VERSION ""

NS_ :

BS_:

BU_:

BO_ 58 SrlDat36_Prtctd_PDU: 20 Vector__XXX
 SG_ SD36P_MAC : 7|32@0+ (1,0) [0|4.29497e+009] "" ACP2_MCU,EOCM,EOCM_HC_Superset,FCM,E44
 SG_ SD36P_FCnt : 39|5@0+ (1,0) [0|31] "" ACP2_MCU,EOCM,EOCM_HC_Superset,FCM,E44
 SG_ DASTP_StrTrqAuth : 47|11@0- (0.01,0) [-10.24|10.23] "Nm" ACP2_MCU,EOCM,EOCM_HC_Superset,FCM,E44,ECP_E
 SG_ EPSOP_EPSOvrlyTrqDlvdAuth : 49|11@0- (0.01,0) [-10.24|10.23] "" ACP2_MCU,EOCM,EOCM_HC_Superset,FCM,E44
 SG_ DSIDP_DrvrStrgIntfrDtdAuth_Inv : 50|1@0+ (1,0) [0|1] "" ACP2_MCU,EOCM,EOCM_HC_Superset,FCM,E44
 SG_ DSIDP_DrvrStrgIntfrDtdAuth : 51|1@0+ (1,0) [0|1] "" ACP2_MCU,EOCM,EOCM_HC_Superset,FCM,E44
 SG_ DASTP_StrTrqAuth_Inv : 52|1@0+ (1,0) [0|1] "" ACP2_MCU,EOCM,EOCM_HC_Superset,FCM,E44,ECP_E
 SG_ EPSTTDP_TotTorqDlvdAuth : 66|11@0- (0.25,0) [-256|255.75] "" ACP2_MCU,EOCM,EOCM_HC_Superset,FCM,E44,ECP_E
 SG_ EPSOP_ElecPwStrgTqOvlyStsAuth : 69|3@0+ (1,0) [0|5] "" ACP2_MCU,EOCM,EOCM_HC_Superset,FCM,E44
 SG_ EPSOP_EPSOvrlyTrqDlvdAuth_Inv : 70|1@0+ (1,0) [0|1] "" ACP2_MCU,EOCM,EOCM_HC_Superset,FCM,E44
 SG_ SSASI2P_LKAStrgRqCommStsAuth : 81|2@0+ (1,0) [0|3] "" ACP2_MCU,EOCM,EOCM_HC_Superset,FCM,E44
 SG_ SSASI2P_ArbdASStrgRqCommStsAuth : 84|3@0+ (1,0) [0|5] "" ACP2_MCU,EOCM,EOCM_HC_Superset,FCM,E44
 SG_ SSASI2P_AE44StrgRqCommStsAuth : 86|2@0+ (1,0) [0|3] "" ACP2_MCU,EOCM,EOCM_HC_Superset,FCM,E44
 SG_ EPSTTDP_TotTorqDlvdAuth_Inv : 87|1@0+ (1,0) [0|1] "" ACP2_MCU,EOCM,EOCM_HC_Superset,FCM,E44,ECP_E
 SG_ SSASIP_StrgTrqReqOvlyAvalLtAuth : 89|10@0+ (0.01,0) [0|10.23] "Nm" ACP2_MCU,EOCM,EOCM_HC_Superset,FCM,E44
 SG_ SSASIP_StrgPerfActlModeAuth : 92|3@0+ (1,0) [0|7] "" ACP2_MCU,EOCM,EOCM_HC_Superset,FCM,E44
 SG_ SSASIP_StrgAsstThrmlInhbdAuth : 93|1@0+ (1,0) [0|1] "" ACP2_MCU,EOCM,EOCM_HC_Superset,FCM,E44
 SG_ SSASIP_StrgAsstStsAuth : 95|2@0+ (1,0) [0|2] "" ACP2_MCU,EOCM,EOCM_HC_Superset,FCM,E44
 SG_ SSASIP_StrgTrqReqOvlyAvalRtAuth : 111|10@0+ (0.01,-10.23) [-10.23|0] "Nm" ACP2_MCU,EOCM,EOCM_HC_Superset,FCM,E44
 SG_ SWHOP_ArbdStrgFtrReqActvAuth : 113|4@0+ (1,0) [0|10] "" ACP2_MCU,EOCM,EOCM_HC_Superset,FCM,E44
 SG_ SSASIP_StrgWhlTrqIntegStsAuth : 115|2@0+ (1,0) [0|3] "" ACP2_MCU,EOCM,EOCM_HC_Superset,FCM,E44
 SG_ SSASIP_StrgWhlAngIntegStsAuth : 117|2@0+ (1,0) [0|3] "" ACP2_MCU,EOCM,EOCM_HC_Superset,FCM,E44
 SG_ SWHOP_StrgWhlHndsOffDtnStatAuth : 121|2@0+ (1,0) [0|2] "" ACP2_MCU,EOCM,EOCM_HC_Superset,FCM,E44
 SG_ SWHOP_StrgWhlHndsOffDtnModeAuth : 123|2@0+ (1,0) [0|3] "" ACP2_MCU,EOCM,EOCM_HC_Superset,FCM,E44
 SG_ SWHOP_StrgWhlHndsOffDtnCnfdLvlAu : 125|2@0+ (1,0) [0|2] "" ACP2_MCU,EOCM,EOCM_HC_Superset,FCM,E44
 SG_ SD36P_Filler : 133|30@0+ (1,0) [0|1.07374e+009] "" ACP2_MCU,EOCM,EOCM_HC_Superset,FCM,E44
 SG_ SD36P_ARC : 135|2@0+ (1,0) [0|3] "" ACP2_MCU,EOCM,EOCM_HC_Superset,FCM,E44

BO_ 900 Message1126_PDU: 8 Vector__XXX
 SG_ Sig6868 : 7|64@0+ (1,0) [0|1.84467e+019] "" ADIMa,ADIMb,FOPM

BO_ 90 Message1127_PDU: 20 Vector__XXX
 SG_ Sig5735 : 7|32@0+ (1,0) [0|4.29497e+009] "" ADIMa,ADIMb,FOPM
 SG_ Sig5733 : 39|5@0+ (1,0) [0|31] "" ADIMa,ADIMb,FOPM
 SG_ Sig0315 : 47|13@0- (0.0625,0) [-256|255.938] "Amp" ADIMa,ADIMb,FOPM
 SG_ Sig0320 : 50|13@0+ (0.1,0) [0|819.1] "Deg" ADIMa,ADIMb,FOPM
 SG_ Sig0327 : 69|12@0+ (10,0) [0|40950] "N" ADIMa,ADIMb,FOPM
 SG_ Sig0323 : 73|11@0+ (2,0) [0|4094] "deg/s" ADIMa,ADIMb,FOPM
 SG_ Sig2544 : 94|11@0- (0.25,0) [-256|255.75] "" ADIMa,ADIMb,FOPM
 SG_ Sig0317 : 99|8@0+ (0.1,0) [0|25.5] "volts" ADIMa,ADIMb,FOPM
 SG_ Sig0319 : 104|3@0+ (1,0) [0|7] "" ADIMa,ADIMb,FOPM
 SG_ Sig0313 : 107|3@0+ (1,0) [0|5] "" ADIMa,ADIMb,FOPM
 SG_ Sig0325 : 112|2@0+ (1,0) [0|3] "" ADIMa,ADIMb,FOPM
 SG_ Sig0322 : 114|2@0+ (1,0) [0|3] "" ADIMa,ADIMb,FOPM
 SG_ Sig6953 : 117|3@0+ (1,0) [0|5] "" ADIMa,ADIMb,FOPM
 SG_ Sig0318 : 120|1@0+ (1,0) [0|1] "" ADIMa,ADIMb,FOPM
 SG_ Sig0316 : 121|1@0+ (1,0) [0|1] "" ADIMa,ADIMb,FOPM
 SG_ Sig0314 : 122|1@0+ (1,0) [0|1] "" ADIMa,ADIMb,FOPM
 SG_ Sig6956 : 124|2@0+ (1,0) [0|2] "" ADIMa,ADIMb,FOPM
 SG_ Sig0328 : 126|2@0+ (1,0) [0|3] "" ADIMa,ADIMb,FOPM
 SG_ Sig5734 : 131|26@0+ (1,0) [0|6.71089e+007] "" ADIMa,ADIMb,FOPM
 SG_ Sig2545 : 132|1@0+ (1,0) [0|1] "" ADIMa,ADIMb,FOPM
 SG_ Sig0326 : 133|1@0+ (1,0) [0|1] "" ADIMa,ADIMb,FOPM
 SG_ Sig0324 : 134|1@0+ (1,0) [0|1] "" ADIMa,ADIMb,FOPM
 SG_ Sig0321 : 135|1@0+ (1,0) [0|1] "" ADIMa,ADIMb,FOPM
 SG_ Sig5732 : 153|2@0+ (1,0) [0|3] "" ADIMa,ADIMb,FOPM

BO_ 1373 SrlDat3_PCSM_PDU: 8 Vector__XXX
 SG_ SrlDat3_PCSM : 7|64@0+ (1,0) [0|1.84467e+019] "" ACP2_MCU,ECM,EOCM,EOCM_HC_Superset,FCM,PCM,TCCM

BO_ 876 SrlDat3_Prtctd_PDU: 16 Vector__XXX
 SG_ SD3_MAC : 7|32@0+ (1,0) [0|4.29497e+009] "" ACP2_MCU,ECM,EOCM,EOCM_HC_Superset,FCM,PCM,TCCM
 SG_ SD3_FCnt : 39|5@0+ (1,0) [0|31] "" ACP2_MCU,ECM,EOCM,EOCM_HC_Superset,FCM,PCM,TCCM
 SG_ BVSCP_BdyCtlTopSpdLimReqTypAuth : 42|3@0+ (1,0) [0|6] "" ACP2_MCU,ECM,EOCM,EOCM_HC_Superset,FCM,PCM,TCCM
 SG_ BGI4P_AutoShtdnRstAuth : 43|1@0+ (1,0) [0|1] "" ACP2_MCU,ECM,EOCM,EOCM_HC_Superset,FCM,PCM,TCCM
 SG_ BGI4P_AutoShtdnAllwdAuth : 44|1@0+ (1,0) [0|1] "" ACP2_MCU,ECM,EOCM,EOCM_HC_Superset,FCM,PCM,TCCM
 SG_ BGI4P_AirDflctOffCycCrTkStAuth : 46|2@0+ (1,0) [0|3] "" ACP2_MCU,ECM,EOCM,EOCM_HC_Superset,FCM,PCM,TCCM
 SG_ BASHPLP_BrkSnsrHmPstnLrndAuth : 47|1@0+ (1,0) [0|1] "" ACP2_MCU,ECM,EOCM,EOCM_HC_Superset,FCM,PCM,TCCM
 SG_ BVSCP_BdyCtlTopSpdLimReqValAuth : 55|8@0+ (1,0) [0|255] "kph" ACP2_MCU,ECM,EOCM,EOCM_HC_Superset,FCM,PCM,TCCM
 SG_ DSIP_E44MSw3StkAuth : 56|1@0+ (1,0) [0|1] "" ACP2_MCU,ECM,EOCM,EOCM_HC_Superset,FCM,PCM,TCCM
 SG_ DSIP_E44MSw2StkAuth : 57|1@0+ (1,0) [0|1] "" ACP2_MCU,ECM,EOCM,EOCM_HC_Superset,FCM,PCM,TCCM
 SG_ DSIP_E44MSw1StkAuth : 58|1@0+ (1,0) [0|1] "" ACP2_MCU,ECM,EOCM,EOCM_HC_Superset,FCM,PCM,TCCM
 SG_ BdyCtlTopSpdLimSrcAuth : 61|3@0+ (1,0) [0|7] "" ACP2_MCU,ECM,EOCM,EOCM_HC_Superset,FCM,PCM,TCCM
 SG_ BdyCtlTopSpdLimIndOnAuth : 62|1@0+ (1,0) [0|1] "" ACP2_MCU,ECM,EOCM,EOCM_HC_Superset,FCM,PCM,TCCM
 SG_ BdyCtlAccelLimIndOnAuth : 63|1@0+ (1,0) [0|1] "" ACP2_MCU,ECM,EOCM,EOCM_HC_Superset,FCM,PCM,TCCM
 SG_ VCKIP_InfltblRstrntKeyIdfrAuth : 64|16@0+ (1,0) [0|65535] "Hex" ACP2_MCU,ECM,EOCM,EOCM_HC_Superset,FCM,PCM,TCCM
 SG_ RIP_FrtCmptRelEnblReqAuth : 66|2@0+ (1,0) [0|3] "" ACP2_MCU,ECM,EOCM,EOCM_HC_Superset,FCM,PCM,TCCM
 SG_ DSIP_E44MSwStsAuth : 69|3@0+ (1,0) [0|7] "" ACP2_MCU,ECM,EOCM,EOCM_HC_Superset,FCM,PCM,TCCM
 SG_ DSIP_E44MSwDrvrModeSwStkAuth : 70|1@0+ (1,0) [0|1] "" ACP2_MCU,ECM,EOCM,EOCM_HC_Superset,FCM,PCM,TCCM
 SG_ DSIP_E44MSw4StkAuth : 71|1@0+ (1,0) [0|1] "" ACP2_MCU,ECM,EOCM,EOCM_HC_Superset,FCM,PCM,TCCM
 SG_ SD3_ARC : 80|2@0+ (1,0) [0|3] "" ACP2_MCU,ECM,EOCM,EOCM_HC_Superset,FCM,PCM,TCCM
 SG_ SD3P_Filler : 93|31@0+ (1,0) [0|2.14748e+009] "" ACP2_MCU,ECM,EOCM,EOCM_HC_Superset,FCM,PCM,TCCM
 SG_ LoVltg12VBatMntModeReqd : 94|1@0+ (1,0) [0|1] "" ACP2_MCU,ECM,EOCM,EOCM_HC_Superset,FCM,PCM,TCCM
 SG_ SD3P_FillerExtnd : 126|7@0+ (1,0) [0|127] "" ACP2_MCU,ECM,EOCM,EOCM_HC_Superset,FCM,PCM,TCCM

BO_ 899 SrlDat40_PCSM_PDU: 8 Vector__XXX
 SG_ SrlDat40_PCSM : 7|64@0+ (1,0) [0|1.84467e+019] "" EBCM,EPS,EPSb

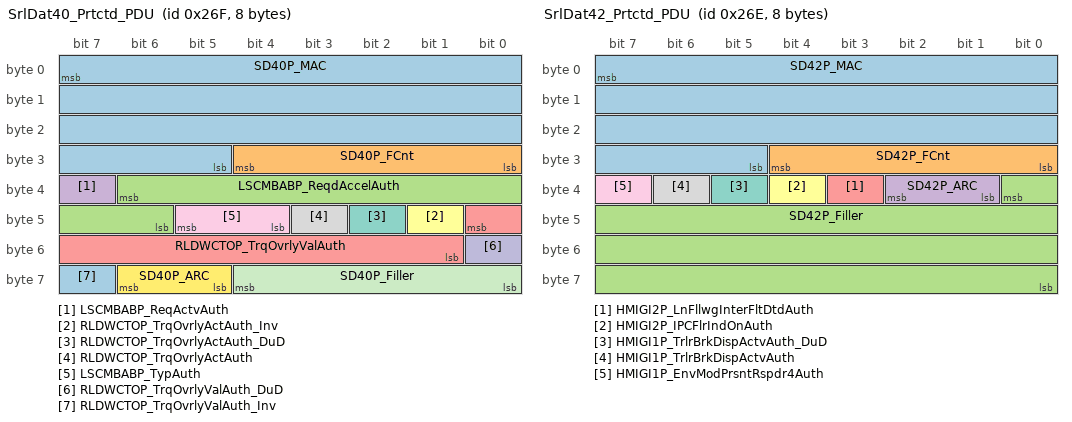
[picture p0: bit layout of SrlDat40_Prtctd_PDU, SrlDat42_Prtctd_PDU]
BO_ 623 SrlDat40_Prtctd_PDU: 8 Vector__XXX
 SG_ SD40P_MAC : 7|27@0+ (1,0) [0|1.34218e+008] "" CGM,EBCM,EPS,EPSb
 SG_ SD40P_FCnt : 28|5@0+ (1,0) [0|31] "" CGM,EBCM,EPS,EPSb
 SG_ LSCMBABP_ReqdAccelAuth : 38|9@0- (0.1,0) [-25.6|25.5] "" CGM,EBCM,EPS,EPSb
 SG_ LSCMBABP_ReqActvAuth : 39|1@0+ (1,0) [0|1] "" CGM,EBCM,EPS,EPSb
 SG_ RLDWCTOP_TrqOvrlyValAuth : 40|8@0- (0.1,0) [-12.8|12.7] "" CGM,EBCM,EPS,EPSb
 SG_ RLDWCTOP_TrqOvrlyActAuth_Inv : 41|1@0+ (1,0) [0|1] "" CGM,EBCM,EPS,EPSb
 SG_ RLDWCTOP_TrqOvrlyActAuth_DuD : 42|1@0+ (1,0) [0|1] "" CGM,EBCM,EPS,EPSb
 SG_ RLDWCTOP_TrqOvrlyActAuth : 43|1@0+ (1,0) [0|1] "" CGM,EBCM,EPS,EPSb
 SG_ LSCMBABP_TypAuth : 45|2@0+ (1,0) [0|2] "" CGM,EBCM,EPS,EPSb
 SG_ RLDWCTOP_TrqOvrlyValAuth_DuD : 48|1@0+ (1,0) [0|1] "" CGM,EBCM,EPS,EPSb
 SG_ SD40P_Filler : 60|5@0+ (1,0) [0|31] "" CGM,EBCM,EPS,EPSb
 SG_ SD40P_ARC : 62|2@0+ (1,0) [0|3] "" CGM,EBCM,EPS,EPSb
 SG_ RLDWCTOP_TrqOvrlyValAuth_Inv : 63|1@0+ (1,0) [0|1] "" CGM,EBCM,EPS,EPSb

BO_ 898 SrlDat42_PCSM_PDU: 8 Vector__XXX
 SG_ SrlDat42_PCSM : 7|64@0+ (1,0) [0|1.84467e+019] "" ACP2_MCU,EBCM,EOCM,EOCM_HC_Superset

BO_ 622 SrlDat42_Prtctd_PDU: 8 Vector__XXX
 SG_ SD42P_MAC : 7|27@0+ (1,0) [0|1.34218e+008] "" ACP2_MCU,EBCM,EOCM,EOCM_HC_Superset
 SG_ SD42P_FCnt : 28|5@0+ (1,0) [0|31] "" ACP2_MCU,EBCM,EOCM,EOCM_HC_Superset
 SG_ SD42P_Filler : 32|25@0+ (1,0) [0|3.35544e+007] "" ACP2_MCU,EBCM,EOCM,EOCM_HC_Superset
 SG_ SD42P_ARC : 34|2@0+ (1,0) [0|3] "" ACP2_MCU,EBCM,EOCM,EOCM_HC_Superset
 SG_ HMIGI2P_LnFllwgInterFltDtdAuth : 35|1@0+ (1,0) [0|1] "" ACP2_MCU,EBCM,EOCM,EOCM_HC_Superset
 SG_ HMIGI2P_IPCFlrIndOnAuth : 36|1@0+ (1,0) [0|1] "" ACP2_MCU,EBCM,EOCM,EOCM_HC_Superset
 SG_ HMIGI1P_TrlrBrkDispActvAuth_DuD : 37|1@0+ (1,0) [0|1] "" ACP2_MCU,EBCM,EOCM,EOCM_HC_Superset
 SG_ HMIGI1P_TrlrBrkDispActvAuth : 38|1@0+ (1,0) [0|1] "" ACP2_MCU,EBCM,EOCM,EOCM_HC_Superset
 SG_ HMIGI1P_EnvModPrsntRspdr4Auth : 39|1@0+ (1,0) [0|1] "" ACP2_MCU,EBCM,EOCM,EOCM_HC_Superset

BO_ 1372 SrlDat43_PCSM_PDU: 8 Vector__XXX
 SG_ SrlDat43_PCSM : 7|64@0+ (1,0) [0|1.84467e+019] "" ECM,PCM,ECP_E

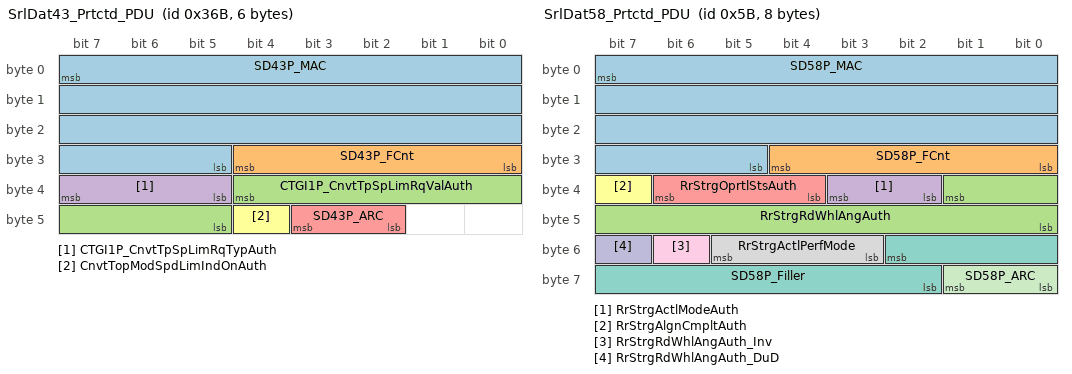
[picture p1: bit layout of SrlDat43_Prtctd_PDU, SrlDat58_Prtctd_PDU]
BO_ 875 SrlDat43_Prtctd_PDU: 6 Vector__XXX
 SG_ SD43P_MAC : 7|27@0+ (1,0) [0|1.34218e+008] "" ECM,PCM,ECP_E
 SG_ SD43P_FCnt : 28|5@0+ (1,0) [0|31] "" ECM,PCM,ECP_E
 SG_ CTGI1P_CnvtTpSpLimRqValAuth : 36|8@0+ (2,0) [0|510] "kph" ECM,PCM,ECP_E
 SG_ CTGI1P_CnvtTpSpLimRqTypAuth : 39|3@0+ (1,0) [0|6] "" ECM,PCM,ECP_E
 SG_ SD43P_ARC : 43|2@0+ (1,0) [0|3] "" ECM,PCM,ECP_E
 SG_ CnvtTopModSpdLimIndOnAuth : 44|1@0+ (1,0) [0|1] "" ECM,PCM,ECP_E

BO_ 664 SrlDat44_PCSM_PDU: 8 Vector__XXX
 SG_ SrlDat44_PCSM : 7|64@0+ (1,0) [0|1.84467e+019] "" ECP_E

BO_ 53 SrlDat44_Prtctd_PDU: 24 Vector__XXX
 SG_ SD44P_MAC : 7|32@0+ (1,0) [0|4.29497e+009] "" ECP_E
 SG_ SD44P_FCnt : 39|5@0+ (1,0) [0|31] "" ECP_E
 SG_ SSID1P_LatAccelAuth : 47|10@0- (0.0625,0) [-32|31.9375] "m/s2" ECP_E
 SG_ SSID1P_LngAccelAuth : 52|10@0- (0.0625,0) [-32|31.9375] "m/s2" ECP_E
 SG_ SSID1P_LatAccelAuth_Inv : 53|1@0+ (1,0) [0|1] "" ECP_E
 SG_ SSID2P_PtchRateAuth : 57|12@0- (0.061,0) [-124.928|124.867] "deg/sec" ECP_E
 SG_ SSID1P_LngAccelAuth_Inv : 58|1@0+ (1,0) [0|1] "" ECP_E
 SG_ SSID2P_VertAccelAuth : 76|11@0+ (0.0527,-59) [-59|48.8769] "m/s2" ECP_E
 SG_ SSID2P_PtchRateAuth_Inv : 77|1@0+ (1,0) [0|1] "" ECP_E
 SG_ SSID3P_RollRateAuth : 80|12@0- (0.061,0) [-124.928|124.867] "deg/sec" ECP_E
 SG_ SSID2P_VertAccelAuth_Inv : 81|1@0+ (1,0) [0|1] "" ECP_E
 SG_ SSID3P_YawRateAuth : 99|12@0- (0.061,0) [-124.928|124.867] "deg/sec" ECP_E
 SG_ SSID3P_RollRateAuth_Inv : 100|1@0+ (1,0) [0|1] "" ECP_E
 SG_ SSID4P_LFAuth : 118|11@0+ (0.144,-157) [-157|137.768] "m/s2" ECP_E
 SG_ SSID3P_YawRateAuth_Inv : 119|1@0+ (1,0) [0|1] "" ECP_E
 SG_ SSID4P_RFAuth : 122|11@0+ (0.144,-157) [-157|137.768] "m/s2" ECP_E
 SG_ SSID4P_LFAuth_Inv : 123|1@0+ (1,0) [0|1] "" ECP_E
 SG_ SSID5P_LRAuth : 142|11@0+ (0.144,-157) [-157|137.768] "m/s2" ECP_E
 SG_ SSID4P_RFAuth_Inv : 143|1@0+ (1,0) [0|1] "" ECP_E
 SG_ SSID5P_RRAuth : 146|11@0+ (0.144,-157) [-157|137.768] "m/s2" ECP_E
 SG_ SSID5P_LRAuth_Inv : 147|1@0+ (1,0) [0|1] "" ECP_E
 SG_ SD44P_Filler : 164|29@0+ (1,0) [0|5.36871e+008] "" ECP_E
 SG_ SD44P_ARC : 166|2@0+ (1,0) [0|3] "" ECP_E
 SG_ SSID5P_RRAuth_Inv : 167|1@0+ (1,0) [0|1] "" ECP_E

BO_ 897 SrlDat46_PCSM_PDU: 8 Vector__XXX
 SG_ SrlDat46_PCSM : 7|64@0+ (1,0) [0|1.84467e+019] "" ADIMa,ADIMb,AHL_AFL,AHS,ARS,EPSRAa,EPS,EPSb,FCM,RDCM,TCCM,ECP_E,ECP_S

BO_ 57 SrlDat46_Prtctd_PDU: 20 Vector__XXX
 SG_ SD46P_MAC : 7|32@0+ (1,0) [0|4.29497e+009] "" ADIMa,ADIMb,AHL_AFL,AHS,ARS,EPSRAa,EPS,EPSb,FCM,RDCM,TCCM,ECP_E,ECP_S
 SG_ SD46P_FCnt : 39|5@0+ (1,0) [0|31] "" ADIMa,ADIMb,AHL_AFL,AHS,ARS,EPSRAa,EPS,EPSb,FCM,RDCM,TCCM,ECP_E,ECP_S
 SG_ LatAccelAuth : 47|10@0- (0.0625,0) [-32|31.9375] "m/s^2" ADIMa,ADIMb,AHL_AFL,AHS,ARS,DCM,ECM,EPSRAa,EPS,EPSb,FCM,NVM,PCM,RDCM,TCCM,TCM,ECP_E,ECP_S
 SG_ LongAccelAuth : 50|10@0- (0.0625,0) [-32|31.9375] "m/s^2" ADIMa,ADIMb,AHL_AFL,AHS,ARS,DCM,ECM,EPSRAa,EPS,EPSb,FCM,NVM,PCM,RDCM,TCCM,TCM,ECP_E,ECP_S
 SG_ LatAccelSnsrCorrStsAuth : 52|2@0+ (1,0) [0|3] "" ADIMa,ADIMb,AHL_AFL,AHS,ARS,ECM,EPSRAa,EPS,EPSb,FCM,PCM,RDCM,TCCM,TCM,ECP_E,ECP_S
 SG_ LatAccelAuth_Inv : 53|1@0+ (1,0) [0|1] "" ADIMa,ADIMb,AHL_AFL,AHS,ARS,DCM,ECM,EPSRAa,EPS,EPSb,FCM,NVM,PCM,RDCM,TCCM,TCM,ECP_E,ECP_S
 SG_ LongAccelAuth_Inv : 56|1@0+ (1,0) [0|1] "" ADIMa,ADIMb,AHL_AFL,AHS,ARS,DCM,ECM,EPSRAa,EPS,EPSb,FCM,NVM,PCM,RDCM,TCCM,TCM,ECP_E,ECP_S
 SG_ YRP_RollRateAuth : 68|13@0- (0.024,0) [-98.304|98.28] "Deg/Sec" ADIMa,ADIMb,AHL_AFL,AHS,ARS,EPSRAa,EPS,EPSb,FCM,RDCM,TCCM,ECP_E,ECP_S
 SG_ VehAccelCalAuth : 69|1@0+ (1,0) [0|1] "" ADIMa,ADIMb,AHL_AFL,AHS,ARS,ECM,EPSRAa,EPS,EPSb,FCM,PCM,RDCM,TCCM,TCM,ECP_E,ECP_S
 SG_ LongAccelSnsrCorrStsAuth : 71|2@0+ (1,0) [0|3] "" ADIMa,ADIMb,AHL_AFL,AHS,ARS,ECM,EPSRAa,EPS,EPSb,FCM,PCM,RDCM,TCCM,TCM,ECP_E,ECP_S
 SG_ YawRateAuth : 85|13@0- (0.024,0) [-98.304|98.28] "Deg/Sec" ADIMa,ADIMb,AHL_AFL,AHS,ARS,DCM,EPSRAa,EPS,EPSb,FCM,PCM,RDCM,TCCM,TCM,ECP_E,ECP_S
 SG_ YRP_RollRateAuth_Inv : 86|1@0+ (1,0) [0|1] "" ADIMa,ADIMb,AHL_AFL,AHS,ARS,EPSRAa,EPS,EPSb,FCM,RDCM,TCCM,ECP_E,ECP_S
 SG_ YRP_RollRateAuth_DuD : 87|1@0+ (1,0) [0|1] "" ADIMa,ADIMb,AHL_AFL,AHS,ARS,EPSRAa,EPS,EPSb,FCM,RDCM,TCCM,ECP_E,ECP_S
 SG_ YawRateAuth_DuD : 88|1@0+ (1,0) [0|1] "" ADIMa,ADIMb,AHL_AFL,AHS,ARS,EPSRAa,EPS,EPSb,FCM,PCM,RDCM,TCCM,TCM,ECP_E,ECP_S
 SG_ SD46P_Filler : 98|32@0+ (1,0) [0|4.29497e+009] "" ADIMa,ADIMb,AHL_AFL,AHS,ARS,EPSRAa,EPS,EPSb,FCM,RDCM,TCCM,ECP_E,ECP_S
 SG_ SD46P_ARC : 100|2@0+ (1,0) [0|3] "" ADIMa,ADIMb,AHL_AFL,AHS,ARS,EPSRAa,EPS,EPSb,FCM,RDCM,TCCM,ECP_E,ECP_S
 SG_ YawRateCorrAuth : 102|2@0+ (1,0) [0|3] "" ADIMa,ADIMb,AHL_AFL,AHS,ARS,EPSRAa,EPS,EPSb,FCM,PCM,RDCM,TCCM,TCM,ECP_E,ECP_S
 SG_ YawRateAuth_Inv : 103|1@0+ (1,0) [0|1] "" ADIMa,ADIMb,AHL_AFL,AHS,ARS,DCM,EPSRAa,EPS,EPSb,FCM,PCM,RDCM,TCCM,TCM,ECP_E,ECP_S
 SG_ SD46P_FillerExtnd : 130|26@0+ (1,0) [0|6.71089e+007] "" ADIMa,ADIMb,AHL_AFL,AHS,ARS,EPSRAa,EPS,EPSb,FCM,RDCM,TCCM,ECP_E,ECP_S
 SG_ VehAccelAuth_DuD : 152|1@0+ (1,0) [0|1] "" ADIMa,ADIMb,AHL_AFL,AHS,ARS,ECM,EPSRAa,EPS,EPSb,FCM,PCM,RDCM,TCCM,TCM,ECP_E,ECP_S

BO_ 896 SrlDat47_PCSM_PDU: 8 Vector__XXX
 SG_ SrlDat47_PCSM : 7|64@0+ (1,0) [0|1.84467e+019] "" ECM,PCM,TCM,ECP_X1

BO_ 185 SrlDat47_Prtctd_PDU: 12 Vector__XXX
 SG_ SD47P_MAC : 7|32@0+ (1,0) [0|4.29497e+009] "" ECM,PCM,TCM,ECP_X1
 SG_ SD47P_FCnt : 39|5@0+ (1,0) [0|31] "" ECM,PCM,TCM,ECP_X1
 SG_ LatAccelRwAuth : 47|16@0- (0.000122,0) [-3.9977|3.99757] "g" ECM,PCM,TCM,ECP_X1
 SG_ LngAccelRwAuth : 63|16@0- (0.000122,0) [-3.9977|3.99757] "g" ECM,PCM,TCM,ECP_X1
 SG_ SD47P_Filler : 77|22@0+ (1,0) [0|4.1943e+006] "" ECM,PCM,TCM,ECP_X1
 SG_ SD47P_ARC : 79|2@0+ (1,0) [0|3] "" ECM,PCM,TCM,ECP_X1

BO_ 895 Message1130_PDU: 8 Vector__XXX
 SG_ Sig6870 : 7|64@0+ (1,0) [0|1.84467e+019] "" ECM,TCCM

BO_ 46 SrlDat48_Prtctd_PDU: 32 Vector__XXX
 SG_ Sig5744 : 7|32@0+ (1,0) [0|4.29497e+009] "" ECM,TCCM
 SG_ Sig5741 : 39|5@0+ (1,0) [0|31] "" ECM,TCCM
 SG_ Sig0608 : 47|11@0+ (0.00390625,0) [0|7.99609] "" ECM,TCCM
 SG_ Sig0611 : 52|11@0+ (0.00390625,0) [0|7.99609] "" ECM,TCCM
 SG_ Sig7523 : 57|2@0+ (1,0) [0|2] "" ECM,TCCM
 SG_ Sig7524 : 71|12@0+ (0.5,-848) [-848|1199.5] "Nm" ECM,TCCM
 SG_ Sig7526 : 73|2@0+ (1,0) [0|2] "" ECM,TCCM
 SG_ Sig7525 : 75|2@0+ (1,0) [0|3] "" ECM,TCCM
 SG_ Sig7527 : 87|12@0+ (0.5,-848) [-848|1199.5] "Nm" ECM,TCCM
 SG_ Sig7531 : 89|2@0+ (1,0) [0|3] "" ECM,TCCM
 SG_ Sig7530 : 91|2@0+ (1,0) [0|3] "" ECM,TCCM
 SG_ Sig7532 : 103|10@0+ (8,0) [0|8184] "rpm" ECM,TCCM
 SG_ TGIP_TransGrRatAuth : 109|11@0+ (0.00390625,0) [0|7.99609] "0" VICM,ECM,RDCM,TCCM,ECP_X1
 SG_ TGIP_TransGrRatStatAuth : 113|3@0+ (1,0) [0|5] "" VICM,ECM,RDCM,TCCM,ECP_X1
 SG_ TGIP_TransGrRatAuth_Inv : 114|1@0+ (1,0) [0|1] "" VICM,ECM,RDCM,TCCM,ECP_X1
 SG_ Sig7549 : 124|10@0+ (1,0) [0|1023] "counts" ECM,TCCM
 SG_ Sig7548 : 126|2@0+ (1,0) [0|3] "" ECM,TCCM
 SG_ Sig7552 : 128|16@0+ (1,0) [0|65535] "counts" ECM,TCCM
 SG_ Sig7551 : 129|1@0+ (1,0) [0|1] "" ECM,TCCM
 SG_ Sig7550 : 130|1@0+ (1,0) [0|1] "" ECM,TCCM
 SG_ TORSP_TransOutRotnDirAuth : 144|2@0+ (1,0) [0|3] "" EBCM,ECM,TCCM
 SG_ Sig7575 : 154|16@0+ (0.25,0) [0|16383.8] "rpm" ECM,TCCM
 SG_ Sig7574 : 155|1@0+ (1,0) [0|1] "" ECM,TCCM
 SG_ Sig7573 : 156|1@0+ (1,0) [0|1] "" ECM,TCCM
 SG_ Sig7572 : 157|1@0+ (1,0) [0|1] "" ECM,TCCM
 SG_ Sig7571 : 158|1@0+ (1,0) [0|1] "" ECM,TCCM
 SG_ Sig7632 : 169|12@0+ (0.25,0) [0|1023.75] "Nm" ECM,TCCM
 SG_ Sig7576 : 170|1@0+ (1,0) [0|1] "" ECM,TCCM
 SG_ Sig0638 : 185|11@0+ (0.00390625,0) [0|7.99609] "" ECM,TCCM
 SG_ Sig5740 : 187|2@0+ (1,0) [0|3] "" ECM,TCCM
 SG_ Sig7634 : 188|1@0+ (1,0) [0|1] "" ECM,TCCM
 SG_ Sig7633 : 189|1@0+ (1,0) [0|1] "" ECM,TCCM
 SG_ Sig7582 : 202|17@0+ (0.125,0) [0|16383.9] "" ECM,TCCM
 SG_ Sig7581 : 204|2@0+ (1,0) [0|3] "" ECM,TCCM
 SG_ Sig7580 : 206|2@0+ (1,0) [0|3] "" ECM,TCCM
 SG_ Sig7625 : 217|12@0+ (1,-848) [-848|3247] "Nm" ECM,TCCM
 SG_ Sig7627 : 237|12@0+ (1,-848) [-848|3247] "Nm" ECM,TCCM
 SG_ Sig7623 : 241|2@0+ (1,0) [0|2] "" ECM,TCCM
 SG_ Sig5742 : 249|2@0+ (1,0) [0|3] "" ECM,TCCM
 SG_ Sig5743 : 251|2@0+ (1,0) [0|3] "" ECM,TCCM
 SG_ Sig7626 : 253|2@0+ (1,0) [0|2] "" ECM,TCCM
 SG_ Sig7624 : 255|2@0+ (1,0) [0|3] "" ECM,TCCM

BO_ 894 SrlDat50_PCSM_PDU: 8 Vector__XXX
 SG_ SrlDat50_PCSM : 7|64@0+ (1,0) [0|1.84467e+019] "" ECP_E,ECP_S,ECP_S2

BO_ 102 SrlDat50_Prtctd_PDU: 16 Vector__XXX
 SG_ SD50P_MAC : 7|32@0+ (1,0) [0|4.29497e+009] "" ECP_E,ECP_S,ECP_S2
 SG_ SD50P_FCnt : 39|5@0+ (1,0) [0|31] "" ECP_E,ECP_S,ECP_S2
 SG_ VICMI3P_AccPPS1OORFltAuth : 40|1@0+ (1,0) [0|1] "" ECP_E,ECP_S,ECP_S2
 SG_ VICMI3P_AccPPS1OORErrCmpstAuth : 41|1@0+ (1,0) [0|1] "" ECP_E,ECP_S,ECP_S2
 SG_ EDActr4DischrgCmdAuth : 44|3@0+ (1,0) [0|3] "" ECP_E,ECP_S,ECP_S2
 SG_ EDActr3DischrgCmdAuth : 47|3@0+ (1,0) [0|3] "" ECP_E,ECP_S,ECP_S2
 SG_ VICMI3P_ArbdAccPPPriAuth : 50|10@0+ (0.0976563,0) [0|99.9023] "%" CGM,ECP_E,ECP_S,ECP_S2
 SG_ VICMI3P_AccPPS2OORFltCmpstAuth : 51|1@0+ (1,0) [0|1] "" ECP_E,ECP_S,ECP_S2
 SG_ VICMI3P_AccPPS2OORErrCmpstAuth : 52|1@0+ (1,0) [0|1] "" ECP_E,ECP_S,ECP_S2
 SG_ VICMI3P_AccPPS1n2DsgrFltAuth : 53|1@0+ (1,0) [0|1] "" ECP_E,ECP_S,ECP_S2
 SG_ VICMI3P_AccPPS1n2DsgrErrAuth : 54|1@0+ (1,0) [0|1] "" ECP_E,ECP_S,ECP_S2
 SG_ VICMI3P_AccPPS1OORFltCmpstAuth : 55|1@0+ (1,0) [0|1] "" ECP_E,ECP_S,ECP_S2
 SG_ VICMI3P_ArbdAccPPRedntFltAuth : 56|1@0+ (1,0) [0|1] "" ECP_E,ECP_S,ECP_S2
 SG_ PrplSysInvrtACoolTempAuth : 68|9@0+ (0.5,-40) [-40|215.5] "Deg C" ECP_E,ECP_S,ECP_S2
 SG_ ElecTransRngHVBkupSplyFltPrAuth : 69|1@0+ (1,0) [0|1] "" ECP_E,ECP_S,ECP_S2
 SG_ SD50P_ARC : 71|2@0+ (1,0) [0|3] "" ECP_E,ECP_S,ECP_S2
 SG_ PrplSysInvrtBCoolTempAuth : 74|9@0+ (0.5,-40) [-40|215.5] "Deg C" ECP_E,ECP_S,ECP_S2
 SG_ PrplSysInvrtACoolTempAuth_Inv : 75|1@0+ (1,0) [0|1] "" ECP_E,ECP_S,ECP_S2
 SG_ PrplSysInvrtCCoolTempAuth : 80|9@0+ (0.5,-40) [-40|215.5] "Deg C" ECP_E,ECP_S,ECP_S2
 SG_ PrplSysInvrtBCoolTempAuth_Inv : 81|1@0+ (1,0) [0|1] "" ECP_E,ECP_S,ECP_S2
 SG_ SD50P_Filler : 102|31@0+ (1,0) [0|2.14748e+009] "" ECP_E,ECP_S,ECP_S2
 SG_ PrplSysInvrtCCoolTempAuth_Inv : 103|1@0+ (1,0) [0|1] "" ECP_E,ECP_S,ECP_S2

BO_ 96 SrlDat57_Prtctd_PDU: 8 Vector__XXX
 SG_ PrplSysMtrASpdAuth : 39|16@0- (1,0) [-32768|32767] "RPM" BSM,CGM
 SG_ PrplSysMtrASpdAuth_Inv : 55|1@0+ (1,0) [0|1] "" BSM,CGM

BO_ 893 SrlDat58_PCSM_PDU: 8 Vector__XXX
 SG_ SrlDat58_PCSM : 7|64@0+ (1,0) [0|1.84467e+019] "" ACP2_MCU,EBCM,EOCM,EOCM_HC_Superset,FCM,E44,ECP_E

BO_ 91 SrlDat58_Prtctd_PDU: 8 Vector__XXX
 SG_ SD58P_MAC : 7|27@0+ (1,0) [0|1.34218e+008] "" ACP2_MCU,CGM,EBCM,EOCM,EOCM_HC_Superset,FCM,E44,ECP_E
 SG_ SD58P_FCnt : 28|5@0+ (1,0) [0|31] "" ACP2_MCU,CGM,EBCM,EOCM,EOCM_HC_Superset,FCM,E44,ECP_E
 SG_ RrStrgRdWhlAngAuth : 33|10@0- (0.0625,0) [-32|31.9375] "deg" ACP2_MCU,CGM,EBCM,EOCM,EOCM_HC_Superset,FCM,E44,ECP_E
 SG_ RrStrgActlModeAuth : 35|2@0+ (1,0) [0|3] "" ACP2_MCU,CGM,EBCM,EOCM,EOCM_HC_Superset,FCM,E44,ECP_E
 SG_ RrStrgOprtlStsAuth : 38|3@0+ (1,0) [0|6] "" ACP2_MCU,CGM,EBCM,EOCM,EOCM_HC_Superset,FCM,E44,ECP_E
 SG_ RrStrgAlgnCmpltAuth : 39|1@0+ (1,0) [0|1] "" ACP2_MCU,CGM,EBCM,EOCM,EOCM_HC_Superset,FCM,E44,ECP_E
 SG_ SD58P_Filler : 50|9@0+ (1,0) [0|511] "" ACP2_MCU,CGM,EBCM,EOCM,EOCM_HC_Superset,FCM,E44,ECP_E
 SG_ RrStrgActlPerfMode : 53|3@0+ (1,0) [0|7] "" ACP2_MCU,CGM,EBCM,EOCM,EOCM_HC_Superset,FCM,E44,ECP_E
 SG_ RrStrgRdWhlAngAuth_Inv : 54|1@0+ (1,0) [0|1] "" ACP2_MCU,CGM,EBCM,EOCM,EOCM_HC_Superset,FCM,E44,ECP_E
 SG_ RrStrgRdWhlAngAuth_DuD : 55|1@0+ (1,0) [0|1] "" ACP2_MCU,CGM,EBCM,EOCM,EOCM_HC_Superset,FCM,E44,ECP_E
 SG_ SD58P_ARC : 57|2@0+ (1,0) [0|3] "" ACP2_MCU,CGM,EBCM,EOCM,EOCM_HC_Superset,FCM,E44,ECP_E

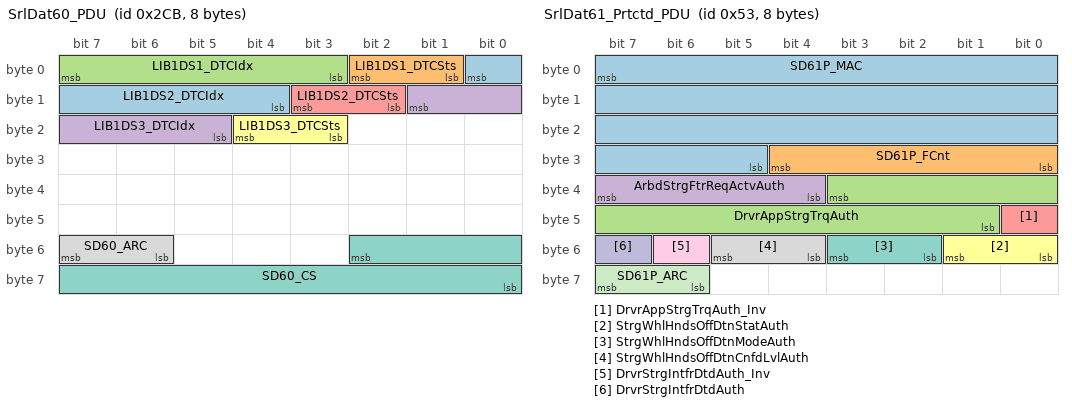
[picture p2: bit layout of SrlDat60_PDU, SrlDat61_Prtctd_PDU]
BO_ 715 SrlDat60_PDU: 8 Vector__XXX
 SG_ LIB1DS2_DTCIdx : 0|5@0+ (1,0) [0|31] "Count" FOPM
 SG_ LIB1DS1_DTCSts : 2|2@0+ (1,0) [0|3] "" FOPM
 SG_ LIB1DS1_DTCIdx : 7|5@0+ (1,0) [0|31] "Count" FOPM
 SG_ LIB1DS3_DTCIdx : 9|5@0+ (1,0) [0|31] "Count" FOPM
 SG_ LIB1DS2_DTCSts : 11|2@0+ (1,0) [0|3] "" FOPM
 SG_ LIB1DS3_DTCSts : 20|2@0+ (1,0) [0|3] "" FOPM
 SG_ SD60_CS : 50|11@0+ (1,0) [0|2047] "" FOPM
 SG_ SD60_ARC : 55|2@0+ (1,0) [0|3] "" FOPM

BO_ 680 SrlDat61_PCSM_PDU: 8 Vector__XXX
 SG_ SrlDat61_PCSM : 7|64@0+ (1,0) [0|1.84467e+019] "" ACP2_MCU,EOCM,EOCM_HC_Superset,FCM

BO_ 83 SrlDat61_Prtctd_PDU: 8 Vector__XXX
 SG_ SD61P_MAC : 7|27@0+ (1,0) [0|1.34218e+008] "" ACP2_MCU,EOCM,EOCM_HC_Superset,FCM
 SG_ SD61P_FCnt : 28|5@0+ (1,0) [0|31] "" ACP2_MCU,EOCM,EOCM_HC_Superset,FCM
 SG_ DrvrAppStrgTrqAuth : 35|11@0- (0.01,0) [-10.24|10.23] "Nm" ACP2_MCU,ADIMa,ADIMb,EOCM,EOCM_HC_Superset,FCM,ECP_E
 SG_ ArbdStrgFtrReqActvAuth : 39|4@0+ (1,0) [0|10] "" ACP2_MCU,EOCM,EOCM_HC_Superset,FCM
 SG_ DrvrAppStrgTrqAuth_Inv : 40|1@0+ (1,0) [0|1] "" ACP2_MCU,ADIMa,ADIMb,EOCM,EOCM_HC_Superset,FCM,ECP_E
 SG_ StrgWhlHndsOffDtnStatAuth : 49|2@0+ (1,0) [0|2] "" ACP2_MCU,EOCM,EOCM_HC_Superset,FCM
 SG_ StrgWhlHndsOffDtnModeAuth : 51|2@0+ (1,0) [0|3] "" ACP2_MCU,EOCM,EOCM_HC_Superset,FCM
 SG_ StrgWhlHndsOffDtnCnfdLvlAuth : 53|2@0+ (1,0) [0|2] "" ACP2_MCU,EOCM,EOCM_HC_Superset,FCM
 SG_ DrvrStrgIntfrDtdAuth_Inv : 54|1@0+ (1,0) [0|1] "" ACP2_MCU,EOCM,EOCM_HC_Superset,FCM
 SG_ DrvrStrgIntfrDtdAuth : 55|1@0+ (1,0) [0|1] "" ACP2_MCU,EOCM,EOCM_HC_Superset,FCM
 SG_ SD61P_ARC : 63|2@0+ (1,0) [0|3] "" ACP2_MCU,EOCM,EOCM_HC_Superset,FCM

BO_ 679 SrlDat62_PCSM_PDU: 8 Vector__XXX
 SG_ SrlDat62_PCSM : 7|64@0+ (1,0) [0|1.84467e+019] "" ACP2_MCU,EOCM,EOCM_HC_Superset,FCM

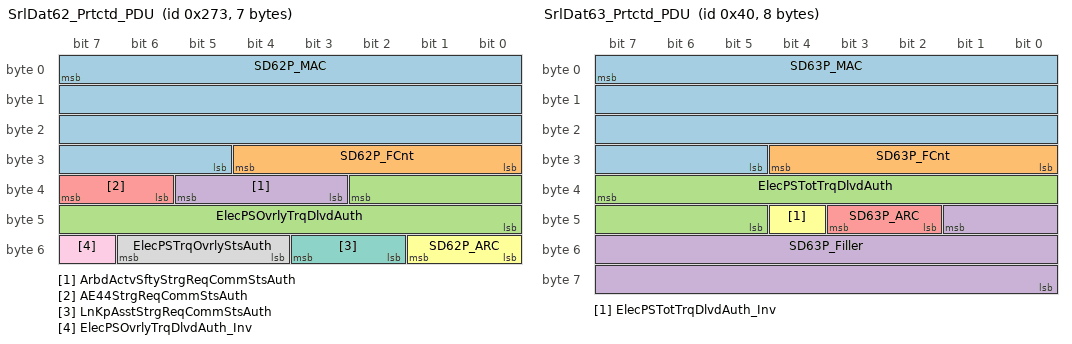
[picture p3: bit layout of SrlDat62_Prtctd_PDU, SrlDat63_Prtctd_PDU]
BO_ 627 SrlDat62_Prtctd_PDU: 7 Vector__XXX
 SG_ SD62P_MAC : 7|27@0+ (1,0) [0|1.34218e+008] "" ACP2_MCU,EOCM,EOCM_HC_Superset,FCM
 SG_ SD62P_FCnt : 28|5@0+ (1,0) [0|31] "" ACP2_MCU,EOCM,EOCM_HC_Superset,FCM
 SG_ ElecPSOvrlyTrqDlvdAuth : 34|11@0- (0.01,0) [-10.24|10.23] "" ACP2_MCU,EOCM,EOCM_HC_Superset,FCM
 SG_ ArbdActvSftyStrgReqCommStsAuth : 37|3@0+ (1,0) [0|5] "" ACP2_MCU,EOCM,EOCM_HC_Superset,FCM
 SG_ AE44StrgReqCommStsAuth : 39|2@0+ (1,0) [0|3] "" ACP2_MCU,EOCM,EOCM_HC_Superset,FCM
 SG_ SD62P_ARC : 49|2@0+ (1,0) [0|3] "" ACP2_MCU,EOCM,EOCM_HC_Superset,FCM
 SG_ LnKpAsstStrgReqCommStsAuth : 51|2@0+ (1,0) [0|3] "" ACP2_MCU,EOCM,EOCM_HC_Superset,FCM
 SG_ ElecPSTrqOvrlyStsAuth : 54|3@0+ (1,0) [0|5] "" ACP2_MCU,EOCM,EOCM_HC_Superset,FCM
 SG_ ElecPSOvrlyTrqDlvdAuth_Inv : 55|1@0+ (1,0) [0|1] "" ACP2_MCU,EOCM,EOCM_HC_Superset,FCM

BO_ 678 SrlDat63_PCSM_PDU: 8 Vector__XXX
 SG_ SrlDat63_PCSM : 7|64@0+ (1,0) [0|1.84467e+019] "" ACP2_MCU,EOCM,EOCM_HC_Superset,FCM

BO_ 64 SrlDat63_Prtctd_PDU: 8 Vector__XXX
 SG_ SD63P_MAC : 7|27@0+ (1,0) [0|1.34218e+008] "" ACP2_MCU,EOCM,EOCM_HC_Superset,FCM
 SG_ SD63P_FCnt : 28|5@0+ (1,0) [0|31] "" ACP2_MCU,EOCM,EOCM_HC_Superset,FCM
 SG_ ElecPSTotTrqDlvdAuth : 39|11@0- (0.25,0) [-256|255.75] "" ACP2_MCU,ADIMa,ADIMb,EOCM,EOCM_HC_Superset,FCM,ECP_E
 SG_ SD63P_Filler : 41|18@0+ (1,0) [0|262143] "" ACP2_MCU,EOCM,EOCM_HC_Superset,FCM
 SG_ SD63P_ARC : 43|2@0+ (1,0) [0|3] "" ACP2_MCU,EOCM,EOCM_HC_Superset,FCM
 SG_ ElecPSTotTrqDlvdAuth_Inv : 44|1@0+ (1,0) [0|1] "" ACP2_MCU,ADIMa,ADIMb,EOCM,EOCM_HC_Superset,FCM,ECP_E

BO_ 677 SrlDat64_PCSM_PDU: 8 Vector__XXX
 SG_ SrlDat64_PCSM : 7|64@0+ (1,0) [0|1.84467e+019] "" ACP2_MCU,EOCM,EOCM_HC_Superset,FCM

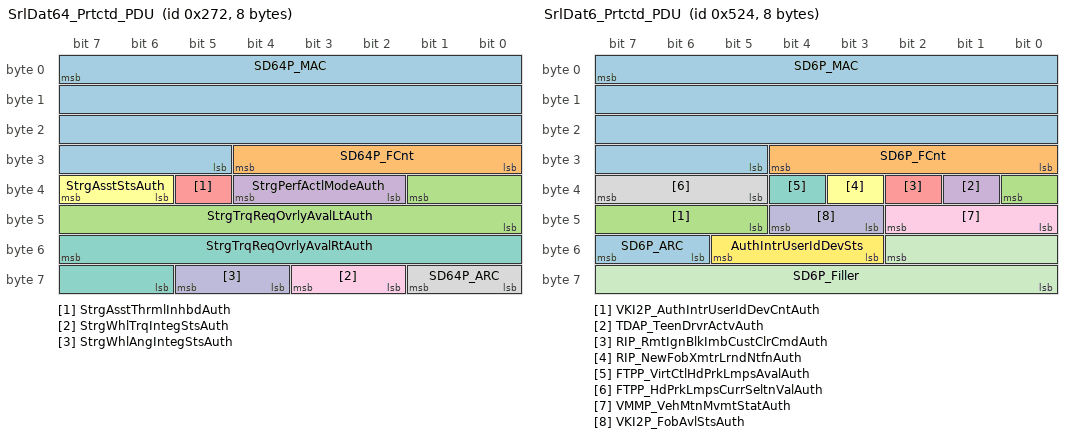
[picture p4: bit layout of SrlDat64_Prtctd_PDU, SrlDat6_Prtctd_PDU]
BO_ 626 SrlDat64_Prtctd_PDU: 8 Vector__XXX
 SG_ SD64P_MAC : 7|27@0+ (1,0) [0|1.34218e+008] "" ACP2_MCU,EOCM,EOCM_HC_Superset,FCM
 SG_ SD64P_FCnt : 28|5@0+ (1,0) [0|31] "" ACP2_MCU,EOCM,EOCM_HC_Superset,FCM
 SG_ StrgTrqReqOvrlyAvalLtAuth : 33|10@0+ (0.01,0) [0|10.23] "Nm" ACP2_MCU,EOCM,EOCM_HC_Superset,FCM
 SG_ StrgPerfActlModeAuth : 36|3@0+ (1,0) [0|7] "" ACP2_MCU,EOCM,EOCM_HC_Superset,FCM
 SG_ StrgAsstThrmlInhbdAuth : 37|1@0+ (1,0) [0|1] "" ACP2_MCU,EOCM,EOCM_HC_Superset,FCM
 SG_ StrgAsstStsAuth : 39|2@0+ (1,0) [0|2] "" ACP2_MCU,EOCM,EOCM_HC_Superset,FCM
 SG_ StrgTrqReqOvrlyAvalRtAuth : 55|10@0+ (0.01,-10.23) [-10.23|0] "Nm" ACP2_MCU,EOCM,EOCM_HC_Superset,FCM
 SG_ SD64P_ARC : 57|2@0+ (1,0) [0|3] "" ACP2_MCU,EOCM,EOCM_HC_Superset,FCM
 SG_ StrgWhlTrqIntegStsAuth : 59|2@0+ (1,0) [0|3] "" ACP2_MCU,EOCM,EOCM_HC_Superset,FCM
 SG_ StrgWhlAngIntegStsAuth : 61|2@0+ (1,0) [0|3] "" ACP2_MCU,EOCM,EOCM_HC_Superset,FCM

BO_ 1396 SrlDat6_PCSM_PDU: 8 Vector__XXX
 SG_ SrlDat6_PCSM : 7|64@0+ (1,0) [0|1.84467e+019] "" ACP2_MCU,EOCM,EOCM_HC_Superset,FCM

BO_ 1316 SrlDat6_Prtctd_PDU: 8 Vector__XXX
 SG_ SD6P_MAC : 7|27@0+ (1,0) [0|1.34218e+008] "" ACP2_MCU,EOCM,EOCM_HC_Superset,FCM
 SG_ SD6P_FCnt : 28|5@0+ (1,0) [0|31] "" ACP2_MCU,EOCM,EOCM_HC_Superset,FCM
 SG_ VKI2P_AuthIntrUserIdDevCntAuth : 32|4@0+ (1,0) [0|15] "Count" ACP2_MCU,EOCM,EOCM_HC_Superset,FCM
 SG_ TDAP_TeenDrvrActvAuth : 33|1@0+ (1,0) [0|1] "" ACP2_MCU,AHL_AFL,EBCM,ECM,EOCM,EOCM_HC_Superset,FCM,PCM
 SG_ RIP_RmtIgnBlkImbCustClrCmdAuth : 34|1@0+ (1,0) [0|1] "" ACP2_MCU,EOCM,EOCM_HC_Superset,FCM
 SG_ RIP_NewFobXmtrLrndNtfnAuth : 35|1@0+ (1,0) [0|1] "" ACP2_MCU,EOCM,EOCM_HC_Superset,FCM
 SG_ FTPP_VirtCtlHdPrkLmpsAvalAuth : 36|1@0+ (1,0) [0|1] "" ACP2_MCU,EOCM,EOCM_HC_Superset,FCM
 SG_ FTPP_HdPrkLmpsCurrSeltnValAuth : 39|3@0+ (1,0) [0|4] "" ACP2_MCU,EOCM,EOCM_HC_Superset,FCM
 SG_ VMMP_VehMtnMvmtStatAuth : 42|3@0+ (1,0) [0|4] "" ACP2_MCU,AHL_AFL,EOCM,EOCM_HC_Superset,FCM,FOPM,NVM
 SG_ VKI2P_FobAvlStsAuth : 44|2@0+ (1,0) [0|3] "" ACP2_MCU,EOCM,EOCM_HC_Superset,FCM
 SG_ SD6P_Filler : 50|11@0+ (1,0) [0|2047] "" ACP2_MCU,EOCM,EOCM_HC_Superset,FCM
 SG_ AuthIntrUserIdDevSts : 53|3@0+ (1,0) [0|5] "" ACP2_MCU,EOCM,EOCM_HC_Superset,FCM
 SG_ SD6P_ARC : 55|2@0+ (1,0) [0|3] "" ACP2_MCU,EOCM,EOCM_HC_Superset,FCM

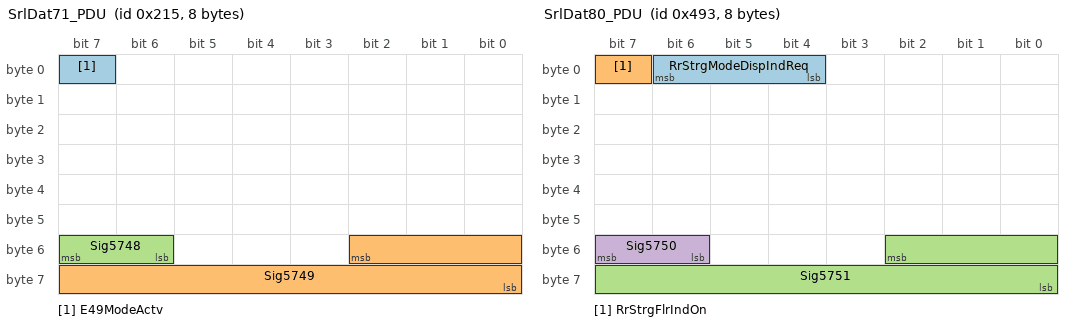
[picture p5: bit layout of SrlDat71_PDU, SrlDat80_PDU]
BO_ 533 SrlDat71_PDU: 8 Vector__XXX
 SG_ E49ModeActv : 7|1@0+ (1,0) [0|1] "" ACP2_MCU,EBCM,EOCM,EOCM_HC_Superset,FCM,TCM
 SG_ Sig5749 : 50|11@0+ (1,0) [0|2047] "" TCM
 SG_ Sig5748 : 55|2@0+ (1,0) [0|3] "" TCM

BO_ 1171 SrlDat80_PDU: 8 Vector__XXX
 SG_ RrStrgModeDispIndReq : 6|3@0+ (1,0) [0|5] "" ACP2_MCU,EOCM,EOCM_HC_Superset,FCM
 SG_ RrStrgFlrIndOn : 7|1@0+ (1,0) [0|1] "" ACP2_MCU,EOCM,EOCM_HC_Superset,FCM
 SG_ Sig5751 : 50|11@0+ (1,0) [0|2047] "" Vector__XXX
 SG_ Sig5750 : 55|2@0+ (1,0) [0|3] "" Vector__XXX

BO_ 1335 SrlDat87_PCSM_PDU: 8 Vector__XXX
 SG_ SrlDat87_PCSM : 7|64@0+ (1,0) [0|1.84467e+019] "" VICM

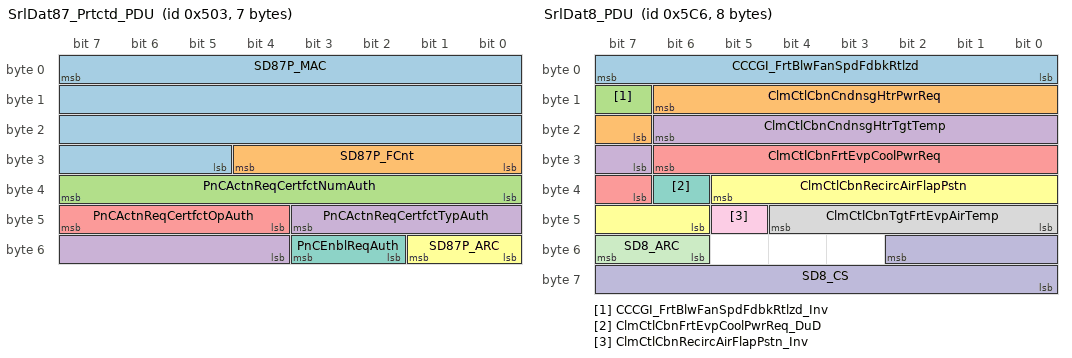
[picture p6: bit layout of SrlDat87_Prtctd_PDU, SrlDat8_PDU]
BO_ 1283 SrlDat87_Prtctd_PDU: 7 Vector__XXX
 SG_ SD87P_MAC : 7|27@0+ (1,0) [0|1.34218e+008] "" VICM
 SG_ SD87P_FCnt : 28|5@0+ (1,0) [0|31] "" VICM
 SG_ PnCActnReqCertfctNumAuth : 39|8@0+ (1,0) [0|255] "" VICM
 SG_ PnCActnReqCertfctTypAuth : 43|8@0+ (1,0) [0|14] "" VICM
 SG_ PnCActnReqCertfctOpAuth : 47|4@0+ (1,0) [0|4] "" VICM
 SG_ SD87P_ARC : 49|2@0+ (1,0) [0|3] "" VICM
 SG_ PnCEnblReqAuth : 51|2@0+ (1,0) [0|3] "" VICM

BO_ 1478 SrlDat8_PDU: 8 Vector__XXX
 SG_ CCCGI_FrtBlwFanSpdFdbkRtlzd : 7|8@0+ (0.392157,0) [0|100] "%" BSM,ECM,PCM
 SG_ ClmCtlCbnCndnsgHtrPwrReq : 14|8@0+ (0.1,-6) [-6|19.5] "kw" BSM,ECM,PCM
 SG_ CCCGI_FrtBlwFanSpdFdbkRtlzd_Inv : 15|1@0+ (1,0) [0|1] "" BSM,ECM,PCM
 SG_ ClmCtlCbnCndnsgHtrTgtTemp : 22|8@0+ (0.5,0) [0|127.5] "deg C" BSM,ECM,PCM
 SG_ ClmCtlCbnFrtEvpCoolPwrReq : 30|8@0+ (0.1,-6) [-6|19.5] "kw" BSM,ECM,PCM
 SG_ ClmCtlCbnRecircAirFlapPstn : 37|8@0+ (0.392157,0) [0|100] "%" BSM,ECM,PCM
 SG_ ClmCtlCbnFrtEvpCoolPwrReq_DuD : 38|1@0+ (1,0) [0|1] "" BSM,ECM,PCM
 SG_ ClmCtlCbnTgtFrtEvpAirTemp : 44|5@0+ (0.5,0) [0|15.5] "deg C" BSM,ECM,PCM
 SG_ ClmCtlCbnRecircAirFlapPstn_Inv : 45|1@0+ (1,0) [0|1] "" BSM,ECM,PCM
 SG_ SD8_CS : 50|11@0+ (1,0) [0|2047] "" BSM,ECM,PCM
 SG_ SD8_ARC : 55|2@0+ (1,0) [0|3] "" BSM,ECM,PCM

BO_ 1340 SrlDat90_PCSM_PDU: 8 Vector__XXX
 SG_ SrlDat90_PCSM : 7|64@0+ (1,0) [0|1.84467e+019] "" VICM,ECM,PCM,ECP_E,ECP_S,ECP_S2,ECP_X1

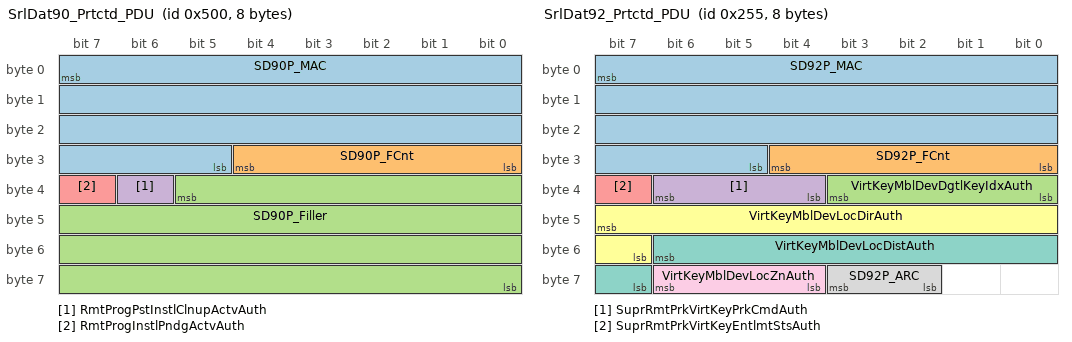
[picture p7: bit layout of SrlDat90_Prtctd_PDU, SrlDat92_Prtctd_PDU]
BO_ 1280 SrlDat90_Prtctd_PDU: 8 Vector__XXX
 SG_ SD90P_MAC : 7|27@0+ (1,0) [0|1.34218e+008] "" VICM,ECM,PCM,ECP_E,ECP_S,ECP_S2,ECP_X1
 SG_ SD90P_FCnt : 28|5@0+ (1,0) [0|31] "" VICM,ECM,PCM,ECP_E,ECP_S,ECP_S2,ECP_X1
 SG_ SD90P_Filler : 37|30@0+ (1,0) [0|1.07374e+009] "" VICM,ECM,PCM,ECP_E,ECP_S,ECP_S2,ECP_X1
 SG_ RmtProgPstInstlClnupActvAuth : 38|1@0+ (1,0) [0|1] "" VICM,ECM,PCM,ECP_E,ECP_S,ECP_S2,ECP_X1
 SG_ RmtProgInstlPndgActvAuth : 39|1@0+ (1,0) [0|1] "" VICM,ECM,PCM,ECP_E,ECP_S,ECP_S2,ECP_X1

BO_ 640 SrlDat92_PCSM_PDU: 8 Vector__XXX
 SG_ SrlDat92_PCSM : 7|64@0+ (1,0) [0|1.84467e+019] "" ACP2_MCU,EOCM,EOCM_HC_Superset

BO_ 597 SrlDat92_Prtctd_PDU: 8 Vector__XXX
 SG_ SD92P_MAC : 7|27@0+ (1,0) [0|1.34218e+008] "" ACP2_MCU,EOCM,EOCM_HC_Superset
 SG_ SD92P_FCnt : 28|5@0+ (1,0) [0|31] "" ACP2_MCU,EOCM,EOCM_HC_Superset
 SG_ VirtKeyMblDevDgtlKeyIdxAuth : 35|4@0+ (1,0) [0|15] "" ACP2_MCU,EOCM,EOCM_HC_Superset
 SG_ SuprRmtPrkVirtKeyPrkCmdAuth : 38|3@0+ (1,0) [0|5] "" ACP2_MCU,EOCM,EOCM_HC_Superset
 SG_ SuprRmtPrkVirtKeyEntlmtStsAuth : 39|1@0+ (1,0) [0|1] "" ACP2_MCU,EOCM,EOCM_HC_Superset
 SG_ VirtKeyMblDevLocDirAuth : 47|9@0+ (1,0) [0|511] "Deg" ACP2_MCU,EOCM,EOCM_HC_Superset
 SG_ VirtKeyMblDevLocDistAuth : 54|8@0+ (0.2,0) [0|51] "m" ACP2_MCU,EOCM,EOCM_HC_Superset
 SG_ SD92P_ARC : 59|2@0+ (1,0) [0|3] "" ACP2_MCU,EOCM,EOCM_HC_Superset
 SG_ VirtKeyMblDevLocZnAuth : 62|3@0+ (1,0) [0|4] "" ACP2_MCU,EOCM,EOCM_HC_Superset

BO_ 1331 Message1135_PDU: 8 Vector__XXX
 SG_ Sig6873 : 7|64@0+ (1,0) [0|1.84467e+019] "" ECP_S2

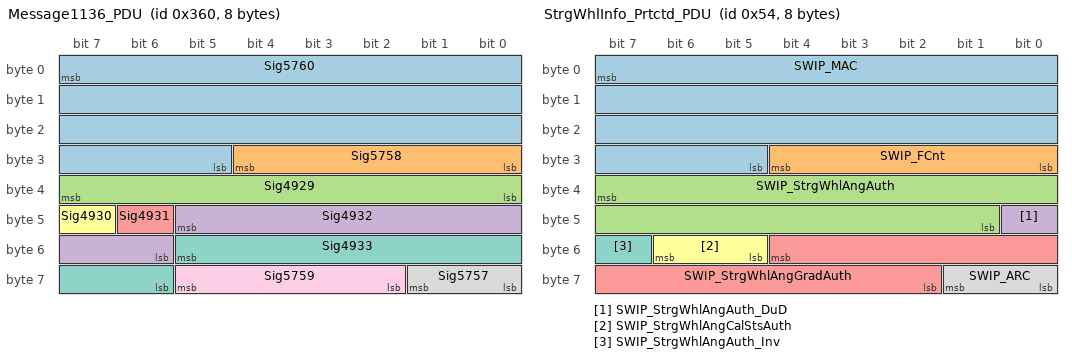
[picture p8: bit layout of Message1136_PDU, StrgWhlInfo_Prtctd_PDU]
BO_ 864 Message1136_PDU: 8 Vector__XXX
 SG_ Sig5760 : 7|27@0+ (1,0) [0|1.34218e+008] "" ECP_S2
 SG_ Sig5758 : 28|5@0+ (1,0) [0|31] "" ECP_S2
 SG_ Sig4929 : 39|8@0+ (1,-40) [-40|215] "Deg C" ECP_S2
 SG_ Sig4932 : 45|8@0+ (0.05,0) [0|12.75] "L/min" ECP_S2
 SG_ Sig4931 : 46|1@0+ (1,0) [0|1] "" ECP_S2
 SG_ Sig4930 : 47|1@0+ (1,0) [0|1] "" ECP_S2
 SG_ Sig4933 : 53|8@0+ (0.05,0) [0|12.75] "L/min" ECP_S2
 SG_ Sig5757 : 57|2@0+ (1,0) [0|3] "" ECP_S2
 SG_ Sig5759 : 61|4@0+ (1,0) [0|15] "" ECP_S2

BO_ 675 StrgWhlInfo_PCSM_PDU: 8 Vector__XXX
 SG_ StrgWhlInfo_PCSM : 7|64@0+ (1,0) [0|1.84467e+019] "" ACP2_MCU,ADIMa,ADIMb,AHL_AFL,AHS,ARS,EBCM,ECM,EOCM,EOCM_HC_Superset,FCM,E44,PCM,RDCM,TCCM,TCM,ECP_E

BO_ 84 StrgWhlInfo_Prtctd_PDU: 8 Vector__XXX
 SG_ SWIP_MAC : 7|27@0+ (1,0) [0|1.34218e+008] "" ACP2_MCU,ADIMa,ADIMb,AHL_AFL,AHS,ARS,CGM,EBCM,ECM,EOCM,EOCM_HC_Superset,FCM,E44,PCM,RDCM,TCCM,TCM,ECP_E
 SG_ SWIP_FCnt : 28|5@0+ (1,0) [0|31] "" ACP2_MCU,ADIMa,ADIMb,AHL_AFL,AHS,ARS,CGM,EBCM,ECM,EOCM,EOCM_HC_Superset,FCM,E44,PCM,RDCM,TCCM,TCM,ECP_E
 SG_ SWIP_StrgWhlAngAuth : 39|15@0- (0.0625,0) [-1024|1023.94] "deg" ACP2_MCU,ADIMa,ADIMb,AHL_AFL,AHS,ARS,CGM,DCM,DMS,EBCM,ECM,EOCM,EOCM_HC_Superset,FCM,E44,PCM,RDCM,TCCM,TCM,VDM,ECP_E
 SG_ SWIP_StrgWhlAngAuth_DuD : 40|1@0+ (1,0) [0|1] "" ACP2_MCU,ADIMa,ADIMb,AHL_AFL,AHS,ARS,CGM,DMS,EBCM,ECM,EOCM,EOCM_HC_Superset,FCM,E44,PCM,RDCM,TCCM,TCM,ECP_E
 SG_ SWIP_StrgWhlAngGradAuth : 52|11@0- (2,0) [-2048|2046] "deg/s" ACP2_MCU,ADIMa,ADIMb,AHL_AFL,AHS,ARS,CGM,DMS,EBCM,ECM,EOCM,EOCM_HC_Superset,FCM,E44,PCM,RDCM,TCCM,TCM,VDM,ECP_E
 SG_ SWIP_StrgWhlAngCalStsAuth : 54|2@0+ (1,0) [0|2] "" ACP2_MCU,ADIMa,ADIMb,AHL_AFL,AHS,ARS,CGM,DMS,EBCM,ECM,EOCM,EOCM_HC_Superset,FCM,E44,PCM,RDCM,TCCM,TCM,ECP_E
 SG_ SWIP_StrgWhlAngAuth_Inv : 55|1@0+ (1,0) [0|1] "" ACP2_MCU,ADIMa,ADIMb,AHL_AFL,AHS,ARS,CGM,DCM,DMS,EBCM,ECM,EOCM,EOCM_HC_Superset,FCM,E44,PCM,RDCM,TCCM,TCM,VDM,ECP_E
 SG_ SWIP_ARC : 57|2@0+ (1,0) [0|3] "" ACP2_MCU,ADIMa,ADIMb,AHL_AFL,AHS,ARS,CGM,EBCM,ECM,EOCM,EOCM_HC_Superset,FCM,E44,PCM,RDCM,TCCM,TCM,ECP_E

BO_ 1403 SysPwrMode_PCSM_PDU: 8 Vector__XXX
 SG_ SysPwrMode_PCSM : 7|64@0+ (1,0) [0|1.84467e+019] "" ACP2_MCU,AHL_AFL,AHS,ARS,BSM,BSM_MH,DCM,DMS,ECM,ECP_MC,EOCM,EOCM_HC_Superset,EPSRAa,EPS,EPSb,FCM,FOPM,LIB1,E44,PCM,RDCM,TCCM,TCM,ECP_X1

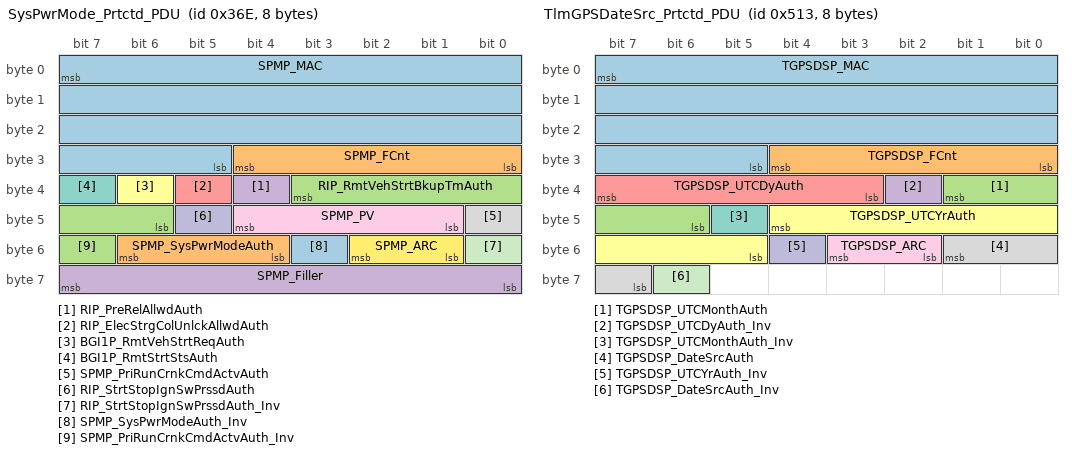
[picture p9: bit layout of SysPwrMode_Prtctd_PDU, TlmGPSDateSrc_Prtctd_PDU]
BO_ 878 SysPwrMode_Prtctd_PDU: 8 Vector__XXX
 SG_ SPMP_MAC : 7|27@0+ (1,0) [0|1.34218e+008] "" ACP2_MCU,AHL_AFL,AHS,ARS,BSM,BSM_MH,DCM,DMS,ECM,ECP_MC,EOCM,EOCM_HC_Superset,EPSRAa,EPS,EPSb,FCM,FOPM,LIB1,E44,PCM,RDCM,TCCM,TCM,ECP_X1
 SG_ SPMP_FCnt : 28|5@0+ (1,0) [0|31] "" ACP2_MCU,AHL_AFL,AHS,ARS,BSM,BSM_MH,DCM,DMS,ECM,ECP_MC,EOCM,EOCM_HC_Superset,EPSRAa,EPS,EPSb,FCM,FOPM,LIB1,E44,PCM,RDCM,TCCM,TCM,ECP_X1
 SG_ RIP_RmtVehStrtBkupTmAuth : 35|6@0+ (1,0) [0|63] "min" ACP2_MCU,AHL_AFL,AHS,ARS,BSM,BSM_MH,DCM,DMS,ECM,ECP_MC,EOCM,EOCM_HC_Superset,EPSRAa,EPS,EPSb,FCM,FOPM,LIB1,E44,PCM,RDCM,TCCM,TCM,ECP_X1
 SG_ RIP_PreRelAllwdAuth : 36|1@0+ (1,0) [0|1] "" ACP2_MCU,AHL_AFL,AHS,ARS,BSM,BSM_MH,DCM,DMS,ECM,ECP_MC,EOCM,EOCM_HC_Superset,EPSRAa,EPS,EPSb,FCM,FOPM,LIB1,E44,PCM,RDCM,TCCM,TCM,ECP_X1
 SG_ RIP_ElecStrgColUnlckAllwdAuth : 37|1@0+ (1,0) [0|1] "" ACP2_MCU,AHL_AFL,AHS,ARS,BSM,BSM_MH,DCM,DMS,ECM,ECP_MC,EOCM,EOCM_HC_Superset,EPSRAa,EPS,EPSb,FCM,FOPM,LIB1,E44,PCM,RDCM,TCCM,TCM,ECP_X1
 SG_ BGI1P_RmtVehStrtReqAuth : 38|1@0+ (1,0) [0|1] "" ACP2_MCU,AHL_AFL,AHS,ARS,BSM,BSM_MH,DCM,DMS,ECM,ECP_MC,EOCM,EOCM_HC_Superset,EPSRAa,EPS,EPSb,FCM,FOPM,LIB1,E44,PCM,RDCM,TCCM,TCM,ECP_X1
 SG_ BGI1P_RmtStrtStsAuth : 39|1@0+ (1,0) [0|1] "" ACP2_MCU,AHL_AFL,AHS,ARS,BSM,BSM_MH,DCM,DMS,ECM,ECP_MC,EOCM,EOCM_HC_Superset,EPSRAa,EPS,EPSb,FCM,FOPM,LIB1,E44,PCM,RDCM,TCCM,TCM,ECP_X1
 SG_ SPMP_PriRunCrnkCmdActvAuth : 40|1@0+ (1,0) [0|1] "" ACP2_MCU,AHL_AFL,AHS,ARS,BSM,BSM_MH,DCM,DMS,EBCM,ECM,ECP_MC,EOCM,EOCM_HC_Superset,EPSRAa,EPS,EPSb,FCM,FOPM,LIB1,E44,PCM,RDCM,TCCM,TCM,ECP_X1
 SG_ SPMP_PV : 44|4@0+ (1,0) [0|15] "" ACP2_MCU,AHL_AFL,AHS,ARS,BSM,BSM_MH,DCM,DMS,ECM,ECP_MC,EOCM,EOCM_HC_Superset,EPSRAa,EPS,EPSb,FCM,FOPM,HUD_CAN,LIB1,NVM,E44,PCM,RDCM,TCCM,TCM,ECP_X1
 SG_ RIP_StrtStopIgnSwPrssdAuth : 45|1@0+ (1,0) [0|1] "" ACP2_MCU,AHL_AFL,AHS,ARS,BSM,BSM_MH,DCM,DMS,ECM,ECP_MC,EOCM,EOCM_HC_Superset,EPSRAa,EPS,EPSb,FCM,FOPM,LIB1,E44,PCM,RDCM,TCCM,TCM,ECP_X1
 SG_ RIP_StrtStopIgnSwPrssdAuth_Inv : 48|1@0+ (1,0) [0|1] "" ACP2_MCU,AHL_AFL,AHS,ARS,BSM,BSM_MH,DCM,DMS,ECM,ECP_MC,EOCM,EOCM_HC_Superset,EPSRAa,EPS,EPSb,FCM,FOPM,LIB1,E44,PCM,RDCM,TCCM,TCM,ECP_X1
 SG_ SPMP_ARC : 50|2@0+ (1,0) [0|3] "" ACP2_MCU,AHL_AFL,AHS,ARS,BSM,BSM_MH,DCM,DMS,EBCM,ECM,ECP_MC,EOCM,EOCM_HC_Superset,EPSRAa,EPS,EPSb,FCM,FOPM,HUD_CAN,LIB1,NVM,E44,PCM,RDCM,TCCM,TCM,ECP_X1
 SG_ SPMP_SysPwrModeAuth_Inv : 51|1@0+ (1,0) [0|1] "" ACP2_MCU,AHL_AFL,AHS,ARS,BSM,BSM_MH,DCM,DMS,EBCM,ECM,ECP_MC,EOCM,EOCM_HC_Superset,EPSRAa,EPS,EPSb,FCM,FOPM,HUD_CAN,LIB1,NVM,E44,PCM,RDCM,TCCM,TCM,ECP_X1
 SG_ SPMP_SysPwrModeAuth : 54|3@0+ (1,0) [0|4] "" ACP2_MCU,AHL_AFL,AHS,ARS,BSM,BSM_MH,DCM,DMS,EBCM,ECM,ECP_MC,EOCM,EOCM_HC_Superset,EPSRAa,EPS,EPSb,FCM,FOPM,HUD_CAN,LIB1,NVM,E44,PCM,RDCM,TCCM,TCM,ECP_X1
 SG_ SPMP_PriRunCrnkCmdActvAuth_Inv : 55|1@0+ (1,0) [0|1] "" ACP2_MCU,AHL_AFL,AHS,ARS,BSM,BSM_MH,DCM,DMS,EBCM,ECM,ECP_MC,EOCM,EOCM_HC_Superset,EPSRAa,EPS,EPSb,FCM,FOPM,LIB1,E44,PCM,RDCM,TCCM,TCM,ECP_X1
 SG_ SPMP_Filler : 63|8@0+ (1,0) [0|255] "" ACP2_MCU,AHL_AFL,AHS,ARS,BSM,BSM_MH,DCM,DMS,ECM,ECP_MC,EOCM,EOCM_HC_Superset,EPSRAa,EPS,EPSb,FCM,FOPM,LIB1,E44,PCM,RDCM,TCCM,TCM,ECP_X1

BO_ 2147745824 Message1165_PDU: 1 Vector__XXX
 SG_ Sig7516 : 7|1@0+ (1,0) [0|1] "" CGM

BO_ 2147745825 Message1166_PDU: 1 Vector__XXX
 SG_ Sig7517 : 7|1@0+ (1,0) [0|1] "" CGM

BO_ 1358 TlmGPSDateSrc_PCSM_PDU: 8 Vector__XXX
 SG_ TlmGPSDateSrc_PCSM : 7|64@0+ (1,0) [0|1.84467e+019] "" VICM

BO_ 1299 TlmGPSDateSrc_Prtctd_PDU: 8 Vector__XXX
 SG_ TGPSDSP_MAC : 7|27@0+ (1,0) [0|1.34218e+008] "" VICM
 SG_ TGPSDSP_FCnt : 28|5@0+ (1,0) [0|31] "" VICM
 SG_ TGPSDSP_UTCMonthAuth : 33|4@0+ (1,0) [0|12] "" AHL_AFL,VICM,ECP_E
 SG_ TGPSDSP_UTCDyAuth_Inv : 34|1@0+ (1,0) [0|1] "" AHL_AFL,VICM
 SG_ TGPSDSP_UTCDyAuth : 39|5@0+ (1,0) [0|31] "day" AHL_AFL,VICM,ECP_E
 SG_ TGPSDSP_UTCYrAuth : 44|8@0+ (1,2000) [2000|2255] "year" AHL_AFL,VICM,ECP_E
 SG_ TGPSDSP_UTCMonthAuth_Inv : 45|1@0+ (1,0) [0|1] "" AHL_AFL,VICM
 SG_ TGPSDSP_DateSrcAuth : 49|3@0+ (1,0) [0|3] "" VICM
 SG_ TGPSDSP_ARC : 51|2@0+ (1,0) [0|3] "" VICM
 SG_ TGPSDSP_UTCYrAuth_Inv : 52|1@0+ (1,0) [0|1] "" AHL_AFL,VICM
 SG_ TGPSDSP_DateSrcAuth_Inv : 62|1@0+ (1,0) [0|1] "" VICM

BO_ 1357 TlmGPSTmSrc_PCSM_PDU: 8 Vector__XXX
 SG_ TlmGPSTmSrc_PCSM : 7|64@0+ (1,0) [0|1.84467e+019] "" VICM

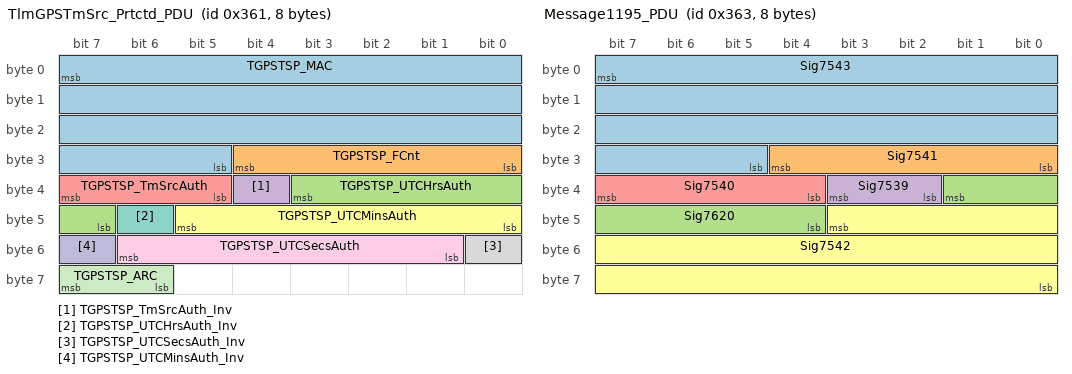
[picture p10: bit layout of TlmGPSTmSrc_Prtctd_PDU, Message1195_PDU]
BO_ 865 TlmGPSTmSrc_Prtctd_PDU: 8 Vector__XXX
 SG_ TGPSTSP_MAC : 7|27@0+ (1,0) [0|1.34218e+008] "" VICM
 SG_ TGPSTSP_FCnt : 28|5@0+ (1,0) [0|31] "" VICM
 SG_ TGPSTSP_UTCHrsAuth : 35|5@0+ (1,0) [0|31] "hour" VICM,ECP_E
 SG_ TGPSTSP_TmSrcAuth_Inv : 36|1@0+ (1,0) [0|1] "" VICM
 SG_ TGPSTSP_TmSrcAuth : 39|3@0+ (1,0) [0|3] "" VICM
 SG_ TGPSTSP_UTCMinsAuth : 45|6@0+ (1,0) [0|63] "minutes" VICM,ECP_E
 SG_ TGPSTSP_UTCHrsAuth_Inv : 46|1@0+ (1,0) [0|1] "" VICM
 SG_ TGPSTSP_UTCSecsAuth_Inv : 48|1@0+ (1,0) [0|1] "" VICM
 SG_ TGPSTSP_UTCSecsAuth : 54|6@0+ (1,0) [0|63] "seconds" VICM,ECP_E
 SG_ TGPSTSP_UTCMinsAuth_Inv : 55|1@0+ (1,0) [0|1] "" VICM
 SG_ TGPSTSP_ARC : 63|2@0+ (1,0) [0|3] "" VICM

BO_ 1903 Message1180_PDU: 1500 Vector__XXX
 SG_ Sig7904 : 7|12000@0+ (1,0) [0|0] "" Vector__XXX

BO_ 1162 Message1181_PDU: 8 Vector__XXX

BO_ 1904 Message1182_PDU: 1500 Vector__XXX
 SG_ Sig7905 : 7|12000@0+ (1,0) [0|0] "" Vector__XXX

BO_ 1161 Message1183_PDU: 8 Vector__XXX

BO_ 1901 Message1184_PDU: 1500 Vector__XXX
 SG_ Sig7906 : 7|12000@0+ (1,0) [0|0] "" Vector__XXX

BO_ 1164 Message1185_PDU: 8 Vector__XXX

BO_ 1902 Message1186_PDU: 1500 Vector__XXX
 SG_ Sig7907 : 7|12000@0+ (1,0) [0|0] "" Vector__XXX

BO_ 1163 Message1187_PDU: 8 Vector__XXX

BO_ 1905 Message1188_PDU: 1500 Vector__XXX
 SG_ Sig7908 : 7|12000@0+ (1,0) [0|0] "" Vector__XXX

BO_ 1160 Message1189_PDU: 8 Vector__XXX

BO_ 1371 Message1194_PDU: 8 Vector__XXX
 SG_ Sig7631 : 7|64@0+ (1,0) [0|1.84467e+019] "" ECM

BO_ 867 Message1195_PDU: 8 Vector__XXX
 SG_ Sig7543 : 7|27@0+ (1,0) [0|1.34218e+008] "" ECM
 SG_ Sig7541 : 28|5@0+ (1,0) [0|31] "" ECM
 SG_ Sig7620 : 33|6@0+ (1.5873,0) [0|100] "%" ECM
 SG_ Sig7539 : 35|2@0+ (1,0) [0|3] "" ECM
 SG_ Sig7540 : 39|4@0+ (1,0) [0|15] "counts" ECM
 SG_ Sig7542 : 43|20@0+ (1,0) [0|1.04858e+006] "" ECM

BO_ 674 TrnsEstGr_PCSM_PDU: 8 Vector__XXX
 SG_ TrnsEstGr_PCSM : 7|64@0+ (1,0) [0|1.84467e+019] "" ACP2_MCU,ADIMa,ADIMb,AHS,BSM,VICM,CGM,EBCM,ECM,EOCM,EOCM_HC_Superset,EPS,EPSb,FCM,E44,PCM,RDCM,TCCM,ECP_X1

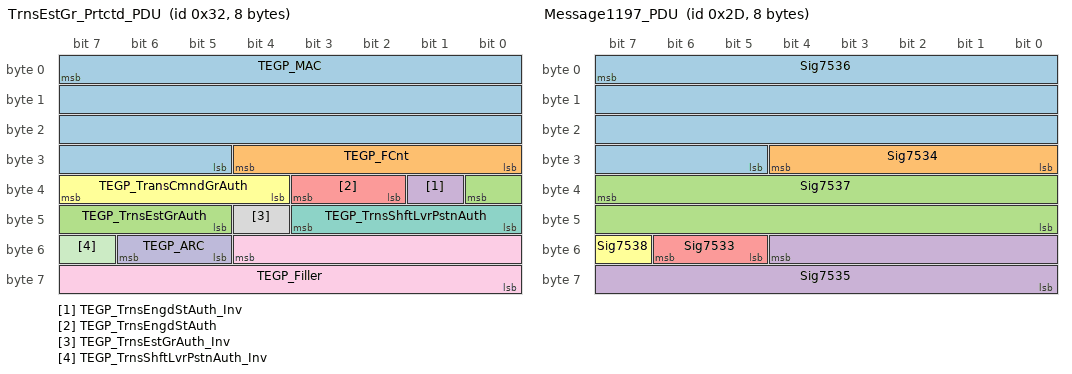
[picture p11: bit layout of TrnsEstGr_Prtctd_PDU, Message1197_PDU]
BO_ 50 TrnsEstGr_Prtctd_PDU: 8 Vector__XXX
 SG_ TEGP_MAC : 7|27@0+ (1,0) [0|1.34218e+008] "" ACP2_MCU,ADIMa,ADIMb,AHS,BSM,VICM,CGM,EBCM,ECM,EOCM,EOCM_HC_Superset,EPS,EPSb,FCM,E44,PCM,RDCM,TCCM,ECP_X1
 SG_ TEGP_FCnt : 28|5@0+ (1,0) [0|31] "" ACP2_MCU,ADIMa,ADIMb,AHS,BSM,VICM,CGM,EBCM,ECM,EOCM,EOCM_HC_Superset,EPS,EPSb,FCM,E44,PCM,RDCM,TCCM,ECP_X1
 SG_ TEGP_TrnsEstGrAuth : 32|4@0+ (1,0) [0|15] "" ACP2_MCU,ADIMa,ADIMb,AHS,BSM,VICM,CGM,DCM,EBCM,ECM,EOCM,EOCM_HC_Superset,EPS,EPSb,FCM,E44,PCM,RDCM,TCCM,ECP_X1
 SG_ TEGP_TrnsEngdStAuth_Inv : 33|1@0+ (1,0) [0|1] "" ACP2_MCU,ADIMa,ADIMb,AHS,BSM,VICM,CGM,EBCM,ECM,EOCM,EOCM_HC_Superset,EPS,EPSb,FCM,E44,PCM,RDCM,TCCM,ECP_X1
 SG_ TEGP_TrnsEngdStAuth : 35|2@0+ (1,0) [0|3] "" ACP2_MCU,ADIMa,ADIMb,AHS,BSM,VICM,CGM,EBCM,ECM,EOCM,EOCM_HC_Superset,EPS,EPSb,FCM,E44,PCM,RDCM,TCCM,ECP_X1
 SG_ TEGP_TransCmndGrAuth : 39|4@0+ (1,0) [0|15] "" ACP2_MCU,ADIMa,ADIMb,AHS,BSM,VICM,CGM,EBCM,ECM,EOCM,EOCM_HC_Superset,EPS,EPSb,FCM,E44,PCM,RDCM,TCCM,ECP_X1
 SG_ TEGP_TrnsShftLvrPstnAuth : 43|4@0+ (1,0) [0|14] "" ACP2_MCU,ADIMa,ADIMb,AHS,ARS,BSM,VICM,CGM,DMS,EBCM,ECM,EOCM,EOCM_HC_Superset,EPS,EPSb,FCM,E44,PCM,RDCM,TCCM,VDM,ECP_S,ECP_S2,ECP_X1
 SG_ TEGP_TrnsEstGrAuth_Inv : 44|1@0+ (1,0) [0|1] "" ACP2_MCU,ADIMa,ADIMb,AHS,BSM,VICM,CGM,DCM,EBCM,ECM,EOCM,EOCM_HC_Superset,EPS,EPSb,FCM,E44,PCM,RDCM,TCCM,ECP_X1
 SG_ TEGP_Filler : 52|13@0+ (1,0) [0|8191] "" ACP2_MCU,ADIMa,ADIMb,AHS,BSM,VICM,CGM,EBCM,ECM,EOCM,EOCM_HC_Superset,EPS,EPSb,FCM,E44,PCM,RDCM,TCCM,ECP_X1
 SG_ TEGP_ARC : 54|2@0+ (1,0) [0|3] "" ACP2_MCU,ADIMa,ADIMb,AHS,BSM,VICM,CGM,EBCM,ECM,EOCM,EOCM_HC_Superset,EPS,EPSb,FCM,E44,PCM,RDCM,TCCM,ECP_X1
 SG_ TEGP_TrnsShftLvrPstnAuth_Inv : 55|1@0+ (1,0) [0|1] "" ACP2_MCU,ADIMa,ADIMb,AHS,ARS,BSM,VICM,CGM,DMS,EBCM,ECM,EOCM,EOCM_HC_Superset,EPS,EPSb,FCM,E44,PCM,RDCM,TCCM,VDM,ECP_S,ECP_S2,ECP_X1

BO_ 892 Message1196_PDU: 8 Vector__XXX
 SG_ Sig7780 : 7|64@0+ (1,0) [0|1.84467e+019] "" ECM,RDCM,TCCM

BO_ 45 Message1197_PDU: 8 Vector__XXX
 SG_ Sig7536 : 7|27@0+ (1,0) [0|1.34218e+008] "" CGM,ECM,RDCM,TCCM
 SG_ Sig7534 : 28|5@0+ (1,0) [0|31] "" CGM,ECM,RDCM,TCCM
 SG_ Sig7537 : 39|16@0+ (0.25,0) [0|16383.8] "rpm" CGM,ECM,RDCM,TCCM
 SG_ Sig7535 : 52|13@0+ (1,0) [0|8191] "" CGM,ECM,RDCM,TCCM
 SG_ Sig7533 : 54|2@0+ (1,0) [0|3] "" CGM,ECM,RDCM,TCCM
 SG_ Sig7538 : 55|1@0+ (1,0) [0|1] "" CGM,ECM,RDCM,TCCM

BO_ 891 TwinClchInfo_PCSM_PDU: 8 Vector__XXX
 SG_ TwinClchInfo_PCSM : 7|64@0+ (1,0) [0|1.84467e+019] "" EBCM

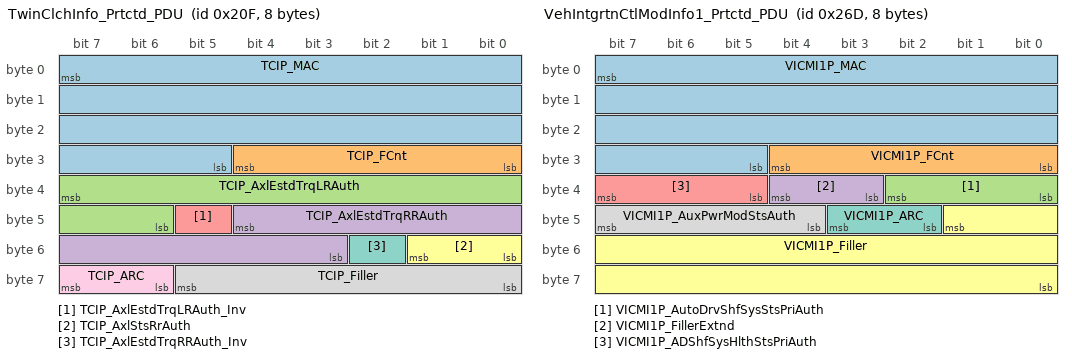
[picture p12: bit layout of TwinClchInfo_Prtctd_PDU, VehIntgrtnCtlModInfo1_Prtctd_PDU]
BO_ 527 TwinClchInfo_Prtctd_PDU: 8 Vector__XXX
 SG_ TCIP_MAC : 7|27@0+ (1,0) [0|1.34218e+008] "" EBCM
 SG_ TCIP_FCnt : 28|5@0+ (1,0) [0|31] "" EBCM
 SG_ TCIP_AxlEstdTrqLRAuth : 39|10@0+ (10,0) [0|10230] "Nm" EBCM
 SG_ TCIP_AxlEstdTrqRRAuth : 44|10@0+ (10,0) [0|10230] "Nm" EBCM
 SG_ TCIP_AxlEstdTrqLRAuth_Inv : 45|1@0+ (1,0) [0|1] "" EBCM
 SG_ TCIP_AxlStsRrAuth : 49|2@0+ (1,0) [0|3] "" EBCM
 SG_ TCIP_AxlEstdTrqRRAuth_Inv : 50|1@0+ (1,0) [0|1] "" EBCM
 SG_ TCIP_Filler : 61|6@0+ (1,0) [0|63] "" EBCM
 SG_ TCIP_ARC : 63|2@0+ (1,0) [0|3] "" EBCM

BO_ 1545 Message1205_PDU: 64 Vector__XXX

BO_ 1544 Message1211_PDU: 64 Vector__XXX

BO_ 1650 Message1221_PDU: 64 Vector__XXX

BO_ 1585 Message1227_PDU: 64 Vector__XXX

BO_ 1723 Message1253_PDU: 64 Vector__XXX

BO_ 1586 Message1264_PDU: 64 Vector__XXX

BO_ 1739 Message1274_PDU: 64 Vector__XXX

BO_ 1563 Message1292_PDU: 64 Vector__XXX

BO_ 1642 Message1303_PDU: 64 Vector__XXX

BO_ 1576 USDT_Req_BootMode_To_EBCM_CAN_2_: 64 Vector__XXX

BO_ 1553 Message1313_PDU: 64 Vector__XXX

BO_ 1559 USDT_Req_BootMode_To_ECP_E_CAN_2: 64 Vector__XXX

BO_ 1565 Message1323_PDU: 64 Vector__XXX

BO_ 1566 Message1329_PDU: 64 Vector__XXX

BO_ 1589 Message1392_PDU: 64 Vector__XXX

BO_ 1725 Message1398_PDU: 64 Vector__XXX

BO_ 1765 Message1410_PDU: 64 Vector__XXX

BO_ 1634 Message1420_PDU: 64 Vector__XXX

BO_ 1766 Message1450_PDU: 64 Vector__XXX

BO_ 1637 Message1516_PDU: 64 Vector__XXX

BO_ 1552 Message1527_PDU: 64 Vector__XXX

BO_ 1562 Message1547_PDU: 64 Vector__XXX

BO_ 1560 Message1666_PDU: 64 Vector__XXX

BO_ 1612 Message1697_PDU: 64 Vector__XXX

BO_ 1741 Message1703_PDU: 64 Vector__XXX

BO_ 2497342705 Message1736_Tp: 64 Vector__XXX

BO_ 2497317361 Message1749_PDU: 64 Vector__XXX

BO_ 2497317105 Message1765_PDU: 64 Vector__XXX

BO_ 2497344241 Message1780_PDU: 64 Vector__XXX

BO_ 2565829361 Message1783_PDU: 64 Vector__XXX

BO_ 2497327601 Message1786_PDU: 64 Vector__XXX

BO_ 2497362929 Message1811_PDU: 64 Vector__XXX

BO_ 2497327857 Message1818_PDU: 64 Vector__XXX

BO_ 2565812977 Message1822_PDU: 64 Vector__XXX

BO_ 2430336753 USDT_Req_From_E58_To_AllNodes_Al: 62 Vector__XXX

BO_ 2497367025 Message1839_PDU: 64 Vector__XXX

BO_ 2431385329 USDT_Req_From_E58_To_CAN_2_Clust: 62 Vector__XXX

BO_ 2497321969 Message1889_PDU: 64 Vector__XXX

BO_ 2497342193 Message1896_PDU: 64 Vector__XXX

BO_ 2497325297 USDT_Req_From_E58_To_EBCM_CAN_2_: 64 Vector__XXX

BO_ 2565810417 USDT_Req_From_E58_To_EBCM_XCP_CA: 64 Vector__XXX

BO_ 2497319409 Message1905_PDU: 64 Vector__XXX

BO_ 2497320945 USDT_Req_From_E58_To_ECP_E_CAN_2: 64 Vector__XXX

BO_ 2497322481 Message1917_PDU: 64 Vector__XXX

BO_ 2497322737 Message1921_PDU: 64 Vector__XXX

BO_ 2497340657 Message1965_Tp: 64 Vector__XXX

BO_ 2565812721 Message1985_PDU: 64 Vector__XXX

BO_ 2497328625 Message2005_PDU: 64 Vector__XXX

BO_ 2565813745 Message2009_PDU: 64 Vector__XXX

BO_ 2497363441 Message2013_PDU: 64 Vector__XXX

BO_ 2497373681 Message2021_PDU: 64 Vector__XXX

BO_ 2497340145 Message2033_PDU: 64 Vector__XXX

BO_ 2497373937 Message2057_PDU: 64 Vector__XXX

BO_ 2497340913 Message2098_PDU: 64 Vector__XXX

BO_ 2497319153 Message2105_PDU: 64 Vector__XXX

BO_ 2497321713 Message2123_PDU: 64 Vector__XXX

BO_ 2497321201 Message2216_PDU: 64 Vector__XXX

BO_ 2497334513 Message2238_PDU: 64 Vector__XXX

BO_ 2497367537 Message2246_PDU: 64 Vector__XXX

BO_ 2497317362 Message2278_PDU: 64 Vector__XXX

BO_ 2497317106 Message2294_PDU: 64 Vector__XXX

BO_ 2497344242 Message2309_PDU: 64 Vector__XXX

BO_ 2497327602 Message2313_PDU: 64 Vector__XXX

BO_ 2497362930 Message2333_PDU: 64 Vector__XXX

BO_ 2497327858 Message2340_PDU: 64 Vector__XXX

BO_ 2430336754 USDT_Req_From_E59_To_AllNodes_Al: 62 Vector__XXX

BO_ 2497367026 Message2357_PDU: 64 Vector__XXX

BO_ 2431385330 USDT_Req_From_E59_To_CAN_2_Clust: 62 Vector__XXX

BO_ 2497321970 Message2401_PDU: 64 Vector__XXX

BO_ 2497342194 Message2408_PDU: 64 Vector__XXX

BO_ 2497325298 USDT_Req_From_E59_To_EBCM_CAN_2_: 64 Vector__XXX

BO_ 2497319410 Message2416_PDU: 64 Vector__XXX

BO_ 2497320946 USDT_Req_From_E59_To_ECP_E_CAN_2: 64 Vector__XXX

BO_ 2497322482 Message2428_PDU: 64 Vector__XXX

BO_ 2497322738 Message2432_PDU: 64 Vector__XXX

BO_ 2497342706 Message2460_Tp: 64 Vector__XXX

BO_ 2497340658 Message2476_Tp: 64 Vector__XXX

BO_ 2497328626 Message2501_PDU: 64 Vector__XXX

BO_ 2497363442 Message2505_PDU: 64 Vector__XXX

BO_ 2497373682 Message2513_PDU: 64 Vector__XXX

BO_ 2497340146 Message2521_PDU: 64 Vector__XXX

BO_ 2497373938 Message2541_PDU: 64 Vector__XXX

BO_ 2497340914 Message2582_PDU: 64 Vector__XXX

BO_ 2497319154 Message2589_PDU: 64 Vector__XXX

BO_ 2497321714 Message2606_PDU: 64 Vector__XXX

BO_ 2497321202 Message2687_PDU: 64 Vector__XXX

BO_ 2497334514 Message2707_PDU: 64 Vector__XXX

BO_ 2497367538 Message2715_PDU: 64 Vector__XXX

BO_ 2497342707 Message2742_Tp: 8 Vector__XXX

BO_ 2497317363 Message2745_PDU: 8 Vector__XXX

BO_ 2497317107 Message2749_PDU: 8 Vector__XXX

BO_ 2497344243 Message2752_PDU: 8 Vector__XXX

BO_ 2497327603 Message2753_PDU: 8 Vector__XXX

BO_ 2497362931 Message2758_PDU: 8 Vector__XXX

BO_ 2497327859 Message2760_PDU: 8 Vector__XXX

BO_ 2430336755 USDT_Req_From_TEST_TOOL_3_To_All: 7 Vector__XXX

BO_ 2497367027 Message2766_PDU: 8 Vector__XXX

BO_ 2431385331 USDT_Req_From_TEST_TOOL_3_To_CAN: 7 Vector__XXX

BO_ 2497321971 Message2773_PDU: 8 Vector__XXX

BO_ 2497342195 Message2775_PDU: 8 Vector__XXX

BO_ 2497325299 USDT_Req_From_TEST_TOOL_3_To_EBC: 8 Vector__XXX

BO_ 2497319411 Message2776_PDU: 8 Vector__XXX

BO_ 2497320947 USDT_Req_From_TEST_TOOL_3_To_ECP: 8 Vector__XXX

BO_ 2497322483 Message2778_PDU: 8 Vector__XXX

BO_ 2497322739 Message2779_PDU: 8 Vector__XXX

BO_ 2497340659 Message2790_Tp: 8 Vector__XXX

BO_ 2497328627 Message2796_PDU: 8 Vector__XXX

BO_ 2497363443 Message2797_PDU: 8 Vector__XXX

BO_ 2497373683 Message2799_PDU: 8 Vector__XXX

BO_ 2497340147 Message2802_PDU: 8 Vector__XXX

BO_ 2497373939 Message2804_PDU: 8 Vector__XXX

BO_ 2497340915 Message2816_PDU: 8 Vector__XXX

BO_ 2497319155 Message2818_PDU: 8 Vector__XXX

BO_ 2497321715 Message2822_PDU: 8 Vector__XXX

BO_ 2497321203 Message2843_PDU: 8 Vector__XXX

BO_ 2497334515 Message2847_PDU: 8 Vector__XXX

BO_ 2497367539 Message2849_PDU: 8 Vector__XXX

BO_ 2497342708 Message2853_Tp: 64 Vector__XXX

BO_ 2497317364 Message2856_PDU: 64 Vector__XXX

BO_ 2497317108 Message2860_PDU: 64 Vector__XXX

BO_ 2497344244 Message2864_PDU: 64 Vector__XXX

BO_ 2497327604 Message2865_PDU: 64 Vector__XXX

BO_ 2497362932 Message2871_PDU: 64 Vector__XXX

BO_ 2497327860 Message2873_PDU: 64 Vector__XXX

BO_ 2430336756 USDT_Req_From_TEST_TOOL_4_To_All: 62 Vector__XXX

BO_ 2497367028 Message2880_PDU: 64 Vector__XXX

BO_ 2431385332 USDT_Req_From_TEST_TOOL_4_To_CAN: 62 Vector__XXX

BO_ 2497321972 Message2891_PDU: 64 Vector__XXX

BO_ 2497342196 Message2893_PDU: 64 Vector__XXX

BO_ 2497325300 USDT_Req_From_TEST_TOOL_4_To_EBC: 64 Vector__XXX

BO_ 2497319412 Message2894_PDU: 64 Vector__XXX

BO_ 2497320948 USDT_Req_From_TEST_TOOL_4_To_ECP: 64 Vector__XXX

BO_ 2497322484 Message2897_PDU: 64 Vector__XXX

BO_ 2497322740 Message2898_PDU: 64 Vector__XXX

BO_ 2497340660 Message2910_Tp: 64 Vector__XXX

BO_ 2497328628 Message2916_PDU: 64 Vector__XXX

BO_ 2497363444 Message2917_PDU: 64 Vector__XXX

BO_ 2497373684 Message2919_PDU: 64 Vector__XXX

BO_ 2497340148 Message2922_PDU: 64 Vector__XXX

BO_ 2497373940 Message2928_PDU: 64 Vector__XXX

BO_ 2497340916 Message2941_PDU: 64 Vector__XXX

BO_ 2497319156 Message2943_PDU: 64 Vector__XXX

BO_ 2497321716 Message2948_PDU: 64 Vector__XXX

BO_ 2497321204 Message2971_PDU: 64 Vector__XXX

BO_ 2497334516 Message2977_PDU: 64 Vector__XXX

BO_ 2497367540 Message2979_PDU: 64 Vector__XXX

BO_ 2497342709 Message2986_Tp: 64 Vector__XXX

BO_ 2497317365 Message2989_PDU: 64 Vector__XXX

BO_ 2497317109 Message2993_PDU: 64 Vector__XXX

BO_ 2497344245 Message2997_PDU: 64 Vector__XXX

BO_ 2497327605 Message2998_PDU: 64 Vector__XXX

BO_ 2497362933 Message3004_PDU: 64 Vector__XXX

BO_ 2497327861 Message3006_PDU: 64 Vector__XXX

BO_ 2430336757 USDT_Req_From_TEST_TOOL_5_To_All: 62 Vector__XXX

BO_ 2497367029 Message3013_PDU: 64 Vector__XXX

BO_ 2431385333 USDT_Req_From_TEST_TOOL_5_To_CAN: 62 Vector__XXX

BO_ 2497321973 Message3024_PDU: 64 Vector__XXX

BO_ 2497342197 Message3026_PDU: 64 Vector__XXX

BO_ 2497325301 USDT_Req_From_TEST_TOOL_5_To_EBC: 64 Vector__XXX

BO_ 2497319413 Message3027_PDU: 64 Vector__XXX

BO_ 2497320949 USDT_Req_From_TEST_TOOL_5_To_ECP: 64 Vector__XXX

BO_ 2497322485 Message3030_PDU: 64 Vector__XXX

BO_ 2497322741 Message3031_PDU: 64 Vector__XXX

BO_ 2497340661 Message3043_Tp: 64 Vector__XXX

BO_ 2497328629 Message3049_PDU: 64 Vector__XXX

BO_ 2497363445 Message3050_PDU: 64 Vector__XXX

BO_ 2497373685 Message3052_PDU: 64 Vector__XXX

BO_ 2497340149 Message3055_PDU: 64 Vector__XXX

BO_ 2497373941 Message3061_PDU: 64 Vector__XXX

BO_ 2497340917 Message3074_PDU: 64 Vector__XXX

BO_ 2497319157 Message3076_PDU: 64 Vector__XXX

BO_ 2497321717 Message3081_PDU: 64 Vector__XXX

BO_ 2497321205 Message3104_PDU: 64 Vector__XXX

BO_ 2497334517 Message3110_PDU: 64 Vector__XXX

BO_ 2497367541 Message3112_PDU: 64 Vector__XXX

BO_ 2497342710 Message3119_Tp: 8 Vector__XXX

BO_ 2497317366 Message3125_PDU: 8 Vector__XXX

BO_ 2497317110 Message3133_PDU: 8 Vector__XXX

BO_ 2497344246 Message3140_PDU: 8 Vector__XXX

BO_ 2497327606 Message3142_PDU: 8 Vector__XXX

BO_ 2497362934 Message3153_PDU: 8 Vector__XXX

BO_ 2497327862 Message3157_PDU: 8 Vector__XXX

BO_ 2430336758 USDT_Req_From_TEST_TOOL_6_To_All: 7 Vector__XXX

BO_ 2497367030 Message3166_PDU: 8 Vector__XXX

BO_ 2431385334 USDT_Req_From_TEST_TOOL_6_To_CAN: 7 Vector__XXX

BO_ 2497321974 Message3185_PDU: 8 Vector__XXX

BO_ 2497342198 Message3189_PDU: 8 Vector__XXX

BO_ 2497325302 USDT_Req_From_TEST_TOOL_6_To_EBC: 8 Vector__XXX

BO_ 2497319414 Message3193_PDU: 8 Vector__XXX

BO_ 2497320950 USDT_Req_From_TEST_TOOL_6_To_ECP: 8 Vector__XXX

BO_ 2497322486 Message3199_PDU: 8 Vector__XXX

BO_ 2497322742 Message3201_PDU: 8 Vector__XXX

BO_ 2497340662 Message3223_Tp: 8 Vector__XXX

BO_ 2497328630 Message3236_PDU: 8 Vector__XXX

BO_ 2497363446 Message3238_PDU: 8 Vector__XXX

BO_ 2497373686 Message3242_PDU: 8 Vector__XXX

BO_ 2497340150 Message3248_PDU: 8 Vector__XXX

BO_ 2497373942 Message3257_PDU: 8 Vector__XXX

BO_ 2497340918 Message3282_PDU: 8 Vector__XXX

BO_ 2497319158 Message3286_PDU: 8 Vector__XXX

BO_ 2497321718 Message3295_PDU: 8 Vector__XXX

BO_ 2497321206 Message3338_PDU: 8 Vector__XXX

BO_ 2497334518 Message3347_PDU: 8 Vector__XXX

BO_ 2497367542 Message3351_PDU: 8 Vector__XXX

BO_ 2497325303 USDT_Req_From_TEST_TOOL_7_To_EBC: 64 Vector__XXX

BO_ 2497320951 USDT_Req_From_TEST_TOOL_7_To_ECP: 64 Vector__XXX

BO_ 2497322487 Message3365_PDU: 64 Vector__XXX

BO_ 2497367031 USDT_Req_From_TEST_TOOL_7_To_VIC: 64 Vector__XXX

BO_ 2497379337 Message3374_Tp: 64 Vector__XXX

BO_ 2497379336 Message3381_Tp: 64 Vector__XXX

BO_ 2497379442 Message3393_Tp: 64 Vector__XXX

BO_ 2497379377 Message3400_Tp: 64 Vector__XXX

BO_ 2497379515 Message3431_Tp: 64 Vector__XXX

BO_ 2497379378 Message3444_Tp: 64 Vector__XXX

BO_ 2497379531 Message3456_Tp: 64 Vector__XXX

BO_ 2497379355 Message3478_Tp: 64 Vector__XXX

BO_ 2497379434 USDT_Rsp_BootMode_From_DMS_CAN_2: 64 Vector__XXX

BO_ 2497379368 USDT_Rsp_BootMode_From_EBCM_CAN_: 64 Vector__XXX

BO_ 2497379345 Message3501_Tp: 64 Vector__XXX

BO_ 2497379351 USDT_Rsp_BootMode_From_ECP_E_CAN: 64 Vector__XXX

BO_ 2497379357 Message3513_Tp: 64 Vector__XXX

BO_ 2497379358 Message3520_Tp: 64 Vector__XXX

BO_ 2497379381 Message3594_Tp: 64 Vector__XXX

BO_ 2497379517 Message3601_Tp: 64 Vector__XXX

BO_ 2497379557 Message3615_Tp: 64 Vector__XXX

BO_ 2497379426 Message3627_Tp: 64 Vector__XXX

BO_ 2497379558 Message3664_Tp: 64 Vector__XXX

BO_ 2497379429 Message3743_Tp: 64 Vector__XXX

BO_ 2497379344 Message3756_Tp: 64 Vector__XXX

BO_ 2497379354 Message3780_Tp: 64 Vector__XXX

BO_ 2497379352 Message3919_Tp: 64 Vector__XXX

BO_ 2497379404 Message3954_Tp: 64 Vector__XXX

BO_ 2497379533 Message3961_Tp: 64 Vector__XXX

BO_ 2497376620 Message4001_PDU: 64 Vector__XXX

BO_ 2497377132 Message4004_PDU: 8 Vector__XXX

BO_ 2497377388 Message4006_PDU: 64 Vector__XXX

BO_ 2497377644 Message4007_PDU: 64 Vector__XXX

BO_ 2497377900 Message4008_PDU: 8 Vector__XXX

BO_ 2497376521 Message4036_PDU: 64 Vector__XXX

BO_ 2497376777 Message4040_PDU: 64 Vector__XXX

BO_ 2497377033 Message4043_PDU: 8 Vector__XXX

BO_ 2497377289 Message4045_PDU: 64 Vector__XXX

BO_ 2497377545 Message4046_PDU: 64 Vector__XXX

BO_ 2497377801 Message4047_PDU: 8 Vector__XXX

BO_ 2497376520 Message4092_PDU: 64 Vector__XXX

BO_ 2497376776 Message4096_PDU: 64 Vector__XXX

BO_ 2497377032 Message4099_PDU: 8 Vector__XXX

BO_ 2497377288 Message4101_PDU: 64 Vector__XXX

BO_ 2497377544 Message4102_PDU: 64 Vector__XXX

BO_ 2497377800 Message4103_PDU: 8 Vector__XXX

BO_ 2497376626 Message4144_PDU: 64 Vector__XXX

BO_ 2497376882 Message4148_PDU: 64 Vector__XXX

BO_ 2497377138 Message4151_PDU: 8 Vector__XXX

BO_ 2497377394 Message4153_PDU: 64 Vector__XXX

BO_ 2497377650 Message4154_PDU: 64 Vector__XXX

BO_ 2497377906 Message4155_PDU: 8 Vector__XXX

BO_ 2565861746 Message4157_PDU: 64 Vector__XXX

BO_ 2497376561 Message4160_PDU: 64 Vector__XXX

BO_ 2497376817 Message4164_PDU: 64 Vector__XXX

BO_ 2497377073 Message4167_PDU: 8 Vector__XXX

BO_ 2497377329 Message4169_PDU: 64 Vector__XXX

BO_ 2497377585 Message4170_PDU: 64 Vector__XXX

BO_ 2497377841 Message4171_PDU: 8 Vector__XXX

BO_ 2497376699 Message4239_PDU: 64 Vector__XXX

BO_ 2497376955 Message4243_PDU: 64 Vector__XXX

BO_ 2497377211 Message4246_PDU: 8 Vector__XXX

BO_ 2497377467 Message4248_PDU: 64 Vector__XXX

BO_ 2497377723 Message4249_PDU: 64 Vector__XXX

BO_ 2497377979 Message4250_PDU: 8 Vector__XXX

BO_ 2497376562 Message4265_PDU: 64 Vector__XXX

BO_ 2497376818 Message4269_PDU: 64 Vector__XXX

BO_ 2497377074 Message4272_PDU: 8 Vector__XXX

BO_ 2497377330 Message4274_PDU: 64 Vector__XXX

BO_ 2497377586 Message4275_PDU: 64 Vector__XXX

BO_ 2497377842 Message4276_PDU: 8 Vector__XXX

BO_ 2565861682 Message4279_PDU: 64 Vector__XXX

BO_ 2497376715 Message4289_PDU: 64 Vector__XXX

BO_ 2497376971 Message4293_PDU: 64 Vector__XXX

BO_ 2497377227 Message4296_PDU: 8 Vector__XXX

BO_ 2497377483 Message4298_PDU: 64 Vector__XXX

BO_ 2497377739 Message4299_PDU: 64 Vector__XXX

BO_ 2497377995 Message4300_PDU: 8 Vector__XXX

BO_ 2497376539 Message4357_PDU: 64 Vector__XXX

BO_ 2497376795 Message4361_PDU: 64 Vector__XXX

BO_ 2497377051 Message4364_PDU: 8 Vector__XXX

BO_ 2497377307 Message4366_PDU: 64 Vector__XXX

BO_ 2497377563 Message4367_PDU: 64 Vector__XXX

BO_ 2497377819 Message4368_PDU: 8 Vector__XXX

BO_ 2497376618 USDT_Rsp_From_DMS_CAN_2_connecto: 64 Vector__XXX

BO_ 2497376874 USDT_Rsp_From_DMS_CAN_2_connec01: 64 Vector__XXX

BO_ 2497377130 USDT_Rsp_From_DMS_CAN_2_connec02: 8 Vector__XXX

BO_ 2497377386 USDT_Rsp_From_DMS_CAN_2_connec03: 64 Vector__XXX

BO_ 2497377642 USDT_Rsp_From_DMS_CAN_2_connec04: 64 Vector__XXX

BO_ 2497377898 USDT_Rsp_From_DMS_CAN_2_connec05: 8 Vector__XXX

BO_ 2497376552 USDT_Rsp_From_EBCM_CAN_2_connect: 64 Vector__XXX

BO_ 2497376808 USDT_Rsp_From_EBCM_CAN_2_conne01: 64 Vector__XXX

BO_ 2497377064 USDT_Rsp_From_EBCM_CAN_2_conne02: 8 Vector__XXX

BO_ 2497377320 USDT_Rsp_From_EBCM_CAN_2_conne03: 64 Vector__XXX

BO_ 2497377576 USDT_Rsp_From_EBCM_CAN_2_conne04: 64 Vector__XXX

BO_ 2497377832 USDT_Rsp_From_EBCM_CAN_2_conne05: 8 Vector__XXX

BO_ 2497378088 USDT_Rsp_From_EBCM_CAN_2_conne06: 64 Vector__XXX

BO_ 2565861672 USDT_Rsp_From_EBCM_XCP_CAN_2_con: 64 Vector__XXX

BO_ 2497376529 Message4402_PDU: 64 Vector__XXX

BO_ 2497376785 Message4406_PDU: 64 Vector__XXX

BO_ 2497377041 Message4409_PDU: 8 Vector__XXX

BO_ 2497377297 Message4411_PDU: 64 Vector__XXX

BO_ 2497377553 Message4412_PDU: 64 Vector__XXX

BO_ 2497377809 Message4413_PDU: 8 Vector__XXX

BO_ 2497376535 USDT_Rsp_From_ECP_E_CAN_2_connec: 64 Vector__XXX

BO_ 2497376791 USDT_Rsp_From_ECP_E_CAN_2_conn01: 64 Vector__XXX

BO_ 2497377047 USDT_Rsp_From_ECP_E_CAN_2_conn02: 8 Vector__XXX

BO_ 2497377303 USDT_Rsp_From_ECP_E_CAN_2_conn03: 64 Vector__XXX

BO_ 2497377559 USDT_Rsp_From_ECP_E_CAN_2_conn04: 64 Vector__XXX

BO_ 2497377815 USDT_Rsp_From_ECP_E_CAN_2_conn05: 8 Vector__XXX

BO_ 2497378071 USDT_Rsp_From_ECP_E_CAN_2_conn06: 64 Vector__XXX

BO_ 2497376541 Message4444_PDU: 64 Vector__XXX

BO_ 2497376797 Message4448_PDU: 64 Vector__XXX

BO_ 2497377053 Message4451_PDU: 8 Vector__XXX

BO_ 2497377309 Message4453_PDU: 64 Vector__XXX

BO_ 2497377565 Message4454_PDU: 64 Vector__XXX

BO_ 2497377821 Message4455_PDU: 8 Vector__XXX

BO_ 2497376542 Message4458_PDU: 64 Vector__XXX

BO_ 2497376798 Message4462_PDU: 64 Vector__XXX

BO_ 2497377054 Message4465_PDU: 8 Vector__XXX

BO_ 2497377310 Message4467_PDU: 64 Vector__XXX

BO_ 2497377566 Message4468_PDU: 64 Vector__XXX

BO_ 2497377822 Message4469_PDU: 8 Vector__XXX

BO_ 2497378077 Message4500_PDU: 64 Vector__XXX

BO_ 2497376876 Message4564_PDU: 64 Vector__XXX

BO_ 2497376612 Message4616_PDU: 64 Vector__XXX

BO_ 2497376868 Message4620_PDU: 64 Vector__XXX

BO_ 2497377124 Message4623_PDU: 8 Vector__XXX

BO_ 2497377380 Message4625_PDU: 64 Vector__XXX

BO_ 2497377636 Message4626_PDU: 64 Vector__XXX

BO_ 2497377892 Message4627_PDU: 8 Vector__XXX

BO_ 2565861681 Message4676_PDU: 64 Vector__XXX

BO_ 2497376565 Message4719_PDU: 64 Vector__XXX

BO_ 2497376821 Message4723_PDU: 64 Vector__XXX

BO_ 2497377077 Message4726_PDU: 8 Vector__XXX

BO_ 2497377333 Message4728_PDU: 64 Vector__XXX

BO_ 2497377589 Message4729_PDU: 64 Vector__XXX

BO_ 2497377845 Message4730_PDU: 8 Vector__XXX

BO_ 2565861685 Message4733_PDU: 64 Vector__XXX

BO_ 2497376701 Message4737_PDU: 64 Vector__XXX

BO_ 2497376957 Message4741_PDU: 64 Vector__XXX

BO_ 2497377213 Message4744_PDU: 8 Vector__XXX

BO_ 2497377469 Message4746_PDU: 64 Vector__XXX

BO_ 2497377725 Message4747_PDU: 64 Vector__XXX

BO_ 2497377981 Message4748_PDU: 8 Vector__XXX

BO_ 2497376741 Message4765_PDU: 64 Vector__XXX

BO_ 2497376997 Message4769_PDU: 64 Vector__XXX

BO_ 2497377253 Message4772_PDU: 8 Vector__XXX

BO_ 2497377509 Message4774_PDU: 64 Vector__XXX

BO_ 2497377765 Message4775_PDU: 64 Vector__XXX

BO_ 2497378021 Message4776_PDU: 8 Vector__XXX

BO_ 2497376610 Message4803_PDU: 64 Vector__XXX

BO_ 2497376866 Message4807_PDU: 64 Vector__XXX

BO_ 2497377122 Message4810_PDU: 8 Vector__XXX

BO_ 2497377378 Message4812_PDU: 64 Vector__XXX

BO_ 2497377634 Message4813_PDU: 64 Vector__XXX

BO_ 2497377890 Message4814_PDU: 8 Vector__XXX

BO_ 2497376742 Message4877_PDU: 64 Vector__XXX

BO_ 2497376998 Message4881_PDU: 64 Vector__XXX

BO_ 2497377254 Message4884_PDU: 8 Vector__XXX

BO_ 2497377510 Message4886_PDU: 64 Vector__XXX

BO_ 2497377766 Message4887_PDU: 64 Vector__XXX

BO_ 2497378022 Message4888_PDU: 8 Vector__XXX

BO_ 2497376613 Message5035_PDU: 64 Vector__XXX

BO_ 2497376869 Message5039_PDU: 64 Vector__XXX

BO_ 2497377125 Message5042_PDU: 8 Vector__XXX

BO_ 2497377381 Message5044_PDU: 64 Vector__XXX

BO_ 2497377637 Message5045_PDU: 64 Vector__XXX

BO_ 2497377893 Message5046_PDU: 8 Vector__XXX

BO_ 2497376528 Message5061_PDU: 64 Vector__XXX

BO_ 2497376784 Message5065_PDU: 64 Vector__XXX

BO_ 2497377040 Message5068_PDU: 8 Vector__XXX

BO_ 2497377296 Message5070_PDU: 64 Vector__XXX

BO_ 2497377552 Message5071_PDU: 64 Vector__XXX

BO_ 2497377808 Message5072_PDU: 8 Vector__XXX

BO_ 2497376538 Message5124_PDU: 64 Vector__XXX

BO_ 2497376794 Message5128_PDU: 64 Vector__XXX

BO_ 2497377050 Message5131_PDU: 8 Vector__XXX

BO_ 2497377306 Message5133_PDU: 64 Vector__XXX

BO_ 2497377562 Message5134_PDU: 64 Vector__XXX

BO_ 2497377818 Message5135_PDU: 8 Vector__XXX

BO_ 2497376536 Message5421_PDU: 64 Vector__XXX

BO_ 2497376792 Message5425_PDU: 64 Vector__XXX

BO_ 2497377048 Message5428_PDU: 8 Vector__XXX

BO_ 2497377304 Message5430_PDU: 64 Vector__XXX

BO_ 2497377560 Message5431_PDU: 64 Vector__XXX

BO_ 2497377816 Message5432_PDU: 8 Vector__XXX

BO_ 2497376588 Message5488_PDU: 64 Vector__XXX

BO_ 2497376844 Message5492_PDU: 64 Vector__XXX

BO_ 2497377100 Message5495_PDU: 8 Vector__XXX

BO_ 2497377356 Message5497_PDU: 64 Vector__XXX

BO_ 2497377612 Message5498_PDU: 64 Vector__XXX

BO_ 2497377868 Message5499_PDU: 8 Vector__XXX

BO_ 2497376717 Message5516_PDU: 64 Vector__XXX

BO_ 2497376973 Message5520_PDU: 64 Vector__XXX

BO_ 2497377229 Message5523_PDU: 8 Vector__XXX

BO_ 2497377485 Message5525_PDU: 64 Vector__XXX

BO_ 2497377741 Message5526_PDU: 64 Vector__XXX

BO_ 2497377997 Message5527_PDU: 8 Vector__XXX

BO_ 2497378251 USDT_Rsp_From_VICM_CAN_2_connect: 64 Vector__XXX

BO_ 2497507593 Message5620_PDU: 64 Vector__XXX

BO_ 2497507849 Message5624_PDU: 64 Vector__XXX

BO_ 2497508105 Message5627_PDU: 8 Vector__XXX

BO_ 2497508361 Message5629_PDU: 64 Vector__XXX

BO_ 2497508617 Message5630_PDU: 64 Vector__XXX

BO_ 2497508873 Message5631_PDU: 8 Vector__XXX

BO_ 2497507592 Message5634_PDU: 64 Vector__XXX

BO_ 2497507848 Message5638_PDU: 64 Vector__XXX

BO_ 2497508104 Message5641_PDU: 8 Vector__XXX

BO_ 2497508360 Message5643_PDU: 64 Vector__XXX

BO_ 2497508616 Message5644_PDU: 64 Vector__XXX

BO_ 2497508872 Message5645_PDU: 8 Vector__XXX

BO_ 2497507698 Message5658_PDU: 64 Vector__XXX

BO_ 2497507954 Message5662_PDU: 64 Vector__XXX

BO_ 2497508210 Message5665_PDU: 8 Vector__XXX

BO_ 2497508466 Message5667_PDU: 64 Vector__XXX

BO_ 2497508722 Message5668_PDU: 64 Vector__XXX

BO_ 2497508978 Message5669_PDU: 8 Vector__XXX

BO_ 2497507633 Message5672_PDU: 64 Vector__XXX

BO_ 2497507889 Message5676_PDU: 64 Vector__XXX

BO_ 2497508145 Message5679_PDU: 8 Vector__XXX

BO_ 2497508401 Message5681_PDU: 64 Vector__XXX

BO_ 2497508657 Message5682_PDU: 64 Vector__XXX

BO_ 2497508913 Message5683_PDU: 8 Vector__XXX

BO_ 2497507771 Message5734_PDU: 64 Vector__XXX

BO_ 2497508027 Message5738_PDU: 64 Vector__XXX

BO_ 2497508283 Message5741_PDU: 8 Vector__XXX

BO_ 2497508539 Message5743_PDU: 64 Vector__XXX

BO_ 2497508795 Message5744_PDU: 64 Vector__XXX

BO_ 2497509051 Message5745_PDU: 8 Vector__XXX

BO_ 2497507634 Message5760_PDU: 64 Vector__XXX

BO_ 2497507890 Message5764_PDU: 64 Vector__XXX

BO_ 2497508146 Message5767_PDU: 8 Vector__XXX

BO_ 2497508402 Message5769_PDU: 64 Vector__XXX

BO_ 2497508658 Message5770_PDU: 64 Vector__XXX

BO_ 2497508914 Message5771_PDU: 8 Vector__XXX

BO_ 2497507787 Message5780_PDU: 64 Vector__XXX

BO_ 2497508043 Message5784_PDU: 64 Vector__XXX

BO_ 2497508299 Message5787_PDU: 8 Vector__XXX

BO_ 2497508555 Message5789_PDU: 64 Vector__XXX

BO_ 2497508811 Message5790_PDU: 64 Vector__XXX

BO_ 2497509067 Message5791_PDU: 8 Vector__XXX

BO_ 2497507611 Message5829_PDU: 64 Vector__XXX

BO_ 2497507867 Message5833_PDU: 64 Vector__XXX

BO_ 2497508123 Message5836_PDU: 8 Vector__XXX

BO_ 2497508379 Message5838_PDU: 64 Vector__XXX

BO_ 2497508635 Message5839_PDU: 64 Vector__XXX

BO_ 2497508891 Message5840_PDU: 8 Vector__XXX

BO_ 2497507690 UUDT_Rsp_From_DMS_CAN_2_connecto: 64 Vector__XXX

BO_ 2497507946 UUDT_Rsp_From_DMS_CAN_2_connec01: 64 Vector__XXX

BO_ 2497508202 UUDT_Rsp_From_DMS_CAN_2_connec02: 8 Vector__XXX

BO_ 2497508458 UUDT_Rsp_From_DMS_CAN_2_connec03: 64 Vector__XXX

BO_ 2497508714 UUDT_Rsp_From_DMS_CAN_2_connec04: 64 Vector__XXX

BO_ 2497508970 UUDT_Rsp_From_DMS_CAN_2_connec05: 8 Vector__XXX

BO_ 2497507624 UUDT_Rsp_From_EBCM_CAN_2_connect: 64 Vector__XXX

BO_ 2497507880 UUDT_Rsp_From_EBCM_CAN_2_conne01: 64 Vector__XXX

BO_ 2497508136 UUDT_Rsp_From_EBCM_CAN_2_conne02: 8 Vector__XXX

BO_ 2497508392 UUDT_Rsp_From_EBCM_CAN_2_conne03: 64 Vector__XXX

BO_ 2497508648 UUDT_Rsp_From_EBCM_CAN_2_conne04: 64 Vector__XXX

BO_ 2497508904 UUDT_Rsp_From_EBCM_CAN_2_conne05: 8 Vector__XXX

BO_ 2497507601 Message5867_PDU: 64 Vector__XXX

BO_ 2497507857 Message5871_PDU: 64 Vector__XXX

BO_ 2497508113 Message5874_PDU: 8 Vector__XXX

BO_ 2497508369 Message5876_PDU: 64 Vector__XXX

BO_ 2497508625 Message5877_PDU: 64 Vector__XXX

BO_ 2497508881 Message5878_PDU: 8 Vector__XXX

BO_ 2497507607 UUDT_Rsp_From_ECP_E_CAN_2_connec: 64 Vector__XXX

BO_ 2497507863 UUDT_Rsp_From_ECP_E_CAN_2_conn01: 64 Vector__XXX

BO_ 2497508119 UUDT_Rsp_From_ECP_E_CAN_2_conn02: 8 Vector__XXX

BO_ 2497508375 UUDT_Rsp_From_ECP_E_CAN_2_conn03: 64 Vector__XXX

BO_ 2497508631 UUDT_Rsp_From_ECP_E_CAN_2_conn04: 64 Vector__XXX

BO_ 2497508887 UUDT_Rsp_From_ECP_E_CAN_2_conn05: 8 Vector__XXX

BO_ 2497507613 Message5887_PDU: 64 Vector__XXX

BO_ 2497507869 Message5891_PDU: 64 Vector__XXX

BO_ 2497508125 Message5894_PDU: 8 Vector__XXX

BO_ 2497508381 Message5896_PDU: 64 Vector__XXX

BO_ 2497508637 Message5897_PDU: 64 Vector__XXX

BO_ 2497508893 Message5898_PDU: 8 Vector__XXX

BO_ 2497507614 Message5901_PDU: 64 Vector__XXX

BO_ 2497507870 Message5905_PDU: 64 Vector__XXX

BO_ 2497508126 Message5908_PDU: 8 Vector__XXX

BO_ 2497508382 Message5910_PDU: 64 Vector__XXX

BO_ 2497508638 Message5911_PDU: 64 Vector__XXX

BO_ 2497508894 Message5912_PDU: 8 Vector__XXX

BO_ 2497507637 Message6045_PDU: 64 Vector__XXX

BO_ 2497507893 Message6049_PDU: 64 Vector__XXX

BO_ 2497508149 Message6052_PDU: 8 Vector__XXX

BO_ 2497508405 Message6054_PDU: 64 Vector__XXX

BO_ 2497508661 Message6055_PDU: 64 Vector__XXX

BO_ 2497508917 Message6056_PDU: 8 Vector__XXX

BO_ 2497507773 Message6059_PDU: 64 Vector__XXX

BO_ 2497508029 Message6063_PDU: 64 Vector__XXX

BO_ 2497508285 Message6066_PDU: 8 Vector__XXX

BO_ 2497508541 Message6068_PDU: 64 Vector__XXX

BO_ 2497508797 Message6069_PDU: 64 Vector__XXX

BO_ 2497509053 Message6070_PDU: 8 Vector__XXX

BO_ 2497507813 Message6087_PDU: 64 Vector__XXX

BO_ 2497508069 Message6091_PDU: 64 Vector__XXX

BO_ 2497508325 Message6094_PDU: 8 Vector__XXX

BO_ 2497508581 Message6096_PDU: 64 Vector__XXX

BO_ 2497508837 Message6097_PDU: 64 Vector__XXX

BO_ 2497509093 Message6098_PDU: 8 Vector__XXX

BO_ 2497507682 Message6109_PDU: 64 Vector__XXX

BO_ 2497507938 Message6113_PDU: 64 Vector__XXX

BO_ 2497508194 Message6116_PDU: 8 Vector__XXX

BO_ 2497508450 Message6118_PDU: 64 Vector__XXX

BO_ 2497508706 Message6119_PDU: 64 Vector__XXX

BO_ 2497508962 Message6120_PDU: 8 Vector__XXX

BO_ 2497507814 Message6182_PDU: 64 Vector__XXX

BO_ 2497508070 Message6186_PDU: 64 Vector__XXX

BO_ 2497508326 Message6189_PDU: 8 Vector__XXX

BO_ 2497508582 Message6191_PDU: 64 Vector__XXX

BO_ 2497508838 Message6192_PDU: 64 Vector__XXX

BO_ 2497509094 Message6193_PDU: 8 Vector__XXX

BO_ 2497507685 Message6340_PDU: 64 Vector__XXX

BO_ 2497507941 Message6344_PDU: 64 Vector__XXX

BO_ 2497508197 Message6347_PDU: 8 Vector__XXX

BO_ 2497508453 Message6349_PDU: 64 Vector__XXX

BO_ 2497508709 Message6350_PDU: 64 Vector__XXX

BO_ 2497508965 Message6351_PDU: 8 Vector__XXX

BO_ 2497507600 Message6366_PDU: 64 Vector__XXX

BO_ 2497507856 Message6370_PDU: 64 Vector__XXX

BO_ 2497508112 Message6373_PDU: 8 Vector__XXX

BO_ 2497508368 Message6375_PDU: 64 Vector__XXX

BO_ 2497508624 Message6376_PDU: 64 Vector__XXX

BO_ 2497508880 Message6377_PDU: 8 Vector__XXX

BO_ 2497507610 Message6414_PDU: 64 Vector__XXX

BO_ 2497507866 Message6418_PDU: 64 Vector__XXX

BO_ 2497508122 Message6421_PDU: 8 Vector__XXX

BO_ 2497508378 Message6423_PDU: 64 Vector__XXX

BO_ 2497508634 Message6424_PDU: 64 Vector__XXX

BO_ 2497508890 Message6425_PDU: 8 Vector__XXX

BO_ 2497507608 Message6687_PDU: 64 Vector__XXX

BO_ 2497507864 Message6691_PDU: 64 Vector__XXX

BO_ 2497508120 Message6694_PDU: 8 Vector__XXX

BO_ 2497508376 Message6696_PDU: 64 Vector__XXX

BO_ 2497508632 Message6697_PDU: 64 Vector__XXX

BO_ 2497508888 Message6698_PDU: 8 Vector__XXX

BO_ 2497507660 Message6752_PDU: 64 Vector__XXX

BO_ 2497507916 Message6756_PDU: 64 Vector__XXX

BO_ 2497508172 Message6759_PDU: 8 Vector__XXX

BO_ 2497508428 Message6761_PDU: 64 Vector__XXX

BO_ 2497508684 Message6762_PDU: 64 Vector__XXX

BO_ 2497508940 Message6763_PDU: 8 Vector__XXX

BO_ 2497507789 Message6766_PDU: 64 Vector__XXX

BO_ 2497508045 Message6770_PDU: 64 Vector__XXX

BO_ 2497508301 Message6773_PDU: 8 Vector__XXX

BO_ 2497508557 Message6775_PDU: 64 Vector__XXX

BO_ 2497508813 Message6776_PDU: 64 Vector__XXX

BO_ 2497509069 Message6777_PDU: 8 Vector__XXX

BO_ 2147745826 Message6843_PDU: 1 Vector__XXX
 SG_ Sig7850 : 7|1@0+ (1,0) [0|1] "" CGM

BO_ 2147745827 Message6845_PDU: 1 Vector__XXX
 SG_ Sig7852 : 7|1@0+ (1,0) [0|1] "" CGM

BO_ 2147745806 VICM_CAN2_ClscCANHrtBtActv_PDU: 1 Vector__XXX
 SG_ VICM_CAN2_ClscCANHrtBtActv : 7|1@0+ (1,0) [0|1] "" CGM

BO_ 1257 VehIdNmDig10_17_PDU: 8 Vector__XXX
 SG_ VehIdNmDig10_17 : 7|64@0+ (1,0) [0|18446744073709551615] "" AHL_AFL,ARS,ECM,EPS,EPSb,NVM,PCM,RDCM,TCCM,TCM

BO_ 1809 VehIdNmDig2_9_PDU: 8 Vector__XXX
 SG_ VehIdNmDig2_9 : 7|64@0+ (1,0) [0|18446744073709551615] "" AHL_AFL,ARS,ECM,EPS,EPSb,NVM,PCM,RDCM,TCCM,TCM

BO_ 890 VehIntgrtnCtlModInfo1_PCSM_PDU: 8 Vector__XXX
 SG_ VehIntgrtnCtlModInfo1_PCSM : 7|64@0+ (1,0) [0|1.84467e+019] "" ADIMa,ADIMb,FOPM

BO_ 621 VehIntgrtnCtlModInfo1_Prtctd_PDU: 8 Vector__XXX
 SG_ VICMI1P_MAC : 7|27@0+ (1,0) [0|1.34218e+008] "" ADIMa,ADIMb,FOPM
 SG_ VICMI1P_FCnt : 28|5@0+ (1,0) [0|31] "" ADIMa,ADIMb,FOPM
 SG_ VICMI1P_AutoDrvShfSysStsPriAuth : 34|3@0+ (1,0) [0|4] "" ADIMa,ADIMb,FOPM
 SG_ VICMI1P_FillerExtnd : 36|2@0+ (1,0) [0|3] "" ADIMa,ADIMb,FOPM
 SG_ VICMI1P_ADShfSysHlthStsPriAuth : 39|3@0+ (1,0) [0|4] "" ADIMa,ADIMb,FOPM
 SG_ VICMI1P_Filler : 41|18@0+ (1,0) [0|262143] "" ADIMa,ADIMb,FOPM
 SG_ VICMI1P_ARC : 43|2@0+ (1,0) [0|3] "" ADIMa,ADIMb,FOPM
 SG_ VICMI1P_AuxPwrModStsAuth : 47|4@0+ (1,0) [0|8] "" ADIMa,ADIMb,FOPM

BO_ 1370 VehOdoDispVal_PCSM_PDU: 8 Vector__XXX
 SG_ VehOdoDispVal_PCSM : 7|64@0+ (1,0) [0|1.84467e+019] "" ECM,PCM,ECP_X1

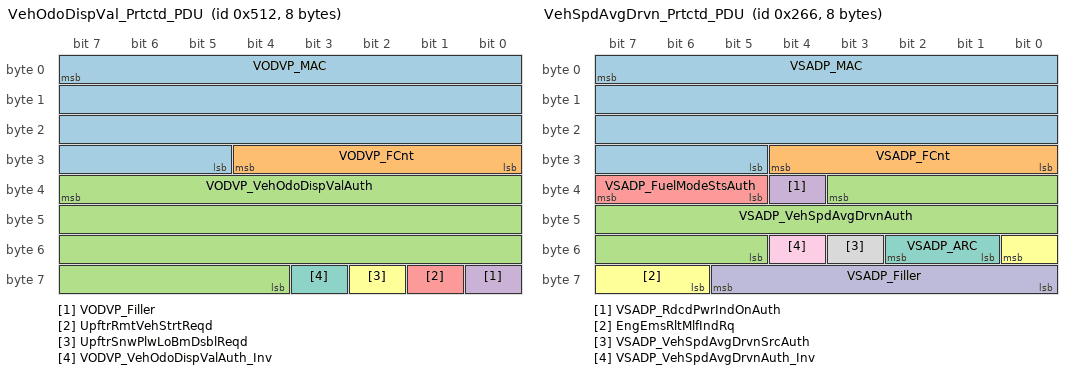
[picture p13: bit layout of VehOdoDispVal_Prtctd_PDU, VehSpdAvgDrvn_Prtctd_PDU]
BO_ 1298 VehOdoDispVal_Prtctd_PDU: 8 Vector__XXX
 SG_ VODVP_MAC : 7|27@0+ (1,0) [0|1.34218e+008] "" ECM,PCM,ECP_X1
 SG_ VODVP_FCnt : 28|5@0+ (1,0) [0|31] "" ECM,PCM,ECP_X1
 SG_ VODVP_VehOdoDispValAuth : 39|28@0+ (0.015625,0) [0|4.1943e+006] "km" ACP2_MCU,DCM,DMS,EBCM,ECM,ECP_MC,EOCM,EOCM_HC_Superset,EPSRAa,EPS,EPSb,FCM,FOPM,PCM,RDCM,TCCM,TCM,ECP_X1
 SG_ VODVP_Filler : 56|1@0+ (1,0) [0|1] "" ECM,PCM,ECP_X1
 SG_ UpftrRmtVehStrtReqd : 57|1@0+ (1,0) [0|1] "" ECM,PCM,ECP_X1
 SG_ UpftrSnwPlwLoBmDsblReqd : 58|1@0+ (1,0) [0|1] "" ECM,PCM,ECP_X1
 SG_ VODVP_VehOdoDispValAuth_Inv : 59|1@0+ (1,0) [0|1] "" ACP2_MCU,EBCM,ECM,ECP_MC,EOCM,EOCM_HC_Superset,EPS,EPSb,FCM,FOPM,PCM,RDCM,TCCM,TCM,ECP_X1

BO_ 1402 VehSpdAvgDrvn_PCSM_PDU: 8 Vector__XXX
 SG_ VehSpdAvgDrvn_PCSM : 7|64@0+ (1,0) [0|1.84467e+019] "" ACP2_MCU,BSM,VICM,CGM,EOCM,EOCM_HC_Superset,EPSRAa,FCM,PCM,RDCM,TCCM,TCM,ECP_X1

BO_ 614 VehSpdAvgDrvn_Prtctd_PDU: 8 Vector__XXX
 SG_ VSADP_MAC : 7|27@0+ (1,0) [0|1.34218e+008] "" ACP2_MCU,BSM,VICM,CGM,EOCM,EOCM_HC_Superset,EPSRAa,FCM,PCM,RDCM,TCCM,TCM,ECP_X1
 SG_ VSADP_FCnt : 28|5@0+ (1,0) [0|31] "" ACP2_MCU,BSM,VICM,CGM,EOCM,EOCM_HC_Superset,EPSRAa,FCM,PCM,RDCM,TCCM,TCM,ECP_X1
 SG_ VSADP_VehSpdAvgDrvnAuth : 35|15@0+ (0.015625,0) [0|511.984] "km / h" ACP2_MCU,AHL_AFL,ARS,BSM,VECM,VICM,BSM_MH,CGM,DCM,DMS,EBCM,ECP_MC,EOCM,EOCM_HC_Superset,EPSRAa,EPS,EPSb,FCM,FOPM,HUD_CAN,LIB1,NVM,PCM,RDCM,TCCM,TCM,ECP_S,ECP_X1
 SG_ VSADP_RdcdPwrIndOnAuth : 36|1@0+ (1,0) [0|1] "" ACP2_MCU,BSM,VICM,CGM,EOCM,EOCM_HC_Superset,EPSRAa,FCM,PCM,RDCM,TCCM,TCM,VDM,ECP_X1
 SG_ VSADP_FuelModeStsAuth : 39|3@0+ (1,0) [0|4] "" ACP2_MCU,BSM,VICM,CGM,EOCM,EOCM_HC_Superset,EPSRAa,FCM,PCM,RDCM,TCCM,TCM,ECP_X1
 SG_ EngEmsRltMlfIndRq : 48|3@0+ (1,0) [0|4] "" ACP2_MCU,BSM,VICM,CGM,EOCM,EOCM_HC_Superset,EPSRAa,FCM,PCM,RDCM,TCCM,TCM,ECP_X1
 SG_ VSADP_ARC : 50|2@0+ (1,0) [0|3] "" ACP2_MCU,BSM,VICM,CGM,EOCM,EOCM_HC_Superset,EPSRAa,FCM,PCM,RDCM,TCCM,TCM,ECP_X1
 SG_ VSADP_VehSpdAvgDrvnSrcAuth : 51|1@0+ (1,0) [0|1] "" ACP2_MCU,BSM,VICM,CGM,EBCM,EOCM,EOCM_HC_Superset,EPSRAa,EPS,EPSb,FCM,HUD_CAN,PCM,RDCM,TCCM,TCM,ECP_X1
 SG_ VSADP_VehSpdAvgDrvnAuth_Inv : 52|1@0+ (1,0) [0|1] "" ACP2_MCU,BSM,VECM,VICM,CGM,EBCM,EOCM,EOCM_HC_Superset,EPSRAa,EPS,EPSb,FCM,FOPM,HUD_CAN,NVM,PCM,RDCM,TCCM,TCM,ECP_X1
 SG_ VSADP_Filler : 61|6@0+ (1,0) [0|63] "" ACP2_MCU,BSM,VICM,CGM,EOCM,EOCM_HC_Superset,EPSRAa,FCM,PCM,RDCM,TCCM,TCM,ECP_X1

BO_ 1369 VehSpdAvgNDrvn_PCSM_PDU: 8 Vector__XXX
 SG_ VehSpdAvgNDrvn_PCSM : 7|64@0+ (1,0) [0|1.84467e+019] "" ACP2_MCU,AHL_AFL,BSM,VICM,EOCM,EOCM_HC_Superset,FCM,FOPM,RDCM,TCCM

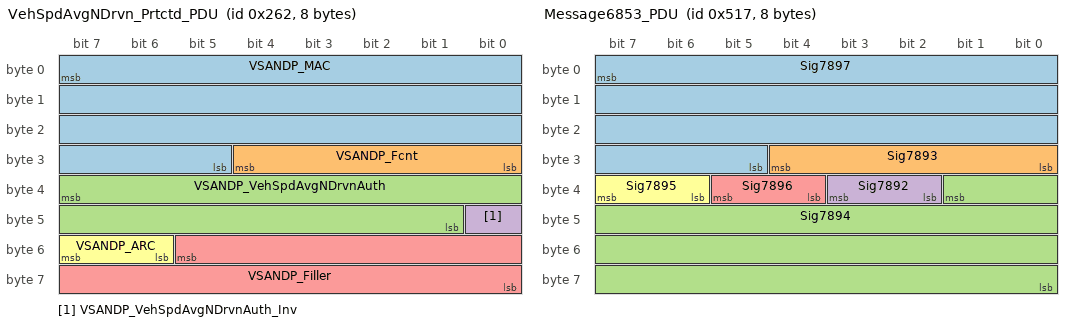
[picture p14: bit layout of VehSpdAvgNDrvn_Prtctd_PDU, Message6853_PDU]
BO_ 610 VehSpdAvgNDrvn_Prtctd_PDU: 8 Vector__XXX
 SG_ VSANDP_MAC : 7|27@0+ (1,0) [0|1.34218e+008] "" ACP2_MCU,AHL_AFL,BSM,VICM,CGM,EOCM,EOCM_HC_Superset,FCM,FOPM,RDCM,TCCM
 SG_ VSANDP_Fcnt : 28|5@0+ (1,0) [0|31] "" ACP2_MCU,AHL_AFL,BSM,VICM,CGM,EOCM,EOCM_HC_Superset,FCM,FOPM,RDCM,TCCM
 SG_ VSANDP_VehSpdAvgNDrvnAuth : 39|15@0+ (0.015625,0) [0|511.984] "Km/h" ACP2_MCU,AHL_AFL,BSM,VICM,CGM,DCM,EOCM,EOCM_HC_Superset,FCM,FOPM,PCM,RDCM,TCCM,TCM,VDM,ECP_X1
 SG_ VSANDP_VehSpdAvgNDrvnAuth_Inv : 40|1@0+ (1,0) [0|1] "" ACP2_MCU,AHL_AFL,BSM,VICM,CGM,DCM,EOCM,EOCM_HC_Superset,FCM,FOPM,RDCM,TCCM,VDM
 SG_ VSANDP_Filler : 53|14@0+ (1,0) [0|16383] "" ACP2_MCU,AHL_AFL,BSM,VICM,CGM,EOCM,EOCM_HC_Superset,FCM,FOPM,RDCM,TCCM
 SG_ VSANDP_ARC : 55|2@0+ (1,0) [0|3] "" ACP2_MCU,AHL_AFL,BSM,VICM,CGM,EOCM,EOCM_HC_Superset,FCM,FOPM,RDCM,TCCM

BO_ 1395 Message6852_PDU: 8 Vector__XXX
 SG_ Sig7939 : 7|64@0+ (1,0) [0|1.84467e+019] "" ACP2_MCU,FCM

BO_ 1303 Message6853_PDU: 8 Vector__XXX
 SG_ Sig7897 : 7|27@0+ (1,0) [0|1.34218e+008] "" ACP2_MCU,FCM
 SG_ Sig7893 : 28|5@0+ (1,0) [0|31] "" ACP2_MCU,FCM
 SG_ Sig7894 : 33|26@0+ (1,0) [0|6.71089e+007] "" ACP2_MCU,FCM
 SG_ Sig7892 : 35|2@0+ (1,0) [0|3] "" ACP2_MCU,FCM
 SG_ Sig7896 : 37|2@0+ (1,0) [0|2] "" ACP2_MCU,FCM
 SG_ Sig7895 : 39|2@0+ (1,0) [0|2] "" ACP2_MCU,FCM

BO_ 1394 WhlDist_PCSM_PDU: 8 Vector__XXX
 SG_ WhlDist_PCSM : 7|64@0+ (1,0) [0|1.84467e+019] "" ACP2_MCU,AHS,ARS,EOCM,EOCM_HC_Superset,EPS,EPSb,FCM,PCM,RDCM,TCCM,TCM

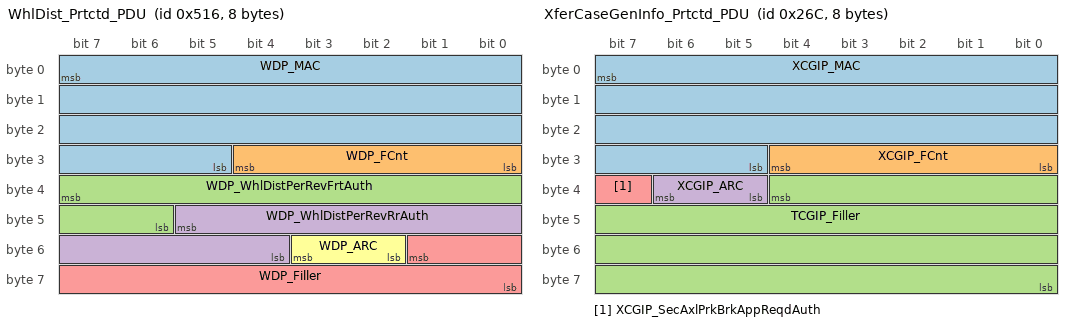
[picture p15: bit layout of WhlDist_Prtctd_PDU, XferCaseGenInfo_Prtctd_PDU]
BO_ 1302 WhlDist_Prtctd_PDU: 8 Vector__XXX
 SG_ WDP_MAC : 7|27@0+ (1,0) [0|1.34218e+008] "" ACP2_MCU,AHS,ARS,CGM,EOCM,EOCM_HC_Superset,EPS,EPSb,FCM,PCM,RDCM,TCCM,TCM
 SG_ WDP_FCnt : 28|5@0+ (1,0) [0|31] "" ACP2_MCU,AHS,ARS,CGM,EOCM,EOCM_HC_Superset,EPS,EPSb,FCM,PCM,RDCM,TCCM,TCM
 SG_ WDP_WhlDistPerRevFrtAuth : 39|10@0+ (3,800) [800|3869] "mm" ACP2_MCU,ADIMa,ADIMb,AHS,ARS,CGM,DCM,EBCM,EOCM,EOCM_HC_Superset,EPS,EPSb,FCM,PCM,RDCM,TCCM,TCM
 SG_ WDP_WhlDistPerRevRrAuth : 45|10@0+ (3,800) [800|3869] "mm" ACP2_MCU,ADIMa,ADIMb,AHS,ARS,CGM,DCM,EBCM,EOCM,EOCM_HC_Superset,EPS,EPSb,FCM,PCM,RDCM,TCCM,TCM
 SG_ WDP_Filler : 49|10@0+ (1,0) [0|1023] "" ACP2_MCU,AHS,ARS,CGM,EOCM,EOCM_HC_Superset,EPS,EPSb,FCM,PCM,RDCM,TCCM,TCM
 SG_ WDP_ARC : 51|2@0+ (1,0) [0|3] "" ACP2_MCU,AHS,ARS,CGM,EOCM,EOCM_HC_Superset,EPS,EPSb,FCM,PCM,RDCM,TCCM,TCM

BO_ 889 XferCaseGenInfo_PCSM_PDU: 8 Vector__XXX
 SG_ XferCaseGenInfo_PCSM : 7|64@0+ (1,0) [0|1.84467e+019] "" EBCM

BO_ 620 XferCaseGenInfo_Prtctd_PDU: 8 Vector__XXX
 SG_ XCGIP_MAC : 7|27@0+ (1,0) [0|1.34218e+008] "" EBCM
 SG_ XCGIP_FCnt : 28|5@0+ (1,0) [0|31] "" EBCM
 SG_ TCGIP_Filler : 36|29@0+ (1,0) [0|5.36871e+008] "" EBCM
 SG_ XCGIP_ARC : 38|2@0+ (1,0) [0|3] "" EBCM
 SG_ XCGIP_SecAxlPrkBrkAppReqdAuth : 39|1@0+ (1,0) [0|1] "" EBCM

BA_DEF_ SG_  "SignalType" STRING ;
BA_DEF_ SG_  "SignalLongName" STRING ;
BA_DEF_ BO_  "GenMsgCycleTime" INT 0 10000;
BA_DEF_ BO_  "GenMsgSendType" ENUM "cyclicX","spontanX","cyclicIfActiveX","spontanWithDelay","cyclicAndSpontanX","cyclicAndSpontanWithDelay","spontanWithRepetition","cyclicIfActiveAndSpontanWD";
BA_DEF_ BO_  "VFrameFormat" ENUM  "StandardCAN","ExtendedCAN","reserved","reserved","reserved","reserved","reserved","reserved","reserved","reserved","reserved","reserved","reserved","reserved","StandardCAN_FD","ExtendedCAN_FD";
BA_DEF_DEF_  "SignalType" "";
BA_DEF_DEF_  "SignalLongName" "";
BA_DEF_DEF_  "GenMsgCycleTime" 0;
BA_DEF_DEF_  "GenMsgSendType" "cyclicX";
BA_DEF_DEF_  "VFrameFormat" "StandardCAN";
BA_ "GenMsgCycleTime" BO_ 58 10;
BA_ "VFrameFormat" BO_ 58 14;
BA_ "VFrameFormat" BO_ 900 14;
BA_ "GenMsgCycleTime" BO_ 90 10;
BA_ "VFrameFormat" BO_ 90 14;
BA_ "GenMsgCycleTime" BO_ 1373 1000;
BA_ "VFrameFormat" BO_ 1373 14;
BA_ "GenMsgCycleTime" BO_ 876 250;
BA_ "VFrameFormat" BO_ 876 14;
BA_ "VFrameFormat" BO_ 899 14;
BA_ "GenMsgCycleTime" BO_ 623 100;
BA_ "VFrameFormat" BO_ 623 14;
BA_ "VFrameFormat" BO_ 898 14;
BA_ "GenMsgCycleTime" BO_ 622 100;
BA_ "VFrameFormat" BO_ 622 14;
BA_ "GenMsgCycleTime" BO_ 1372 1000;
BA_ "VFrameFormat" BO_ 1372 14;
BA_ "GenMsgCycleTime" BO_ 875 250;
BA_ "VFrameFormat" BO_ 875 14;
BA_ "VFrameFormat" BO_ 664 14;
BA_ "GenMsgCycleTime" BO_ 53 10;
BA_ "VFrameFormat" BO_ 53 14;
BA_ "VFrameFormat" BO_ 897 14;
BA_ "GenMsgCycleTime" BO_ 57 10;
BA_ "VFrameFormat" BO_ 57 14;
BA_ "VFrameFormat" BO_ 896 14;
BA_ "GenMsgCycleTime" BO_ 185 50;
BA_ "VFrameFormat" BO_ 185 14;
BA_ "VFrameFormat" BO_ 895 14;
BA_ "GenMsgCycleTime" BO_ 46 12.5;
BA_ "VFrameFormat" BO_ 46 14;
BA_ "VFrameFormat" BO_ 894 14;
BA_ "GenMsgCycleTime" BO_ 102 12.5;
BA_ "VFrameFormat" BO_ 102 14;
BA_ "GenMsgCycleTime" BO_ 96 25;
BA_ "VFrameFormat" BO_ 96 14;
BA_ "VFrameFormat" BO_ 893 14;
BA_ "GenMsgCycleTime" BO_ 91 10;
BA_ "VFrameFormat" BO_ 91 14;
BA_ "GenMsgCycleTime" BO_ 715 100;
BA_ "VFrameFormat" BO_ 715 14;
BA_ "VFrameFormat" BO_ 680 14;
BA_ "GenMsgCycleTime" BO_ 83 10;
BA_ "VFrameFormat" BO_ 83 14;
BA_ "VFrameFormat" BO_ 679 14;
BA_ "GenMsgCycleTime" BO_ 627 100;
BA_ "VFrameFormat" BO_ 627 14;
BA_ "VFrameFormat" BO_ 678 14;
BA_ "GenMsgCycleTime" BO_ 64 10;
BA_ "VFrameFormat" BO_ 64 14;
BA_ "VFrameFormat" BO_ 677 14;
BA_ "GenMsgCycleTime" BO_ 626 100;
BA_ "VFrameFormat" BO_ 626 14;
BA_ "GenMsgCycleTime" BO_ 1396 3500;
BA_ "VFrameFormat" BO_ 1396 14;
BA_ "GenMsgCycleTime" BO_ 1316 1000;
BA_ "VFrameFormat" BO_ 1316 14;
BA_ "GenMsgCycleTime" BO_ 533 25;
BA_ "VFrameFormat" BO_ 533 14;
BA_ "GenMsgCycleTime" BO_ 1171 1000;
BA_ "VFrameFormat" BO_ 1171 14;
BA_ "VFrameFormat" BO_ 1335 14;
BA_ "GenMsgCycleTime" BO_ 1283 1000;
BA_ "VFrameFormat" BO_ 1283 14;
BA_ "GenMsgCycleTime" BO_ 1478 1000;
BA_ "VFrameFormat" BO_ 1478 14;
BA_ "GenMsgCycleTime" BO_ 1340 3500;
BA_ "VFrameFormat" BO_ 1340 14;
BA_ "GenMsgCycleTime" BO_ 1280 1000;
BA_ "VFrameFormat" BO_ 1280 14;
BA_ "VFrameFormat" BO_ 640 14;
BA_ "GenMsgCycleTime" BO_ 597 100;
BA_ "VFrameFormat" BO_ 597 14;
BA_ "GenMsgCycleTime" BO_ 1331 1000;
BA_ "VFrameFormat" BO_ 1331 14;
BA_ "GenMsgCycleTime" BO_ 864 250;
BA_ "VFrameFormat" BO_ 864 14;
BA_ "VFrameFormat" BO_ 675 14;
BA_ "GenMsgCycleTime" BO_ 84 10;
BA_ "VFrameFormat" BO_ 84 14;
BA_ "GenMsgCycleTime" BO_ 1403 1000;
BA_ "VFrameFormat" BO_ 1403 14;
BA_ "GenMsgCycleTime" BO_ 878 250;
BA_ "VFrameFormat" BO_ 878 14;
BA_ "GenMsgCycleTime" BO_ 2147745824 1000;
BA_ "GenMsgCycleTime" BO_ 2147745825 1000;
BA_ "GenMsgCycleTime" BO_ 1358 3500;
BA_ "VFrameFormat" BO_ 1358 14;
BA_ "GenMsgCycleTime" BO_ 1299 1000;
BA_ "VFrameFormat" BO_ 1299 14;
BA_ "GenMsgCycleTime" BO_ 1357 2000;
BA_ "VFrameFormat" BO_ 1357 14;
BA_ "GenMsgCycleTime" BO_ 865 500;
BA_ "VFrameFormat" BO_ 865 14;
BA_ "VFrameFormat" BO_ 1903 14;
BA_ "VFrameFormat" BO_ 1162 14;
BA_ "VFrameFormat" BO_ 1904 14;
BA_ "VFrameFormat" BO_ 1161 14;
BA_ "VFrameFormat" BO_ 1901 14;
BA_ "VFrameFormat" BO_ 1164 14;
BA_ "VFrameFormat" BO_ 1902 14;
BA_ "VFrameFormat" BO_ 1163 14;
BA_ "VFrameFormat" BO_ 1905 14;
BA_ "VFrameFormat" BO_ 1160 14;
BA_ "GenMsgCycleTime" BO_ 1371 1000;
BA_ "VFrameFormat" BO_ 1371 14;
BA_ "GenMsgCycleTime" BO_ 867 25;
BA_ "VFrameFormat" BO_ 867 14;
BA_ "VFrameFormat" BO_ 674 14;
BA_ "GenMsgCycleTime" BO_ 50 12.5;
BA_ "VFrameFormat" BO_ 50 14;
BA_ "VFrameFormat" BO_ 892 14;
BA_ "GenMsgCycleTime" BO_ 45 12.5;
BA_ "VFrameFormat" BO_ 45 14;
BA_ "VFrameFormat" BO_ 891 14;
BA_ "GenMsgCycleTime" BO_ 527 50;
BA_ "VFrameFormat" BO_ 527 14;
BA_ "VFrameFormat" BO_ 1545 14;
BA_ "VFrameFormat" BO_ 1544 14;
BA_ "VFrameFormat" BO_ 1650 14;
BA_ "VFrameFormat" BO_ 1585 14;
BA_ "VFrameFormat" BO_ 1723 14;
BA_ "VFrameFormat" BO_ 1586 14;
BA_ "VFrameFormat" BO_ 1739 14;
BA_ "VFrameFormat" BO_ 1563 14;
BA_ "VFrameFormat" BO_ 1642 14;
BA_ "VFrameFormat" BO_ 1576 14;
BA_ "VFrameFormat" BO_ 1553 14;
BA_ "VFrameFormat" BO_ 1559 14;
BA_ "VFrameFormat" BO_ 1565 14;
BA_ "VFrameFormat" BO_ 1566 14;
BA_ "VFrameFormat" BO_ 1589 14;
BA_ "VFrameFormat" BO_ 1725 14;
BA_ "VFrameFormat" BO_ 1765 14;
BA_ "VFrameFormat" BO_ 1634 14;
BA_ "VFrameFormat" BO_ 1766 14;
BA_ "VFrameFormat" BO_ 1637 14;
BA_ "VFrameFormat" BO_ 1552 14;
BA_ "VFrameFormat" BO_ 1562 14;
BA_ "VFrameFormat" BO_ 1560 14;
BA_ "VFrameFormat" BO_ 1612 14;
BA_ "VFrameFormat" BO_ 1741 14;
BA_ "VFrameFormat" BO_ 2497342705 15;
BA_ "VFrameFormat" BO_ 2497317361 15;
BA_ "VFrameFormat" BO_ 2497317105 15;
BA_ "VFrameFormat" BO_ 2497344241 15;
BA_ "VFrameFormat" BO_ 2565829361 15;
BA_ "VFrameFormat" BO_ 2497327601 15;
BA_ "VFrameFormat" BO_ 2497362929 15;
BA_ "VFrameFormat" BO_ 2497327857 15;
BA_ "VFrameFormat" BO_ 2565812977 15;
BA_ "VFrameFormat" BO_ 2430336753 15;
BA_ "VFrameFormat" BO_ 2497367025 15;
BA_ "VFrameFormat" BO_ 2431385329 15;
BA_ "VFrameFormat" BO_ 2497321969 15;
BA_ "VFrameFormat" BO_ 2497342193 15;
BA_ "VFrameFormat" BO_ 2497325297 15;
BA_ "VFrameFormat" BO_ 2565810417 15;
BA_ "VFrameFormat" BO_ 2497319409 15;
BA_ "VFrameFormat" BO_ 2497320945 15;
BA_ "VFrameFormat" BO_ 2497322481 15;
BA_ "VFrameFormat" BO_ 2497322737 15;
BA_ "VFrameFormat" BO_ 2497340657 15;
BA_ "VFrameFormat" BO_ 2565812721 15;
BA_ "VFrameFormat" BO_ 2497328625 15;
BA_ "VFrameFormat" BO_ 2565813745 15;
BA_ "VFrameFormat" BO_ 2497363441 15;
BA_ "VFrameFormat" BO_ 2497373681 15;
BA_ "VFrameFormat" BO_ 2497340145 15;
BA_ "VFrameFormat" BO_ 2497373937 15;
BA_ "VFrameFormat" BO_ 2497340913 15;
BA_ "VFrameFormat" BO_ 2497319153 15;
BA_ "VFrameFormat" BO_ 2497321713 15;
BA_ "VFrameFormat" BO_ 2497321201 15;
BA_ "VFrameFormat" BO_ 2497334513 15;
BA_ "VFrameFormat" BO_ 2497367537 15;
BA_ "VFrameFormat" BO_ 2497317362 15;
BA_ "VFrameFormat" BO_ 2497317106 15;
BA_ "VFrameFormat" BO_ 2497344242 15;
BA_ "VFrameFormat" BO_ 2497327602 15;
BA_ "VFrameFormat" BO_ 2497362930 15;
BA_ "VFrameFormat" BO_ 2497327858 15;
BA_ "VFrameFormat" BO_ 2430336754 15;
BA_ "VFrameFormat" BO_ 2497367026 15;
BA_ "VFrameFormat" BO_ 2431385330 15;
BA_ "VFrameFormat" BO_ 2497321970 15;
BA_ "VFrameFormat" BO_ 2497342194 15;
BA_ "VFrameFormat" BO_ 2497325298 15;
BA_ "VFrameFormat" BO_ 2497319410 15;
BA_ "VFrameFormat" BO_ 2497320946 15;
BA_ "VFrameFormat" BO_ 2497322482 15;
BA_ "VFrameFormat" BO_ 2497322738 15;
BA_ "VFrameFormat" BO_ 2497342706 15;
BA_ "VFrameFormat" BO_ 2497340658 15;
BA_ "VFrameFormat" BO_ 2497328626 15;
BA_ "VFrameFormat" BO_ 2497363442 15;
BA_ "VFrameFormat" BO_ 2497373682 15;
BA_ "VFrameFormat" BO_ 2497340146 15;
BA_ "VFrameFormat" BO_ 2497373938 15;
BA_ "VFrameFormat" BO_ 2497340914 15;
BA_ "VFrameFormat" BO_ 2497319154 15;
BA_ "VFrameFormat" BO_ 2497321714 15;
BA_ "VFrameFormat" BO_ 2497321202 15;
BA_ "VFrameFormat" BO_ 2497334514 15;
BA_ "VFrameFormat" BO_ 2497367538 15;
BA_ "VFrameFormat" BO_ 2497342708 15;
BA_ "VFrameFormat" BO_ 2497317364 15;
BA_ "VFrameFormat" BO_ 2497317108 15;
BA_ "VFrameFormat" BO_ 2497344244 15;
BA_ "VFrameFormat" BO_ 2497327604 15;
BA_ "VFrameFormat" BO_ 2497362932 15;
BA_ "VFrameFormat" BO_ 2497327860 15;
BA_ "VFrameFormat" BO_ 2430336756 15;
BA_ "VFrameFormat" BO_ 2497367028 15;
BA_ "VFrameFormat" BO_ 2431385332 15;
BA_ "VFrameFormat" BO_ 2497321972 15;
BA_ "VFrameFormat" BO_ 2497342196 15;
BA_ "VFrameFormat" BO_ 2497325300 15;
BA_ "VFrameFormat" BO_ 2497319412 15;
BA_ "VFrameFormat" BO_ 2497320948 15;
BA_ "VFrameFormat" BO_ 2497322484 15;
BA_ "VFrameFormat" BO_ 2497322740 15;
BA_ "VFrameFormat" BO_ 2497340660 15;
BA_ "VFrameFormat" BO_ 2497328628 15;
BA_ "VFrameFormat" BO_ 2497363444 15;
BA_ "VFrameFormat" BO_ 2497373684 15;
BA_ "VFrameFormat" BO_ 2497340148 15;
BA_ "VFrameFormat" BO_ 2497373940 15;
BA_ "VFrameFormat" BO_ 2497340916 15;
BA_ "VFrameFormat" BO_ 2497319156 15;
BA_ "VFrameFormat" BO_ 2497321716 15;
BA_ "VFrameFormat" BO_ 2497321204 15;
BA_ "VFrameFormat" BO_ 2497334516 15;
BA_ "VFrameFormat" BO_ 2497367540 15;
BA_ "VFrameFormat" BO_ 2497342709 15;
BA_ "VFrameFormat" BO_ 2497317365 15;
BA_ "VFrameFormat" BO_ 2497317109 15;
BA_ "VFrameFormat" BO_ 2497344245 15;
BA_ "VFrameFormat" BO_ 2497327605 15;
BA_ "VFrameFormat" BO_ 2497362933 15;
BA_ "VFrameFormat" BO_ 2497327861 15;
BA_ "VFrameFormat" BO_ 2430336757 15;
BA_ "VFrameFormat" BO_ 2497367029 15;
BA_ "VFrameFormat" BO_ 2431385333 15;
BA_ "VFrameFormat" BO_ 2497321973 15;
BA_ "VFrameFormat" BO_ 2497342197 15;
BA_ "VFrameFormat" BO_ 2497325301 15;
BA_ "VFrameFormat" BO_ 2497319413 15;
BA_ "VFrameFormat" BO_ 2497320949 15;
BA_ "VFrameFormat" BO_ 2497322485 15;
BA_ "VFrameFormat" BO_ 2497322741 15;
BA_ "VFrameFormat" BO_ 2497340661 15;
BA_ "VFrameFormat" BO_ 2497328629 15;
BA_ "VFrameFormat" BO_ 2497363445 15;
BA_ "VFrameFormat" BO_ 2497373685 15;
BA_ "VFrameFormat" BO_ 2497340149 15;
BA_ "VFrameFormat" BO_ 2497373941 15;
BA_ "VFrameFormat" BO_ 2497340917 15;
BA_ "VFrameFormat" BO_ 2497319157 15;
BA_ "VFrameFormat" BO_ 2497321717 15;
BA_ "VFrameFormat" BO_ 2497321205 15;
BA_ "VFrameFormat" BO_ 2497334517 15;
BA_ "VFrameFormat" BO_ 2497367541 15;
BA_ "VFrameFormat" BO_ 2497325303 15;
BA_ "VFrameFormat" BO_ 2497320951 15;
BA_ "VFrameFormat" BO_ 2497322487 15;
BA_ "VFrameFormat" BO_ 2497367031 15;
BA_ "VFrameFormat" BO_ 2497379337 15;
BA_ "VFrameFormat" BO_ 2497379336 15;
BA_ "VFrameFormat" BO_ 2497379442 15;
BA_ "VFrameFormat" BO_ 2497379377 15;
BA_ "VFrameFormat" BO_ 2497379515 15;
BA_ "VFrameFormat" BO_ 2497379378 15;
BA_ "VFrameFormat" BO_ 2497379531 15;
BA_ "VFrameFormat" BO_ 2497379355 15;
BA_ "VFrameFormat" BO_ 2497379434 15;
BA_ "VFrameFormat" BO_ 2497379368 15;
BA_ "VFrameFormat" BO_ 2497379345 15;
BA_ "VFrameFormat" BO_ 2497379351 15;
BA_ "VFrameFormat" BO_ 2497379357 15;
BA_ "VFrameFormat" BO_ 2497379358 15;
BA_ "VFrameFormat" BO_ 2497379381 15;
BA_ "VFrameFormat" BO_ 2497379517 15;
BA_ "VFrameFormat" BO_ 2497379557 15;
BA_ "VFrameFormat" BO_ 2497379426 15;
BA_ "VFrameFormat" BO_ 2497379558 15;
BA_ "VFrameFormat" BO_ 2497379429 15;
BA_ "VFrameFormat" BO_ 2497379344 15;
BA_ "VFrameFormat" BO_ 2497379354 15;
BA_ "VFrameFormat" BO_ 2497379352 15;
BA_ "VFrameFormat" BO_ 2497379404 15;
BA_ "VFrameFormat" BO_ 2497379533 15;
BA_ "VFrameFormat" BO_ 2497376620 15;
BA_ "VFrameFormat" BO_ 2497377388 15;
BA_ "VFrameFormat" BO_ 2497377644 15;
BA_ "VFrameFormat" BO_ 2497376521 15;
BA_ "VFrameFormat" BO_ 2497376777 15;
BA_ "VFrameFormat" BO_ 2497377289 15;
BA_ "VFrameFormat" BO_ 2497377545 15;
BA_ "VFrameFormat" BO_ 2497376520 15;
BA_ "VFrameFormat" BO_ 2497376776 15;
BA_ "VFrameFormat" BO_ 2497377288 15;
BA_ "VFrameFormat" BO_ 2497377544 15;
BA_ "VFrameFormat" BO_ 2497376626 15;
BA_ "VFrameFormat" BO_ 2497376882 15;
BA_ "VFrameFormat" BO_ 2497377394 15;
BA_ "VFrameFormat" BO_ 2497377650 15;
BA_ "VFrameFormat" BO_ 2565861746 15;
BA_ "VFrameFormat" BO_ 2497376561 15;
BA_ "VFrameFormat" BO_ 2497376817 15;
BA_ "VFrameFormat" BO_ 2497377329 15;
BA_ "VFrameFormat" BO_ 2497377585 15;
BA_ "VFrameFormat" BO_ 2497376699 15;
BA_ "VFrameFormat" BO_ 2497376955 15;
BA_ "VFrameFormat" BO_ 2497377467 15;
BA_ "VFrameFormat" BO_ 2497377723 15;
BA_ "VFrameFormat" BO_ 2497376562 15;
BA_ "VFrameFormat" BO_ 2497376818 15;
BA_ "VFrameFormat" BO_ 2497377330 15;
BA_ "VFrameFormat" BO_ 2497377586 15;
BA_ "VFrameFormat" BO_ 2565861682 15;
BA_ "VFrameFormat" BO_ 2497376715 15;
BA_ "VFrameFormat" BO_ 2497376971 15;
BA_ "VFrameFormat" BO_ 2497377483 15;
BA_ "VFrameFormat" BO_ 2497377739 15;
BA_ "VFrameFormat" BO_ 2497376539 15;
BA_ "VFrameFormat" BO_ 2497376795 15;
BA_ "VFrameFormat" BO_ 2497377307 15;
BA_ "VFrameFormat" BO_ 2497377563 15;
BA_ "VFrameFormat" BO_ 2497376618 15;
BA_ "VFrameFormat" BO_ 2497376874 15;
BA_ "VFrameFormat" BO_ 2497377386 15;
BA_ "VFrameFormat" BO_ 2497377642 15;
BA_ "VFrameFormat" BO_ 2497376552 15;
BA_ "VFrameFormat" BO_ 2497376808 15;
BA_ "VFrameFormat" BO_ 2497377320 15;
BA_ "VFrameFormat" BO_ 2497377576 15;
BA_ "VFrameFormat" BO_ 2497378088 15;
BA_ "VFrameFormat" BO_ 2565861672 15;
BA_ "VFrameFormat" BO_ 2497376529 15;
BA_ "VFrameFormat" BO_ 2497376785 15;
BA_ "VFrameFormat" BO_ 2497377297 15;
BA_ "VFrameFormat" BO_ 2497377553 15;
BA_ "VFrameFormat" BO_ 2497376535 15;
BA_ "VFrameFormat" BO_ 2497376791 15;
BA_ "VFrameFormat" BO_ 2497377303 15;
BA_ "VFrameFormat" BO_ 2497377559 15;
BA_ "VFrameFormat" BO_ 2497378071 15;
BA_ "VFrameFormat" BO_ 2497376541 15;
BA_ "VFrameFormat" BO_ 2497376797 15;
BA_ "VFrameFormat" BO_ 2497377309 15;
BA_ "VFrameFormat" BO_ 2497377565 15;
BA_ "VFrameFormat" BO_ 2497376542 15;
BA_ "VFrameFormat" BO_ 2497376798 15;
BA_ "VFrameFormat" BO_ 2497377310 15;
BA_ "VFrameFormat" BO_ 2497377566 15;
BA_ "VFrameFormat" BO_ 2497378077 15;
BA_ "VFrameFormat" BO_ 2497376876 15;
BA_ "VFrameFormat" BO_ 2497376612 15;
BA_ "VFrameFormat" BO_ 2497376868 15;
BA_ "VFrameFormat" BO_ 2497377380 15;
BA_ "VFrameFormat" BO_ 2497377636 15;
BA_ "VFrameFormat" BO_ 2565861681 15;
BA_ "VFrameFormat" BO_ 2497376565 15;
BA_ "VFrameFormat" BO_ 2497376821 15;
BA_ "VFrameFormat" BO_ 2497377333 15;
BA_ "VFrameFormat" BO_ 2497377589 15;
BA_ "VFrameFormat" BO_ 2565861685 15;
BA_ "VFrameFormat" BO_ 2497376701 15;
BA_ "VFrameFormat" BO_ 2497376957 15;
BA_ "VFrameFormat" BO_ 2497377469 15;
BA_ "VFrameFormat" BO_ 2497377725 15;
BA_ "VFrameFormat" BO_ 2497376741 15;
BA_ "VFrameFormat" BO_ 2497376997 15;
BA_ "VFrameFormat" BO_ 2497377509 15;
BA_ "VFrameFormat" BO_ 2497377765 15;
BA_ "VFrameFormat" BO_ 2497376610 15;
BA_ "VFrameFormat" BO_ 2497376866 15;
BA_ "VFrameFormat" BO_ 2497377378 15;
BA_ "VFrameFormat" BO_ 2497377634 15;
BA_ "VFrameFormat" BO_ 2497376742 15;
BA_ "VFrameFormat" BO_ 2497376998 15;
BA_ "VFrameFormat" BO_ 2497377510 15;
BA_ "VFrameFormat" BO_ 2497377766 15;
BA_ "VFrameFormat" BO_ 2497376613 15;
BA_ "VFrameFormat" BO_ 2497376869 15;
BA_ "VFrameFormat" BO_ 2497377381 15;
BA_ "VFrameFormat" BO_ 2497377637 15;
BA_ "VFrameFormat" BO_ 2497376528 15;
BA_ "VFrameFormat" BO_ 2497376784 15;
BA_ "VFrameFormat" BO_ 2497377296 15;
BA_ "VFrameFormat" BO_ 2497377552 15;
BA_ "VFrameFormat" BO_ 2497376538 15;
BA_ "VFrameFormat" BO_ 2497376794 15;
BA_ "VFrameFormat" BO_ 2497377306 15;
BA_ "VFrameFormat" BO_ 2497377562 15;
BA_ "VFrameFormat" BO_ 2497376536 15;
BA_ "VFrameFormat" BO_ 2497376792 15;
BA_ "VFrameFormat" BO_ 2497377304 15;
BA_ "VFrameFormat" BO_ 2497377560 15;
BA_ "VFrameFormat" BO_ 2497376588 15;
BA_ "VFrameFormat" BO_ 2497376844 15;
BA_ "VFrameFormat" BO_ 2497377356 15;
BA_ "VFrameFormat" BO_ 2497377612 15;
BA_ "VFrameFormat" BO_ 2497376717 15;
BA_ "VFrameFormat" BO_ 2497376973 15;
BA_ "VFrameFormat" BO_ 2497377485 15;
BA_ "VFrameFormat" BO_ 2497377741 15;
BA_ "VFrameFormat" BO_ 2497378251 15;
BA_ "VFrameFormat" BO_ 2497507593 15;
BA_ "VFrameFormat" BO_ 2497507849 15;
BA_ "VFrameFormat" BO_ 2497508361 15;
BA_ "VFrameFormat" BO_ 2497508617 15;
BA_ "VFrameFormat" BO_ 2497507592 15;
BA_ "VFrameFormat" BO_ 2497507848 15;
BA_ "VFrameFormat" BO_ 2497508360 15;
BA_ "VFrameFormat" BO_ 2497508616 15;
BA_ "VFrameFormat" BO_ 2497507698 15;
BA_ "VFrameFormat" BO_ 2497507954 15;
BA_ "VFrameFormat" BO_ 2497508466 15;
BA_ "VFrameFormat" BO_ 2497508722 15;
BA_ "VFrameFormat" BO_ 2497507633 15;
BA_ "VFrameFormat" BO_ 2497507889 15;
BA_ "VFrameFormat" BO_ 2497508401 15;
BA_ "VFrameFormat" BO_ 2497508657 15;
BA_ "VFrameFormat" BO_ 2497507771 15;
BA_ "VFrameFormat" BO_ 2497508027 15;
BA_ "VFrameFormat" BO_ 2497508539 15;
BA_ "VFrameFormat" BO_ 2497508795 15;
BA_ "VFrameFormat" BO_ 2497507634 15;
BA_ "VFrameFormat" BO_ 2497507890 15;
BA_ "VFrameFormat" BO_ 2497508402 15;
BA_ "VFrameFormat" BO_ 2497508658 15;
BA_ "VFrameFormat" BO_ 2497507787 15;
BA_ "VFrameFormat" BO_ 2497508043 15;
BA_ "VFrameFormat" BO_ 2497508555 15;
BA_ "VFrameFormat" BO_ 2497508811 15;
BA_ "VFrameFormat" BO_ 2497507611 15;
BA_ "VFrameFormat" BO_ 2497507867 15;
BA_ "VFrameFormat" BO_ 2497508379 15;
BA_ "VFrameFormat" BO_ 2497508635 15;
BA_ "VFrameFormat" BO_ 2497507690 15;
BA_ "VFrameFormat" BO_ 2497507946 15;
BA_ "VFrameFormat" BO_ 2497508458 15;
BA_ "VFrameFormat" BO_ 2497508714 15;
BA_ "VFrameFormat" BO_ 2497507624 15;
BA_ "VFrameFormat" BO_ 2497507880 15;
BA_ "VFrameFormat" BO_ 2497508392 15;
BA_ "VFrameFormat" BO_ 2497508648 15;
BA_ "VFrameFormat" BO_ 2497507601 15;
BA_ "VFrameFormat" BO_ 2497507857 15;
BA_ "VFrameFormat" BO_ 2497508369 15;
BA_ "VFrameFormat" BO_ 2497508625 15;
BA_ "VFrameFormat" BO_ 2497507607 15;
BA_ "VFrameFormat" BO_ 2497507863 15;
BA_ "VFrameFormat" BO_ 2497508375 15;
BA_ "VFrameFormat" BO_ 2497508631 15;
BA_ "VFrameFormat" BO_ 2497507613 15;
BA_ "VFrameFormat" BO_ 2497507869 15;
BA_ "VFrameFormat" BO_ 2497508381 15;
BA_ "VFrameFormat" BO_ 2497508637 15;
BA_ "VFrameFormat" BO_ 2497507614 15;
BA_ "VFrameFormat" BO_ 2497507870 15;
BA_ "VFrameFormat" BO_ 2497508382 15;
BA_ "VFrameFormat" BO_ 2497508638 15;
BA_ "VFrameFormat" BO_ 2497507637 15;
BA_ "VFrameFormat" BO_ 2497507893 15;
BA_ "VFrameFormat" BO_ 2497508405 15;
BA_ "VFrameFormat" BO_ 2497508661 15;
BA_ "VFrameFormat" BO_ 2497507773 15;
BA_ "VFrameFormat" BO_ 2497508029 15;
BA_ "VFrameFormat" BO_ 2497508541 15;
BA_ "VFrameFormat" BO_ 2497508797 15;
BA_ "VFrameFormat" BO_ 2497507813 15;
BA_ "VFrameFormat" BO_ 2497508069 15;
BA_ "VFrameFormat" BO_ 2497508581 15;
BA_ "VFrameFormat" BO_ 2497508837 15;
BA_ "VFrameFormat" BO_ 2497507682 15;
BA_ "VFrameFormat" BO_ 2497507938 15;
BA_ "VFrameFormat" BO_ 2497508450 15;
BA_ "VFrameFormat" BO_ 2497508706 15;
BA_ "VFrameFormat" BO_ 2497507814 15;
BA_ "VFrameFormat" BO_ 2497508070 15;
BA_ "VFrameFormat" BO_ 2497508582 15;
BA_ "VFrameFormat" BO_ 2497508838 15;
BA_ "VFrameFormat" BO_ 2497507685 15;
BA_ "VFrameFormat" BO_ 2497507941 15;
BA_ "VFrameFormat" BO_ 2497508453 15;
BA_ "VFrameFormat" BO_ 2497508709 15;
BA_ "VFrameFormat" BO_ 2497507600 15;
BA_ "VFrameFormat" BO_ 2497507856 15;
BA_ "VFrameFormat" BO_ 2497508368 15;
BA_ "VFrameFormat" BO_ 2497508624 15;
BA_ "VFrameFormat" BO_ 2497507610 15;
BA_ "VFrameFormat" BO_ 2497507866 15;
BA_ "VFrameFormat" BO_ 2497508378 15;
BA_ "VFrameFormat" BO_ 2497508634 15;
BA_ "VFrameFormat" BO_ 2497507608 15;
BA_ "VFrameFormat" BO_ 2497507864 15;
BA_ "VFrameFormat" BO_ 2497508376 15;
BA_ "VFrameFormat" BO_ 2497508632 15;
BA_ "VFrameFormat" BO_ 2497507660 15;
BA_ "VFrameFormat" BO_ 2497507916 15;
BA_ "VFrameFormat" BO_ 2497508428 15;
BA_ "VFrameFormat" BO_ 2497508684 15;
BA_ "VFrameFormat" BO_ 2497507789 15;
BA_ "VFrameFormat" BO_ 2497508045 15;
BA_ "VFrameFormat" BO_ 2497508557 15;
BA_ "VFrameFormat" BO_ 2497508813 15;
BA_ "GenMsgCycleTime" BO_ 2147745826 1000;
BA_ "GenMsgCycleTime" BO_ 2147745827 1000;
BA_ "GenMsgCycleTime" BO_ 2147745806 1000;
BA_ "GenMsgCycleTime" BO_ 1257 1000;
BA_ "VFrameFormat" BO_ 1257 14;
BA_ "GenMsgCycleTime" BO_ 1809 1000;
BA_ "VFrameFormat" BO_ 1809 14;
BA_ "VFrameFormat" BO_ 890 14;
BA_ "GenMsgCycleTime" BO_ 621 100;
BA_ "VFrameFormat" BO_ 621 14;
BA_ "GenMsgCycleTime" BO_ 1370 3500;
BA_ "VFrameFormat" BO_ 1370 14;
BA_ "GenMsgCycleTime" BO_ 1298 1000;
BA_ "VFrameFormat" BO_ 1298 14;
BA_ "VFrameFormat" BO_ 1402 14;
BA_ "GenMsgCycleTime" BO_ 614 100;
BA_ "VFrameFormat" BO_ 614 14;
BA_ "VFrameFormat" BO_ 1369 14;
BA_ "GenMsgCycleTime" BO_ 610 100;
BA_ "VFrameFormat" BO_ 610 14;
BA_ "GenMsgCycleTime" BO_ 1395 3500;
BA_ "VFrameFormat" BO_ 1395 14;
BA_ "GenMsgCycleTime" BO_ 1303 1000;
BA_ "VFrameFormat" BO_ 1303 14;
BA_ "GenMsgCycleTime" BO_ 1394 3500;
BA_ "VFrameFormat" BO_ 1394 14;
BA_ "GenMsgCycleTime" BO_ 1302 1000;
BA_ "VFrameFormat" BO_ 1302 14;
BA_ "VFrameFormat" BO_ 889 14;
BA_ "GenMsgCycleTime" BO_ 620 100;
BA_ "VFrameFormat" BO_ 620 14;
BA_ "SignalLongName" SG_ 58 SD36P_MAC "Serial Data 36 Protected : MAC";
BA_ "SignalLongName" SG_ 58 SD36P_FCnt "Serial Data 36 Protected : Freshness Counter";
BA_ "SignalLongName" SG_ 58 DASTP_StrTrqAuth "Serial Data 36 Protected : Driver Applied Steering Torque Authenticated";
BA_ "SignalLongName" SG_ 58 EPSOP_EPSOvrlyTrqDlvdAuth "Serial Data 36 Protected : Electronic Power Steering Overlay Torque Delivered Authenticated";
BA_ "SignalType" SG_ 58 DSIDP_DrvrStrgIntfrDtdAuth_Inv "ENM";
BA_ "SignalLongName" SG_ 58 DSIDP_DrvrStrgIntfrDtdAuth_Inv "Serial Data 36 Protected : Driver Steering Interference Detected Authenticated Invalid";
BA_ "SignalType" SG_ 58 DSIDP_DrvrStrgIntfrDtdAuth "ENM";
BA_ "SignalLongName" SG_ 58 DSIDP_DrvrStrgIntfrDtdAuth "Serial Data 36 Protected : Driver Steering Interference Detected Authenticated";
BA_ "SignalType" SG_ 58 DASTP_StrTrqAuth_Inv "ENM";
BA_ "SignalLongName" SG_ 58 DASTP_StrTrqAuth_Inv "Serial Data 36 Protected : Driver Applied Steering Torque Authenticated Invalid";
BA_ "SignalLongName" SG_ 58 EPSTTDP_TotTorqDlvdAuth "Serial Data 36 Protected : Electronic Power Steering Total Torque Delivered Authenticated";
BA_ "SignalType" SG_ 58 EPSOP_ElecPwStrgTqOvlyStsAuth "ENM";
BA_ "SignalLongName" SG_ 58 EPSOP_ElecPwStrgTqOvlyStsAuth "Serial Data 36 Protected : Electronic Power Steering Torque Overlay Status Authenticated";
BA_ "SignalType" SG_ 58 EPSOP_EPSOvrlyTrqDlvdAuth_Inv "ENM";
BA_ "SignalLongName" SG_ 58 EPSOP_EPSOvrlyTrqDlvdAuth_Inv "Serial Data 36 Protected : Electronic Power Steering Overlay Torque Delivered Authenticated Invalid";
BA_ "SignalType" SG_ 58 SSASI2P_LKAStrgRqCommStsAuth "ENM";
BA_ "SignalLongName" SG_ 58 SSASI2P_LKAStrgRqCommStsAuth "Serial Data 36 Protected : Lane Keeping Assist Steering Request Communication Status Authenticated";
BA_ "SignalType" SG_ 58 SSASI2P_ArbdASStrgRqCommStsAuth "ENM";
BA_ "SignalLongName" SG_ 58 SSASI2P_ArbdASStrgRqCommStsAuth "Serial Data 36 Protected : Arbitrated Active Safety Steering Request Communication Status Authenticated";
BA_ "SignalType" SG_ 58 SSASI2P_AE44StrgRqCommStsAuth "ENM";
BA_ "SignalLongName" SG_ 58 SSASI2P_AE44StrgRqCommStsAuth "Serial Data 36 Protected : Advanced Parking Assist Steering Request Communication Status Authenticated";
BA_ "SignalType" SG_ 58 EPSTTDP_TotTorqDlvdAuth_Inv "ENM";
BA_ "SignalLongName" SG_ 58 EPSTTDP_TotTorqDlvdAuth_Inv "Serial Data 36 Protected : Electronic Power Steering Total Torque Delivered Authenticated Invalid";
BA_ "SignalLongName" SG_ 58 SSASIP_StrgTrqReqOvlyAvalLtAuth "Serial Data 36 Protected : Steering Torque Request Overlay Available Left Authenticated";
BA_ "SignalType" SG_ 58 SSASIP_StrgPerfActlModeAuth "ENM";
BA_ "SignalLongName" SG_ 58 SSASIP_StrgPerfActlModeAuth "Serial Data 36 Protected : Steering Performance Actual Mode Authenticated";
BA_ "SignalType" SG_ 58 SSASIP_StrgAsstThrmlInhbdAuth "ENM";
BA_ "SignalLongName" SG_ 58 SSASIP_StrgAsstThrmlInhbdAuth "Serial Data 36 Protected : Steering Assist Thermal Inhibited Authenticated";
BA_ "SignalType" SG_ 58 SSASIP_StrgAsstStsAuth "ENM";
BA_ "SignalLongName" SG_ 58 SSASIP_StrgAsstStsAuth "Serial Data 36 Protected : Steering Assist Status Authenticated";
BA_ "SignalLongName" SG_ 58 SSASIP_StrgTrqReqOvlyAvalRtAuth "Serial Data 36 Protected : Steering Torque Request Overlay Available Right Authenticated";
BA_ "SignalType" SG_ 58 SWHOP_ArbdStrgFtrReqActvAuth "ENM";
BA_ "SignalLongName" SG_ 58 SWHOP_ArbdStrgFtrReqActvAuth "Serial Data 36 Protected : Arbitrated Steering Feature Request Active Authenticated";
BA_ "SignalType" SG_ 58 SSASIP_StrgWhlTrqIntegStsAuth "ENM";
BA_ "SignalLongName" SG_ 58 SSASIP_StrgWhlTrqIntegStsAuth "Serial Data 36 Protected : Steering Wheel Torque Integrity Status Authenticated";
BA_ "SignalType" SG_ 58 SSASIP_StrgWhlAngIntegStsAuth "ENM";
BA_ "SignalLongName" SG_ 58 SSASIP_StrgWhlAngIntegStsAuth "Serial Data 36 Protected : Steering Wheel Angle Integrity Status Authenticated";
BA_ "SignalType" SG_ 58 SWHOP_StrgWhlHndsOffDtnStatAuth "ENM";
BA_ "SignalLongName" SG_ 58 SWHOP_StrgWhlHndsOffDtnStatAuth "Serial Data 36 Protected : Steering Wheel Hands Off Detection State Authenticated";
BA_ "SignalType" SG_ 58 SWHOP_StrgWhlHndsOffDtnModeAuth "ENM";
BA_ "SignalLongName" SG_ 58 SWHOP_StrgWhlHndsOffDtnModeAuth "Serial Data 36 Protected : Steering Wheel Hands Off Detection Mode Authenticated";
BA_ "SignalType" SG_ 58 SWHOP_StrgWhlHndsOffDtnCnfdLvlAu "ENM";
BA_ "SignalLongName" SG_ 58 SWHOP_StrgWhlHndsOffDtnCnfdLvlAu "Serial Data 36 Protected : Steering Wheel Hands Off Detection Confidence Level Authenticated";
BA_ "SignalLongName" SG_ 58 SD36P_Filler "Serial Data 36 Protected : Filler";
BA_ "SignalLongName" SG_ 58 SD36P_ARC "Serial Data 36 Protected : Alive Rolling Count";
BA_ "SignalLongName" SG_ 900 Sig6868 "Signal6650";
BA_ "SignalLongName" SG_ 90 Sig5735 "Signal6632";
BA_ "SignalLongName" SG_ 90 Sig5733 "Signal6631";
BA_ "SignalLongName" SG_ 90 Sig0315 "Signal6633";
BA_ "SignalLongName" SG_ 90 Sig0320 "Signal6638";
BA_ "SignalLongName" SG_ 90 Sig0327 "Signal6647";
BA_ "SignalLongName" SG_ 90 Sig0323 "Signal6643";
BA_ "SignalLongName" SG_ 90 Sig2544 "Signal6628";
BA_ "SignalLongName" SG_ 90 Sig0317 "Signal6635";
BA_ "SignalType" SG_ 90 Sig0319 "ENM";
BA_ "SignalLongName" SG_ 90 Sig0319 "Signal6637";
BA_ "SignalType" SG_ 90 Sig0313 "ENM";
BA_ "SignalLongName" SG_ 90 Sig0313 "Signal6627";
BA_ "SignalType" SG_ 90 Sig0325 "ENM";
BA_ "SignalLongName" SG_ 90 Sig0325 "Signal6645";
BA_ "SignalType" SG_ 90 Sig0322 "ENM";
BA_ "SignalLongName" SG_ 90 Sig0322 "Signal6642";
BA_ "SignalType" SG_ 90 Sig6953 "ENM";
BA_ "SignalLongName" SG_ 90 Sig6953 "Signal6640";
BA_ "SignalType" SG_ 90 Sig0318 "ENM";
BA_ "SignalLongName" SG_ 90 Sig0318 "Signal6636";
BA_ "SignalType" SG_ 90 Sig0316 "ENM";
BA_ "SignalLongName" SG_ 90 Sig0316 "Signal6634";
BA_ "SignalType" SG_ 90 Sig0314 "ENM";
BA_ "SignalLongName" SG_ 90 Sig0314 "Signal6648";
BA_ "SignalType" SG_ 90 Sig6956 "ENM";
BA_ "SignalLongName" SG_ 90 Sig6956 "Signal6641";
BA_ "SignalType" SG_ 90 Sig0328 "ENM";
BA_ "SignalLongName" SG_ 90 Sig0328 "Signal6649";
BA_ "SignalLongName" SG_ 90 Sig5734 "Signal6630";
BA_ "SignalType" SG_ 90 Sig2545 "ENM";
BA_ "SignalLongName" SG_ 90 Sig2545 "Signal6629";
BA_ "SignalType" SG_ 90 Sig0326 "ENM";
BA_ "SignalLongName" SG_ 90 Sig0326 "Signal6646";
BA_ "SignalType" SG_ 90 Sig0324 "ENM";
BA_ "SignalLongName" SG_ 90 Sig0324 "Signal6644";
BA_ "SignalType" SG_ 90 Sig0321 "ENM";
BA_ "SignalLongName" SG_ 90 Sig0321 "Signal6639";
BA_ "SignalLongName" SG_ 90 Sig5732 "Signal6626";
BA_ "SignalLongName" SG_ 1373 SrlDat3_PCSM "Serial Data 3 Protected Counter Sync Message";
BA_ "SignalLongName" SG_ 876 SD3_MAC "Serial Data 3 Protected : MAC";
BA_ "SignalLongName" SG_ 876 SD3_FCnt "Serial Data 3 Protected : Freshness Counter";
BA_ "SignalType" SG_ 876 BVSCP_BdyCtlTopSpdLimReqTypAuth "ENM";
BA_ "SignalLongName" SG_ 876 BVSCP_BdyCtlTopSpdLimReqTypAuth "Serial Data 3 Protected : Body Control Top Speed Limit Request Type Authenticated";
BA_ "SignalType" SG_ 876 BGI4P_AutoShtdnRstAuth "ENM";
BA_ "SignalLongName" SG_ 876 BGI4P_AutoShtdnRstAuth "Serial Data 3 Protected : Automatic Shutdown Reset Authenticated";
BA_ "SignalType" SG_ 876 BGI4P_AutoShtdnAllwdAuth "ENM";
BA_ "SignalLongName" SG_ 876 BGI4P_AutoShtdnAllwdAuth "Serial Data 3 Protected : Automatic Shutdown Allowed Authenticated";
BA_ "SignalType" SG_ 876 BGI4P_AirDflctOffCycCrTkStAuth "ENM";
BA_ "SignalLongName" SG_ 876 BGI4P_AirDflctOffCycCrTkStAuth "Serial Data 3 Protected : Air Deflector Off Cycle Credit Tracking State Authenticated";
BA_ "SignalType" SG_ 876 BASHPLP_BrkSnsrHmPstnLrndAuth "ENM";
BA_ "SignalLongName" SG_ 876 BASHPLP_BrkSnsrHmPstnLrndAuth "Serial Data 3 Protected : Brake Applied Sensor Home Position Learned Authenticated";
BA_ "SignalLongName" SG_ 876 BVSCP_BdyCtlTopSpdLimReqValAuth "Serial Data 3 Protected : Body Control Top Speed Limit Request Value Authenticated";
BA_ "SignalType" SG_ 876 DSIP_E44MSw3StkAuth "ENM";
BA_ "SignalLongName" SG_ 876 DSIP_E44MSw3StkAuth "Serial Data 3 Protected : Platform Analog Mode Switch 3 Stuck Authenticated";
BA_ "SignalType" SG_ 876 DSIP_E44MSw2StkAuth "ENM";
BA_ "SignalLongName" SG_ 876 DSIP_E44MSw2StkAuth "Serial Data 3 Protected : Platform Analog Mode Switch 2 Stuck Authenticated";
BA_ "SignalType" SG_ 876 DSIP_E44MSw1StkAuth "ENM";
BA_ "SignalLongName" SG_ 876 DSIP_E44MSw1StkAuth "Serial Data 3 Protected : Platform Analog Mode Switch 1 Stuck Authenticated";
BA_ "SignalType" SG_ 876 BdyCtlTopSpdLimSrcAuth "ENM";
BA_ "SignalLongName" SG_ 876 BdyCtlTopSpdLimSrcAuth "Serial Data 3 Protected : Body Control Top Speed Limit Source Authenticated";
BA_ "SignalType" SG_ 876 BdyCtlTopSpdLimIndOnAuth "ENM";
BA_ "SignalLongName" SG_ 876 BdyCtlTopSpdLimIndOnAuth "Serial Data 3 Protected : Body Control Top Speed Limit Indication On Authenticated";
BA_ "SignalType" SG_ 876 BdyCtlAccelLimIndOnAuth "ENM";
BA_ "SignalLongName" SG_ 876 BdyCtlAccelLimIndOnAuth "Serial Data 3 Protected : Body Control Acceleration Limit Indication On Authenticated";
BA_ "SignalLongName" SG_ 876 VCKIP_InfltblRstrntKeyIdfrAuth "Serial Data 3 Protected : Inflatable Restraints Key Identifier Authenticated";
BA_ "SignalType" SG_ 876 RIP_FrtCmptRelEnblReqAuth "ENM";
BA_ "SignalLongName" SG_ 876 RIP_FrtCmptRelEnblReqAuth "Serial Data 3 Protected : Front Storage Compartment Release Enable Request Authenticated";
BA_ "SignalType" SG_ 876 DSIP_E44MSwStsAuth "ENM";
BA_ "SignalLongName" SG_ 876 DSIP_E44MSwStsAuth "Serial Data 3 Protected : Platform Analog Mode Switch Status Authenticated";
BA_ "SignalType" SG_ 876 DSIP_E44MSwDrvrModeSwStkAuth "ENM";
BA_ "SignalLongName" SG_ 876 DSIP_E44MSwDrvrModeSwStkAuth "Serial Data 3 Protected : Platform Analog Mode Switch Driver Mode Switch Stuck Authenticated";
BA_ "SignalType" SG_ 876 DSIP_E44MSw4StkAuth "ENM";
BA_ "SignalLongName" SG_ 876 DSIP_E44MSw4StkAuth "Serial Data 3 Protected : Platform Analog Mode Switch 4 Stuck Authenticated";
BA_ "SignalLongName" SG_ 876 SD3_ARC "Serial Data 3 Protected : Alive Rolling Count";
BA_ "SignalLongName" SG_ 876 SD3P_Filler "Serial Data 3 Protected : Filler";
BA_ "SignalType" SG_ 876 LoVltg12VBatMntModeReqd "ENM";
BA_ "SignalLongName" SG_ 876 LoVltg12VBatMntModeReqd "Serial Data 3 Protected : Low Voltage 12V Battery Maintenance Mode Requested";
BA_ "SignalLongName" SG_ 876 SD3P_FillerExtnd "Serial Data 3 Protected : Filler Extended";
BA_ "SignalLongName" SG_ 899 SrlDat40_PCSM "Serial Data 40 Protected Counter Sync Message";
BA_ "SignalLongName" SG_ 623 SD40P_MAC "Serial Data 40 Protected : MAC";
BA_ "SignalLongName" SG_ 623 SD40P_FCnt "Serial Data 40 Protected : Freshness Counter";
BA_ "SignalLongName" SG_ 623 LSCMBABP_ReqdAccelAuth "Serial Data 40 Protected : Low Speed Collision Mitigation Braking Autonomous Brake Requested Acceleration Authenticated";
BA_ "SignalType" SG_ 623 LSCMBABP_ReqActvAuth "ENM";
BA_ "SignalLongName" SG_ 623 LSCMBABP_ReqActvAuth "Serial Data 40 Protected : Low Speed Collision Mitigation Braking Autonomous Brake Request Active Authenticated";
BA_ "SignalLongName" SG_ 623 RLDWCTOP_TrqOvrlyValAuth "Serial Data 40 Protected : Request Lane Detection Warning and Control Torque Overlay Value Authenticated";
BA_ "SignalType" SG_ 623 RLDWCTOP_TrqOvrlyActAuth_Inv "ENM";
BA_ "SignalLongName" SG_ 623 RLDWCTOP_TrqOvrlyActAuth_Inv "Serial Data 40 Protected : Request Lane Detection Warning and Control Torque Overlay Active Authenticated Invalid";
BA_ "SignalType" SG_ 623 RLDWCTOP_TrqOvrlyActAuth_DuD "ENM";
BA_ "SignalLongName" SG_ 623 RLDWCTOP_TrqOvrlyActAuth_DuD "Serial Data 40 Protected : Request Lane Detection Warning and Control Torque Overlay Active Authenticated Don't Use Data";
BA_ "SignalType" SG_ 623 RLDWCTOP_TrqOvrlyActAuth "ENM";
BA_ "SignalLongName" SG_ 623 RLDWCTOP_TrqOvrlyActAuth "Serial Data 40 Protected : Request Lane Detection Warning and Control Torque Overlay Active Authenticated";
BA_ "SignalType" SG_ 623 LSCMBABP_TypAuth "ENM";
BA_ "SignalLongName" SG_ 623 LSCMBABP_TypAuth "Serial Data 40 Protected : Low Speed Collision Mitigation Braking Autonomous Brake Type Authenticated";
BA_ "SignalType" SG_ 623 RLDWCTOP_TrqOvrlyValAuth_DuD "ENM";
BA_ "SignalLongName" SG_ 623 RLDWCTOP_TrqOvrlyValAuth_DuD "Serial Data 40 Protected : Request Lane Detection Warning and Control Torque Overlay Value Authenticated Don't Use Data";
BA_ "SignalLongName" SG_ 623 SD40P_Filler "Serial Data 40 Protected : Filler";
BA_ "SignalLongName" SG_ 623 SD40P_ARC "Serial Data 40 Protected : Alive Rolling Count";
BA_ "SignalType" SG_ 623 RLDWCTOP_TrqOvrlyValAuth_Inv "ENM";
BA_ "SignalLongName" SG_ 623 RLDWCTOP_TrqOvrlyValAuth_Inv "Serial Data 40 Protected : Request Lane Detection Warning and Control Torque Overlay Value Authenticated Invalid";
BA_ "SignalLongName" SG_ 898 SrlDat42_PCSM "Serial Data 42 Protected Counter Sync Message";
BA_ "SignalLongName" SG_ 622 SD42P_MAC "Serial Data 42 Protected : MAC";
BA_ "SignalLongName" SG_ 622 SD42P_FCnt "Serial Data 42 Protected : Freshness Counter";
BA_ "SignalLongName" SG_ 622 SD42P_Filler "Serial Data 42 Protected : Filler";
BA_ "SignalLongName" SG_ 622 SD42P_ARC "Serial Data 42 Protected : Alive Rolling Count";
BA_ "SignalType" SG_ 622 HMIGI2P_LnFllwgInterFltDtdAuth "ENM";
BA_ "SignalLongName" SG_ 622 HMIGI2P_LnFllwgInterFltDtdAuth "Serial Data 42 Protected : Lane Following Interface Fault Detected Authenticated";
BA_ "SignalType" SG_ 622 HMIGI2P_IPCFlrIndOnAuth "ENM";
BA_ "SignalLongName" SG_ 622 HMIGI2P_IPCFlrIndOnAuth "Serial Data 42 Protected : Instrument Panel Cluster Failure Indication On Authenticated";
BA_ "SignalType" SG_ 622 HMIGI1P_TrlrBrkDispActvAuth_DuD "ENM";
BA_ "SignalLongName" SG_ 622 HMIGI1P_TrlrBrkDispActvAuth_DuD "Serial Data 42 Protected : Trailer Brake Display Active Authenticated Don't Use Data";
BA_ "SignalType" SG_ 622 HMIGI1P_TrlrBrkDispActvAuth "ENM";
BA_ "SignalLongName" SG_ 622 HMIGI1P_TrlrBrkDispActvAuth "Serial Data 42 Protected : Trailer Brake Display Active Authenticated";
BA_ "SignalType" SG_ 622 HMIGI1P_EnvModPrsntRspdr4Auth "ENM";
BA_ "SignalLongName" SG_ 622 HMIGI1P_EnvModPrsntRspdr4Auth "Serial Data 42 Protected : Environment Module Present Responder #4 Authenticated";
BA_ "SignalLongName" SG_ 1372 SrlDat43_PCSM "Serial Data 43 Protected Counter Sync Message";
BA_ "SignalLongName" SG_ 875 SD43P_MAC "Serial Data 43 Protected : MAC";
BA_ "SignalLongName" SG_ 875 SD43P_FCnt "Serial Data 43 Protected : Freshness Counter";
BA_ "SignalLongName" SG_ 875 CTGI1P_CnvtTpSpLimRqValAuth "Serial Data 43 Protected : Convertible Top Speed Limit Request Value Authenticated";
BA_ "SignalType" SG_ 875 CTGI1P_CnvtTpSpLimRqTypAuth "ENM";
BA_ "SignalLongName" SG_ 875 CTGI1P_CnvtTpSpLimRqTypAuth "Serial Data 43 Protected : Convertible Top Speed Limit Request Type Authenticated";
BA_ "SignalLongName" SG_ 875 SD43P_ARC "Serial Data 43 Protected : Alive Rolling Count";
BA_ "SignalType" SG_ 875 CnvtTopModSpdLimIndOnAuth "ENM";
BA_ "SignalLongName" SG_ 875 CnvtTopModSpdLimIndOnAuth "Serial Data 43 Protected : Convertible Top Module Speed Limit Indication On Authenticated";
BA_ "SignalLongName" SG_ 664 SrlDat44_PCSM "Serial Data 44 Protected Counter Sync Message";
BA_ "SignalLongName" SG_ 53 SD44P_MAC "Serial Data 44 Protected : MAC";
BA_ "SignalLongName" SG_ 53 SD44P_FCnt "Serial Data 44 Protected : Freshness Counter";
BA_ "SignalLongName" SG_ 53 SSID1P_LatAccelAuth "Serial Data 44 Protected : Lateral Acceleration Authenticated";
BA_ "SignalLongName" SG_ 53 SSID1P_LngAccelAuth "Serial Data 44 Protected : Longitudinal Acceleration Authenticated";
BA_ "SignalType" SG_ 53 SSID1P_LatAccelAuth_Inv "ENM";
BA_ "SignalLongName" SG_ 53 SSID1P_LatAccelAuth_Inv "Serial Data 44 Protected : Lateral Acceleration Authenticated Invalid";
BA_ "SignalLongName" SG_ 53 SSID2P_PtchRateAuth "Serial Data 44 Protected : Pitch Rate Authenticated";
BA_ "SignalType" SG_ 53 SSID1P_LngAccelAuth_Inv "ENM";
BA_ "SignalLongName" SG_ 53 SSID1P_LngAccelAuth_Inv "Serial Data 44 Protected : Longitudinal Acceleration Authenticated Invalid";
BA_ "SignalLongName" SG_ 53 SSID2P_VertAccelAuth "Serial Data 44 Protected : Vertical Acceleration Authenticated";
BA_ "SignalType" SG_ 53 SSID2P_PtchRateAuth_Inv "ENM";
BA_ "SignalLongName" SG_ 53 SSID2P_PtchRateAuth_Inv "Serial Data 44 Protected : Pitch Rate Authenticated Invalid";
BA_ "SignalLongName" SG_ 53 SSID3P_RollRateAuth "Serial Data 44 Protected : Roll Rate Authenticated";
BA_ "SignalType" SG_ 53 SSID2P_VertAccelAuth_Inv "ENM";
BA_ "SignalLongName" SG_ 53 SSID2P_VertAccelAuth_Inv "Serial Data 44 Protected : Vertical Acceleration Authenticated Invalid";
BA_ "SignalLongName" SG_ 53 SSID3P_YawRateAuth "Serial Data 44 Protected : Yaw Rate Authenticated";
BA_ "SignalType" SG_ 53 SSID3P_RollRateAuth_Inv "ENM";
BA_ "SignalLongName" SG_ 53 SSID3P_RollRateAuth_Inv "Serial Data 44 Protected : Roll Rate Authenticated Invalid";
BA_ "SignalLongName" SG_ 53 SSID4P_LFAuth "Serial Data 44 Protected : Wheel Vertical Acceleration Left Front Authenticated";
BA_ "SignalType" SG_ 53 SSID3P_YawRateAuth_Inv "ENM";
BA_ "SignalLongName" SG_ 53 SSID3P_YawRateAuth_Inv "Serial Data 44 Protected : Yaw Rate Authenticated Invalid";
BA_ "SignalLongName" SG_ 53 SSID4P_RFAuth "Serial Data 44 Protected : Wheel Vertical Acceleration Right Front Authenticated";
BA_ "SignalType" SG_ 53 SSID4P_LFAuth_Inv "ENM";
BA_ "SignalLongName" SG_ 53 SSID4P_LFAuth_Inv "Serial Data 44 Protected : Wheel Vertical Acceleration Left Front Authenticated Invalid";
BA_ "SignalLongName" SG_ 53 SSID5P_LRAuth "Serial Data 44 Protected : Wheel Vertical Acceleration Left Rear Authenticated";
BA_ "SignalType" SG_ 53 SSID4P_RFAuth_Inv "ENM";
BA_ "SignalLongName" SG_ 53 SSID4P_RFAuth_Inv "Serial Data 44 Protected : Wheel Vertical Acceleration Right Front Authenticated Invalid";
BA_ "SignalLongName" SG_ 53 SSID5P_RRAuth "Serial Data 44 Protected : Wheel Vertical Acceleration Right Rear Authenticated";
BA_ "SignalType" SG_ 53 SSID5P_LRAuth_Inv "ENM";
BA_ "SignalLongName" SG_ 53 SSID5P_LRAuth_Inv "Serial Data 44 Protected : Wheel Vertical Acceleration Left Rear Authenticated Invalid";
BA_ "SignalLongName" SG_ 53 SD44P_Filler "Serial Data 44 Protected : Filler";
BA_ "SignalLongName" SG_ 53 SD44P_ARC "Serial Data 44 Protected : Alive Rolling Count";
BA_ "SignalType" SG_ 53 SSID5P_RRAuth_Inv "ENM";
BA_ "SignalLongName" SG_ 53 SSID5P_RRAuth_Inv "Serial Data 44 Protected : Wheel Vertical Acceleration Right Rear Authenticated Invalid";
BA_ "SignalLongName" SG_ 897 SrlDat46_PCSM "Serial Data 46 Protected Counter Sync Message";
BA_ "SignalLongName" SG_ 57 SD46P_MAC "Serial Data 46 Protected : MAC";
BA_ "SignalLongName" SG_ 57 SD46P_FCnt "Serial Data 46 Protected : Freshness Counter";
BA_ "SignalLongName" SG_ 57 LatAccelAuth "Serial Data 46 Protected : Lateral Acceleration Authenticated";
BA_ "SignalLongName" SG_ 57 LongAccelAuth "Serial Data 46 Protected : Longitudinal Acceleration Authenticated";
BA_ "SignalType" SG_ 57 LatAccelSnsrCorrStsAuth "ENM";
BA_ "SignalLongName" SG_ 57 LatAccelSnsrCorrStsAuth "Serial Data 46 Protected : Lateral Acceleration Sensor Correlation Status Authenticated";
BA_ "SignalType" SG_ 57 LatAccelAuth_Inv "ENM";
BA_ "SignalLongName" SG_ 57 LatAccelAuth_Inv "Serial Data 46 Protected : Lateral Acceleration Authenticated Invalid";
BA_ "SignalType" SG_ 57 LongAccelAuth_Inv "ENM";
BA_ "SignalLongName" SG_ 57 LongAccelAuth_Inv "Serial Data 46 Protected : Longitudinal Acceleration Authenticated Invalid";
BA_ "SignalLongName" SG_ 57 YRP_RollRateAuth "Serial Data 46 Protected : Roll Rate Authenticated";
BA_ "SignalType" SG_ 57 VehAccelCalAuth "ENM";
BA_ "SignalLongName" SG_ 57 VehAccelCalAuth "Serial Data 46 Protected : Vehicle Acceleration Calibrated Authenticated";
BA_ "SignalType" SG_ 57 LongAccelSnsrCorrStsAuth "ENM";
BA_ "SignalLongName" SG_ 57 LongAccelSnsrCorrStsAuth "Serial Data 46 Protected : Longitudinal Acceleration Sensor Correlation Status Authenticated";
BA_ "SignalLongName" SG_ 57 YawRateAuth "Serial Data 46 Protected : Yaw Rate Authenticated";
BA_ "SignalType" SG_ 57 YRP_RollRateAuth_Inv "ENM";
BA_ "SignalLongName" SG_ 57 YRP_RollRateAuth_Inv "Serial Data 46 Protected : Roll Rate Authenticated Invalid";
BA_ "SignalType" SG_ 57 YRP_RollRateAuth_DuD "ENM";
BA_ "SignalLongName" SG_ 57 YRP_RollRateAuth_DuD "Serial Data 46 Protected : Roll Rate Authenticated Don't Use Data";
BA_ "SignalType" SG_ 57 YawRateAuth_DuD "ENM";
BA_ "SignalLongName" SG_ 57 YawRateAuth_DuD "Serial Data 46 Protected : Yaw Rate Authenticated Don't Use Data";
BA_ "SignalLongName" SG_ 57 SD46P_Filler "Serial Data 46 Protected : Filler";
BA_ "SignalLongName" SG_ 57 SD46P_ARC "Serial Data 46 Protected : Alive Rolling Count";
BA_ "SignalType" SG_ 57 YawRateCorrAuth "ENM";
BA_ "SignalLongName" SG_ 57 YawRateCorrAuth "Serial Data 46 Protected : Yaw Rate Correlation Authenticated";
BA_ "SignalType" SG_ 57 YawRateAuth_Inv "ENM";
BA_ "SignalLongName" SG_ 57 YawRateAuth_Inv "Serial Data 46 Protected : Yaw Rate Authenticated Invalid";
BA_ "SignalLongName" SG_ 57 SD46P_FillerExtnd "Serial Data 46 Protected : Filler Extended";
BA_ "SignalType" SG_ 57 VehAccelAuth_DuD "ENM";
BA_ "SignalLongName" SG_ 57 VehAccelAuth_DuD "Serial Data 46 Protected : Vehicle Acceleration Authenticated Don't Use Data";
BA_ "SignalLongName" SG_ 896 SrlDat47_PCSM "Serial Data 47 Protected Counter Sync Message";
BA_ "SignalLongName" SG_ 185 SD47P_MAC "Serial Data 47 Protected : MAC";
BA_ "SignalLongName" SG_ 185 SD47P_FCnt "Serial Data 47 Protected : Freshness Counter";
BA_ "SignalLongName" SG_ 185 LatAccelRwAuth "Serial Data 47 Protected : Lateral Acceleration Raw Authenticated";
BA_ "SignalLongName" SG_ 185 LngAccelRwAuth "Serial Data 47 Protected : Longitudinal Acceleration Raw Authenticated";
BA_ "SignalLongName" SG_ 185 SD47P_Filler "Serial Data 47 Protected : Filler";
BA_ "SignalLongName" SG_ 185 SD47P_ARC "Serial Data 47 Protected : Alive Rolling Count";
BA_ "SignalLongName" SG_ 895 Sig6870 "Signal6719";
BA_ "SignalLongName" SG_ 46 Sig5744 "Signal6693";
BA_ "SignalLongName" SG_ 46 Sig5741 "Signal6689";
BA_ "SignalLongName" SG_ 46 Sig0608 "Signal6683";
BA_ "SignalLongName" SG_ 46 Sig0611 "Signal6684";
BA_ "SignalType" SG_ 46 Sig7523 "ENM";
BA_ "SignalLongName" SG_ 46 Sig7523 "Signal6690";
BA_ "SignalLongName" SG_ 46 Sig7524 "Signal6691";
BA_ "SignalType" SG_ 46 Sig7526 "ENM";
BA_ "SignalLongName" SG_ 46 Sig7526 "Signal6694";
BA_ "SignalType" SG_ 46 Sig7525 "ENM";
BA_ "SignalLongName" SG_ 46 Sig7525 "Signal6692";
BA_ "SignalLongName" SG_ 46 Sig7527 "Signal6695";
BA_ "SignalType" SG_ 46 Sig7531 "ENM";
BA_ "SignalLongName" SG_ 46 Sig7531 "Signal6707";
BA_ "SignalType" SG_ 46 Sig7530 "ENM";
BA_ "SignalLongName" SG_ 46 Sig7530 "Signal6704";
BA_ "SignalLongName" SG_ 46 Sig7532 "Signal6708";
BA_ "SignalLongName" SG_ 46 TGIP_TransGrRatAuth "Serial Data 48 Protected : Transmission Gear Ratio Authenticated";
BA_ "SignalType" SG_ 46 TGIP_TransGrRatStatAuth "ENM";
BA_ "SignalLongName" SG_ 46 TGIP_TransGrRatStatAuth "Serial Data 48 Protected : Transmission Gear Ratio State Authenticated";
BA_ "SignalType" SG_ 46 TGIP_TransGrRatAuth_Inv "ENM";
BA_ "SignalLongName" SG_ 46 TGIP_TransGrRatAuth_Inv "Serial Data 48 Protected : Transmission Gear Ratio Authenticated Invalid";
BA_ "SignalLongName" SG_ 46 Sig7549 "Signal6713";
BA_ "SignalType" SG_ 46 Sig7548 "ENM";
BA_ "SignalLongName" SG_ 46 Sig7548 "Signal6712";
BA_ "SignalLongName" SG_ 46 Sig7552 "Signal6716";
BA_ "SignalType" SG_ 46 Sig7551 "ENM";
BA_ "SignalLongName" SG_ 46 Sig7551 "Signal6715";
BA_ "SignalType" SG_ 46 Sig7550 "ENM";
BA_ "SignalLongName" SG_ 46 Sig7550 "Signal6714";
BA_ "SignalType" SG_ 46 TORSP_TransOutRotnDirAuth "ENM";
BA_ "SignalLongName" SG_ 46 TORSP_TransOutRotnDirAuth "Serial Data 48 Protected : Transmission Output Rotation Direction Authenticated";
BA_ "SignalLongName" SG_ 46 Sig7575 "Signal6717";
BA_ "SignalType" SG_ 46 Sig7574 "ENM";
BA_ "SignalLongName" SG_ 46 Sig7574 "Signal6697";
BA_ "SignalType" SG_ 46 Sig7573 "ENM";
BA_ "SignalLongName" SG_ 46 Sig7573 "Signal6696";
BA_ "SignalType" SG_ 46 Sig7572 "ENM";
BA_ "SignalLongName" SG_ 46 Sig7572 "Signal6686";
BA_ "SignalType" SG_ 46 Sig7571 "ENM";
BA_ "SignalLongName" SG_ 46 Sig7571 "Signal6685";
BA_ "SignalLongName" SG_ 46 Sig7632 "Signal6709";
BA_ "SignalType" SG_ 46 Sig7576 "ENM";
BA_ "SignalLongName" SG_ 46 Sig7576 "Signal6718";
BA_ "SignalLongName" SG_ 46 Sig0638 "Signal6682";
BA_ "SignalLongName" SG_ 46 Sig5740 "Signal6681";
BA_ "SignalType" SG_ 46 Sig7634 "ENM";
BA_ "SignalLongName" SG_ 46 Sig7634 "Signal6711";
BA_ "SignalType" SG_ 46 Sig7633 "ENM";
BA_ "SignalLongName" SG_ 46 Sig7633 "Signal6710";
BA_ "SignalLongName" SG_ 46 Sig7582 "Signal6706";
BA_ "SignalType" SG_ 46 Sig7581 "ENM";
BA_ "SignalLongName" SG_ 46 Sig7581 "Signal6705";
BA_ "SignalType" SG_ 46 Sig7580 "ENM";
BA_ "SignalLongName" SG_ 46 Sig7580 "Signal6703";
BA_ "SignalLongName" SG_ 46 Sig7625 "Signal6700";
BA_ "SignalLongName" SG_ 46 Sig7627 "Signal6702";
BA_ "SignalType" SG_ 46 Sig7623 "ENM";
BA_ "SignalLongName" SG_ 46 Sig7623 "Signal6698";
BA_ "SignalLongName" SG_ 46 Sig5742 "Signal6687";
BA_ "SignalLongName" SG_ 46 Sig5743 "Signal6688";
BA_ "SignalType" SG_ 46 Sig7626 "ENM";
BA_ "SignalLongName" SG_ 46 Sig7626 "Signal6701";
BA_ "SignalType" SG_ 46 Sig7624 "ENM";
BA_ "SignalLongName" SG_ 46 Sig7624 "Signal6699";
BA_ "SignalLongName" SG_ 894 SrlDat50_PCSM "Serial Data 50 Protected Counter Sync Message";
BA_ "SignalLongName" SG_ 102 SD50P_MAC "Serial Data 50 Protected : MAC";
BA_ "SignalLongName" SG_ 102 SD50P_FCnt "Serial Data 50 Protected : Freshness Counter";
BA_ "SignalType" SG_ 102 VICMI3P_AccPPS1OORFltAuth "ENM";
BA_ "SignalLongName" SG_ 102 VICMI3P_AccPPS1OORFltAuth "Serial Data 50 Protected : Accelerator Pedal Position Sensor 1 Out of Range Fault Authenticated";
BA_ "SignalType" SG_ 102 VICMI3P_AccPPS1OORErrCmpstAuth "ENM";
BA_ "SignalLongName" SG_ 102 VICMI3P_AccPPS1OORErrCmpstAuth "Serial Data 50 Protected : Accelerator Pedal Position Sensor 1 Out of Range Error Composite Authenticated";
BA_ "SignalType" SG_ 102 EDActr4DischrgCmdAuth "ENM";
BA_ "SignalLongName" SG_ 102 EDActr4DischrgCmdAuth "Serial Data 50 Protected : Electric Discharge Actuator 4 Discharge Command Authenticated";
BA_ "SignalType" SG_ 102 EDActr3DischrgCmdAuth "ENM";
BA_ "SignalLongName" SG_ 102 EDActr3DischrgCmdAuth "Serial Data 50 Protected : Electric Discharge Actuator 3 Discharge Command Authenticated";
BA_ "SignalLongName" SG_ 102 VICMI3P_ArbdAccPPPriAuth "Serial Data 50 Protected : Arbitrated Accelerator Pedal Position Primary Authenticated";
BA_ "SignalType" SG_ 102 VICMI3P_AccPPS2OORFltCmpstAuth "ENM";
BA_ "SignalLongName" SG_ 102 VICMI3P_AccPPS2OORFltCmpstAuth "Serial Data 50 Protected : Accelerator Pedal Position Sensor 2 Out of Range Fault Composite Authenticated";
BA_ "SignalType" SG_ 102 VICMI3P_AccPPS2OORErrCmpstAuth "ENM";
BA_ "SignalLongName" SG_ 102 VICMI3P_AccPPS2OORErrCmpstAuth "Serial Data 50 Protected : Accelerator Pedal Position Sensor 2 Out of Range Error Composite Authenticated";
BA_ "SignalType" SG_ 102 VICMI3P_AccPPS1n2DsgrFltAuth "ENM";
BA_ "SignalLongName" SG_ 102 VICMI3P_AccPPS1n2DsgrFltAuth "Serial Data 50 Protected : Accelerator Pedal Position Sensors 1 and 2 Disagree Fault Authenticated";
BA_ "SignalType" SG_ 102 VICMI3P_AccPPS1n2DsgrErrAuth "ENM";
BA_ "SignalLongName" SG_ 102 VICMI3P_AccPPS1n2DsgrErrAuth "Serial Data 50 Protected : Accelerator Pedal Position Sensors 1 and 2 Disagree Error Authenticated";
BA_ "SignalType" SG_ 102 VICMI3P_AccPPS1OORFltCmpstAuth "ENM";
BA_ "SignalLongName" SG_ 102 VICMI3P_AccPPS1OORFltCmpstAuth "Serial Data 50 Protected : Accelerator Pedal Position Sensor 1 Out of Range Fault Composite Authenticated";
BA_ "SignalType" SG_ 102 VICMI3P_ArbdAccPPRedntFltAuth "ENM";
BA_ "SignalLongName" SG_ 102 VICMI3P_ArbdAccPPRedntFltAuth "Serial Data 50 Protected : Arbitrated Accelerator Pedal Position Forced Idle Request Authenticated";
BA_ "SignalLongName" SG_ 102 PrplSysInvrtACoolTempAuth "Serial Data 50 Protected : Propulsion System Inverter A Coolant Temperature Authenticated";
BA_ "SignalType" SG_ 102 ElecTransRngHVBkupSplyFltPrAuth "ENM";
BA_ "SignalLongName" SG_ 102 ElecTransRngHVBkupSplyFltPrAuth "Serial Data 50 Protected : Electronic Transmission Range HV Backup Supply Fault Present Authenticated";
BA_ "SignalLongName" SG_ 102 SD50P_ARC "Serial Data 50 Protected : Alive Rolling Count";
BA_ "SignalLongName" SG_ 102 PrplSysInvrtBCoolTempAuth "Serial Data 50 Protected : Propulsion System Inverter B Coolant Temperature Authenticated";
BA_ "SignalType" SG_ 102 PrplSysInvrtACoolTempAuth_Inv "ENM";
BA_ "SignalLongName" SG_ 102 PrplSysInvrtACoolTempAuth_Inv "Serial Data 50 Protected : Propulsion System Inverter A Coolant Temperature Authenticated Invalid";
BA_ "SignalLongName" SG_ 102 PrplSysInvrtCCoolTempAuth "Serial Data 50 Protected : Propulsion System Inverter C Coolant Temperature Authenticated";
BA_ "SignalType" SG_ 102 PrplSysInvrtBCoolTempAuth_Inv "ENM";
BA_ "SignalLongName" SG_ 102 PrplSysInvrtBCoolTempAuth_Inv "Serial Data 50 Protected : Propulsion System Inverter B Coolant Temperature Authenticated Invalid";
BA_ "SignalLongName" SG_ 102 SD50P_Filler "Serial Data 50 Protected : Filler";
BA_ "SignalType" SG_ 102 PrplSysInvrtCCoolTempAuth_Inv "ENM";
BA_ "SignalLongName" SG_ 102 PrplSysInvrtCCoolTempAuth_Inv "Serial Data 50 Protected : Propulsion System Inverter C Coolant Temperature Authenticated Invalid";
BA_ "SignalLongName" SG_ 96 PrplSysMtrASpdAuth "Serial Data 57 Protected : Propulsion System Motor A Speed Authenticated";
BA_ "SignalType" SG_ 96 PrplSysMtrASpdAuth_Inv "ENM";
BA_ "SignalLongName" SG_ 96 PrplSysMtrASpdAuth_Inv "Serial Data 57 Protected : Propulsion System Motor A Speed Authenticated Invalid";
BA_ "SignalLongName" SG_ 893 SrlDat58_PCSM "Serial Data 58 Protected Counter Sync Message";
BA_ "SignalLongName" SG_ 91 SD58P_MAC "Serial Data 58 Protected : MAC";
BA_ "SignalLongName" SG_ 91 SD58P_FCnt "Serial Data 58 Protected : Freshness Counter";
BA_ "SignalLongName" SG_ 91 RrStrgRdWhlAngAuth "Serial Data 58 Protected : Rear Steering Road Wheel Angle Authenticated";
BA_ "SignalType" SG_ 91 RrStrgActlModeAuth "ENM";
BA_ "SignalLongName" SG_ 91 RrStrgActlModeAuth "Serial Data 58 Protected : Rear Steering Actual Mode Authenticated";
BA_ "SignalType" SG_ 91 RrStrgOprtlStsAuth "ENM";
BA_ "SignalLongName" SG_ 91 RrStrgOprtlStsAuth "Serial Data 58 Protected : Rear Steering Operational Status Authenticated";
BA_ "SignalType" SG_ 91 RrStrgAlgnCmpltAuth "ENM";
BA_ "SignalLongName" SG_ 91 RrStrgAlgnCmpltAuth "Serial Data 58 Protected : Rear Steering Alignment Complete Authenticated";
BA_ "SignalLongName" SG_ 91 SD58P_Filler "Serial Data 58 Protected : Filler";
BA_ "SignalType" SG_ 91 RrStrgActlPerfMode "ENM";
BA_ "SignalLongName" SG_ 91 RrStrgActlPerfMode "Serial Data 58 Protected : Rear Steering Actual Performance Mode";
BA_ "SignalType" SG_ 91 RrStrgRdWhlAngAuth_Inv "ENM";
BA_ "SignalLongName" SG_ 91 RrStrgRdWhlAngAuth_Inv "Serial Data 58 Protected : Rear Steering Road Wheel Angle Authenticated Invalid";
BA_ "SignalType" SG_ 91 RrStrgRdWhlAngAuth_DuD "ENM";
BA_ "SignalLongName" SG_ 91 RrStrgRdWhlAngAuth_DuD "Serial Data 58 Protected : Rear Steering Road Wheel Angle Authenticated Don't Use Data";
BA_ "SignalLongName" SG_ 91 SD58P_ARC "Serial Data 58 Protected : Alive Rolling Count";
BA_ "SignalLongName" SG_ 715 LIB1DS2_DTCIdx "Serial Data 60 : Lithium-Ion Battery 1 Diagnostic Status 2 Diagnostic Trouble Code Index";
BA_ "SignalType" SG_ 715 LIB1DS1_DTCSts "ENM";
BA_ "SignalLongName" SG_ 715 LIB1DS1_DTCSts "Serial Data 60 : Lithium-Ion Battery 1 Diagnostic Status 1 Diagnostic Trouble Code Status";
BA_ "SignalLongName" SG_ 715 LIB1DS1_DTCIdx "Serial Data 60 : Lithium-Ion Battery 1 Diagnostic Status 1 Diagnostic Trouble Code Index";
BA_ "SignalLongName" SG_ 715 LIB1DS3_DTCIdx "Serial Data 60 : Lithium-Ion Battery 1 Diagnostic Status 3 Diagnostic Trouble Code Index";
BA_ "SignalType" SG_ 715 LIB1DS2_DTCSts "ENM";
BA_ "SignalLongName" SG_ 715 LIB1DS2_DTCSts "Serial Data 60 : Lithium-Ion Battery 1 Diagnostic Status 2 Diagnostic Trouble Code Status";
BA_ "SignalType" SG_ 715 LIB1DS3_DTCSts "ENM";
BA_ "SignalLongName" SG_ 715 LIB1DS3_DTCSts "Serial Data 60 : Lithium-Ion Battery 1 Diagnostic Status 3 Diagnostic Trouble Code Status";
BA_ "SignalLongName" SG_ 715 SD60_CS "Serial Data 60 : Checksum";
BA_ "SignalLongName" SG_ 715 SD60_ARC "Serial Data 60 : Alive Rolling Count";
BA_ "SignalLongName" SG_ 680 SrlDat61_PCSM "Serial Data 61 Protected Counter Sync Message";
BA_ "SignalLongName" SG_ 83 SD61P_MAC "Serial Data 61 Protected : MAC";
BA_ "SignalLongName" SG_ 83 SD61P_FCnt "Serial Data 61 Protected : Freshness Counter";
BA_ "SignalLongName" SG_ 83 DrvrAppStrgTrqAuth "Serial Data 61 Protected : Driver Applied Steering Torque Authenticated";
BA_ "SignalType" SG_ 83 ArbdStrgFtrReqActvAuth "ENM";
BA_ "SignalLongName" SG_ 83 ArbdStrgFtrReqActvAuth "Serial Data 61 Protected : Arbitrated Steering Feature Request Active Authenticated";
BA_ "SignalType" SG_ 83 DrvrAppStrgTrqAuth_Inv "ENM";
BA_ "SignalLongName" SG_ 83 DrvrAppStrgTrqAuth_Inv "Serial Data 61 Protected : Driver Applied Steering Torque Authenticated Invalid";
BA_ "SignalType" SG_ 83 StrgWhlHndsOffDtnStatAuth "ENM";
BA_ "SignalLongName" SG_ 83 StrgWhlHndsOffDtnStatAuth "Serial Data 61 Protected : Steering Wheel Hands Off Detection State Authenticated";
BA_ "SignalType" SG_ 83 StrgWhlHndsOffDtnModeAuth "ENM";
BA_ "SignalLongName" SG_ 83 StrgWhlHndsOffDtnModeAuth "Serial Data 61 Protected : Steering Wheel Hands Off Detection Mode Authenticated";
BA_ "SignalType" SG_ 83 StrgWhlHndsOffDtnCnfdLvlAuth "ENM";
BA_ "SignalLongName" SG_ 83 StrgWhlHndsOffDtnCnfdLvlAuth "Serial Data 61 Protected : Steering Wheel Hands Off Detection Confidence Level Authenticated";
BA_ "SignalType" SG_ 83 DrvrStrgIntfrDtdAuth_Inv "ENM";
BA_ "SignalLongName" SG_ 83 DrvrStrgIntfrDtdAuth_Inv "Serial Data 61 Protected : Driver Steering Interference Detected Authenticated Invalid";
BA_ "SignalType" SG_ 83 DrvrStrgIntfrDtdAuth "ENM";
BA_ "SignalLongName" SG_ 83 DrvrStrgIntfrDtdAuth "Serial Data 61 Protected : Driver Steering Interference Detected Authenticated";
BA_ "SignalLongName" SG_ 83 SD61P_ARC "Serial Data 61 Protected : Alive Rolling Count";
BA_ "SignalLongName" SG_ 679 SrlDat62_PCSM "Serial Data 62 Protected Counter Sync Message";
BA_ "SignalLongName" SG_ 627 SD62P_MAC "Serial Data 62 Protected : MAC";
BA_ "SignalLongName" SG_ 627 SD62P_FCnt "Serial Data 62 Protected : Freshness Counter";
BA_ "SignalLongName" SG_ 627 ElecPSOvrlyTrqDlvdAuth "Serial Data 62 Protected : Electronic Power Steering Overlay Torque Delivered Authenticated";
BA_ "SignalType" SG_ 627 ArbdActvSftyStrgReqCommStsAuth "ENM";
BA_ "SignalLongName" SG_ 627 ArbdActvSftyStrgReqCommStsAuth "Serial Data 62 Protected : Arbitrated Active Safety Steering Request Communication Status Authenticated";
BA_ "SignalType" SG_ 627 AE44StrgReqCommStsAuth "ENM";
BA_ "SignalLongName" SG_ 627 AE44StrgReqCommStsAuth "Serial Data 62 Protected : Advanced Parking Assist Steering Request Communication Status Authenticated";
BA_ "SignalLongName" SG_ 627 SD62P_ARC "Serial Data 62 Protected : Alive Rolling Count";
BA_ "SignalType" SG_ 627 LnKpAsstStrgReqCommStsAuth "ENM";
BA_ "SignalLongName" SG_ 627 LnKpAsstStrgReqCommStsAuth "Serial Data 62 Protected : Lane Keeping Assist Steering Request Communication Status Authenticated";
BA_ "SignalType" SG_ 627 ElecPSTrqOvrlyStsAuth "ENM";
BA_ "SignalLongName" SG_ 627 ElecPSTrqOvrlyStsAuth "Serial Data 62 Protected : Electronic Power Steering Torque Overlay Status Authenticated";
BA_ "SignalType" SG_ 627 ElecPSOvrlyTrqDlvdAuth_Inv "ENM";
BA_ "SignalLongName" SG_ 627 ElecPSOvrlyTrqDlvdAuth_Inv "Serial Data 62 Protected : Electronic Power Steering Overlay Torque Delivered Authenticated Invalid";
BA_ "SignalLongName" SG_ 678 SrlDat63_PCSM "Serial Data 63 Protected Counter Sync Message";
BA_ "SignalLongName" SG_ 64 SD63P_MAC "Serial Data 63 Protected : MAC";
BA_ "SignalLongName" SG_ 64 SD63P_FCnt "Serial Data 63 Protected : Freshness Counter";
BA_ "SignalLongName" SG_ 64 ElecPSTotTrqDlvdAuth "Serial Data 63 Protected : Electronic Power Steering Total Torque Delivered Authenticated";
BA_ "SignalLongName" SG_ 64 SD63P_Filler "Serial Data 63 Protected : Filler";
BA_ "SignalLongName" SG_ 64 SD63P_ARC "Serial Data 63 Protected : Alive Rolling Count";
BA_ "SignalType" SG_ 64 ElecPSTotTrqDlvdAuth_Inv "ENM";
BA_ "SignalLongName" SG_ 64 ElecPSTotTrqDlvdAuth_Inv "Serial Data 63 Protected : Electronic Power Steering Total Torque Delivered Authenticated Invalid";
BA_ "SignalLongName" SG_ 677 SrlDat64_PCSM "Serial Data 64 Protected Counter Sync Message";
BA_ "SignalLongName" SG_ 626 SD64P_MAC "Serial Data 64 Protected : MAC";
BA_ "SignalLongName" SG_ 626 SD64P_FCnt "Serial Data 64 Protected : Freshness Counter";
BA_ "SignalLongName" SG_ 626 StrgTrqReqOvrlyAvalLtAuth "Serial Data 64 Protected : Steering Torque Request Overlay Available Left Authenticated";
BA_ "SignalType" SG_ 626 StrgPerfActlModeAuth "ENM";
BA_ "SignalLongName" SG_ 626 StrgPerfActlModeAuth "Serial Data 64 Protected : Steering Performance Actual Mode Authenticated";
BA_ "SignalType" SG_ 626 StrgAsstThrmlInhbdAuth "ENM";
BA_ "SignalLongName" SG_ 626 StrgAsstThrmlInhbdAuth "Serial Data 64 Protected : Steering Assist Thermal Inhibited Authenticated";
BA_ "SignalType" SG_ 626 StrgAsstStsAuth "ENM";
BA_ "SignalLongName" SG_ 626 StrgAsstStsAuth "Serial Data 64 Protected : Steering Assist Status Authenticated";
BA_ "SignalLongName" SG_ 626 StrgTrqReqOvrlyAvalRtAuth "Serial Data 64 Protected : Steering Torque Request Overlay Available Right Authenticated";
BA_ "SignalLongName" SG_ 626 SD64P_ARC "Serial Data 64 Protected : Alive Rolling Count";
BA_ "SignalType" SG_ 626 StrgWhlTrqIntegStsAuth "ENM";
BA_ "SignalLongName" SG_ 626 StrgWhlTrqIntegStsAuth "Serial Data 64 Protected : Steering Wheel Torque Integrity Status Authenticated";
BA_ "SignalType" SG_ 626 StrgWhlAngIntegStsAuth "ENM";
BA_ "SignalLongName" SG_ 626 StrgWhlAngIntegStsAuth "Serial Data 64 Protected : Steering Wheel Angle Integrity Status Authenticated";
BA_ "SignalLongName" SG_ 1396 SrlDat6_PCSM "Serial Data 6 Protected Counter Sync Message";
BA_ "SignalLongName" SG_ 1316 SD6P_MAC "Serial Data 6 Protected : MAC";
BA_ "SignalLongName" SG_ 1316 SD6P_FCnt "Serial Data 6 Protected : Freshness Counter";
BA_ "SignalLongName" SG_ 1316 VKI2P_AuthIntrUserIdDevCntAuth "Serial Data 6 Protected : Authenticated Interior User Identification Device Count Authenticated";
BA_ "SignalType" SG_ 1316 TDAP_TeenDrvrActvAuth "ENM";
BA_ "SignalLongName" SG_ 1316 TDAP_TeenDrvrActvAuth "Serial Data 6 Protected : Teen Driver Active Authenticated";
BA_ "SignalType" SG_ 1316 RIP_RmtIgnBlkImbCustClrCmdAuth "ENM";
BA_ "SignalLongName" SG_ 1316 RIP_RmtIgnBlkImbCustClrCmdAuth "Serial Data 6 Protected : Remote Ignition Block Immobilization Customer Clear Command Authenticated";
BA_ "SignalType" SG_ 1316 RIP_NewFobXmtrLrndNtfnAuth "ENM";
BA_ "SignalLongName" SG_ 1316 RIP_NewFobXmtrLrndNtfnAuth "Serial Data 6 Protected : New Fob Transmitter Learned Notification Authenticated";
BA_ "SignalType" SG_ 1316 FTPP_VirtCtlHdPrkLmpsAvalAuth "ENM";
BA_ "SignalLongName" SG_ 1316 FTPP_VirtCtlHdPrkLmpsAvalAuth "Serial Data 6 Protected : Virtual Control Head and Park Lamps Available Authenticated";
BA_ "SignalType" SG_ 1316 FTPP_HdPrkLmpsCurrSeltnValAuth "ENM";
BA_ "SignalLongName" SG_ 1316 FTPP_HdPrkLmpsCurrSeltnValAuth "Serial Data 6 Protected : Head and Park Lamps Current Selection Value Authenticated";
BA_ "SignalType" SG_ 1316 VMMP_VehMtnMvmtStatAuth "ENM";
BA_ "SignalLongName" SG_ 1316 VMMP_VehMtnMvmtStatAuth "Serial Data 6 Protected : Vehicle Motion Movement State Authenticated";
BA_ "SignalType" SG_ 1316 VKI2P_FobAvlStsAuth "ENM";
BA_ "SignalLongName" SG_ 1316 VKI2P_FobAvlStsAuth "Serial Data 6 Protected : Fob Availability Status Authenticated";
BA_ "SignalLongName" SG_ 1316 SD6P_Filler "Serial Data 6 Protected : Filler";
BA_ "SignalType" SG_ 1316 AuthIntrUserIdDevSts "ENM";
BA_ "SignalLongName" SG_ 1316 AuthIntrUserIdDevSts "Serial Data 6 Protected : Authenticated Interior User Identification Device Status";
BA_ "SignalLongName" SG_ 1316 SD6P_ARC "Serial Data 6 Protected : Alive Rolling Count";
BA_ "SignalType" SG_ 533 E49ModeActv "ENM";
BA_ "SignalLongName" SG_ 533 E49ModeActv "Serial Data 71 : Power Take Off Mode Active";
BA_ "SignalLongName" SG_ 533 Sig5749 "Signal6749";
BA_ "SignalLongName" SG_ 533 Sig5748 "Signal6748";
BA_ "SignalType" SG_ 1171 RrStrgModeDispIndReq "ENM";
BA_ "SignalLongName" SG_ 1171 RrStrgModeDispIndReq "Serial Data 80 : Rear Steering Mode Display Indication Request";
BA_ "SignalType" SG_ 1171 RrStrgFlrIndOn "ENM";
BA_ "SignalLongName" SG_ 1171 RrStrgFlrIndOn "Serial Data 80 : Rear Steering Failure Indication On";
BA_ "SignalLongName" SG_ 1171 Sig5751 "Signal6751";
BA_ "SignalLongName" SG_ 1171 Sig5750 "Signal6750";
BA_ "SignalLongName" SG_ 1335 SrlDat87_PCSM "Serial Data 87 Protected Counter Sync Message";
BA_ "SignalLongName" SG_ 1283 SD87P_MAC "Serial Data 87 Protected : MAC";
BA_ "SignalLongName" SG_ 1283 SD87P_FCnt "Serial Data 87 Protected : Freshness Counter";
BA_ "SignalLongName" SG_ 1283 PnCActnReqCertfctNumAuth "Serial Data 87 Protected : Plug And Charge Action Request Certificate Number Authenticated";
BA_ "SignalType" SG_ 1283 PnCActnReqCertfctTypAuth "ENM";
BA_ "SignalLongName" SG_ 1283 PnCActnReqCertfctTypAuth "Serial Data 87 Protected : Plug And Charge Action Request Certificate Type Authenticated";
BA_ "SignalType" SG_ 1283 PnCActnReqCertfctOpAuth "ENM";
BA_ "SignalLongName" SG_ 1283 PnCActnReqCertfctOpAuth "Serial Data 87 Protected : Plug And Charge Action Request Certificate Operation Authenticated";
BA_ "SignalLongName" SG_ 1283 SD87P_ARC "Serial Data 87 Protected : Alive Rolling Count";
BA_ "SignalType" SG_ 1283 PnCEnblReqAuth "ENM";
BA_ "SignalLongName" SG_ 1283 PnCEnblReqAuth "Serial Data 87 Protected : Plug And Charge Enable Request Authenticated";
BA_ "SignalLongName" SG_ 1478 CCCGI_FrtBlwFanSpdFdbkRtlzd "Serial Data 8 : Climate Control Cabin Front Blower Fan Speed Feedback Rationalized";
BA_ "SignalLongName" SG_ 1478 ClmCtlCbnCndnsgHtrPwrReq "Serial Data 8 : Climate Control Cabin Condensing Heater Power Request";
BA_ "SignalType" SG_ 1478 CCCGI_FrtBlwFanSpdFdbkRtlzd_Inv "ENM";
BA_ "SignalLongName" SG_ 1478 CCCGI_FrtBlwFanSpdFdbkRtlzd_Inv "Serial Data 8 : Climate Control Cabin Front Blower Fan Speed Feedback Rationalized Invalid";
BA_ "SignalLongName" SG_ 1478 ClmCtlCbnCndnsgHtrTgtTemp "Serial Data 8 : Climate Control Cabin Condensing Heater Target Temperature";
BA_ "SignalLongName" SG_ 1478 ClmCtlCbnFrtEvpCoolPwrReq "Serial Data 8 : Climate Control Cabin Front Evaporator Cooling Power Request";
BA_ "SignalLongName" SG_ 1478 ClmCtlCbnRecircAirFlapPstn "Serial Data 8 : Climate Control Cabin Recirculation Air Flap Position";
BA_ "SignalType" SG_ 1478 ClmCtlCbnFrtEvpCoolPwrReq_DuD "ENM";
BA_ "SignalLongName" SG_ 1478 ClmCtlCbnFrtEvpCoolPwrReq_DuD "Serial Data 8 : Climate Control Cabin Front Evaporator Cooling Power Request Don't Use Data";
BA_ "SignalLongName" SG_ 1478 ClmCtlCbnTgtFrtEvpAirTemp "Serial Data 8 : Climate Control Cabin Target Front Evaporator Air Temperature";
BA_ "SignalType" SG_ 1478 ClmCtlCbnRecircAirFlapPstn_Inv "ENM";
BA_ "SignalLongName" SG_ 1478 ClmCtlCbnRecircAirFlapPstn_Inv "Serial Data 8 : Climate Control Cabin Recirculation Air Flap Position Invalid";
BA_ "SignalLongName" SG_ 1478 SD8_CS "Serial Data 8 : Checksum";
BA_ "SignalLongName" SG_ 1478 SD8_ARC "Serial Data 8 : Alive Rolling Count";
BA_ "SignalLongName" SG_ 1340 SrlDat90_PCSM "Serial Data 90 Protected Counter Sync Message";
BA_ "SignalLongName" SG_ 1280 SD90P_MAC "Serial Data 90 Protected : MAC";
BA_ "SignalLongName" SG_ 1280 SD90P_FCnt "Serial Data 90 Protected : Freshness Counter";
BA_ "SignalLongName" SG_ 1280 SD90P_Filler "Serial Data 90 Protected : Filler";
BA_ "SignalType" SG_ 1280 RmtProgPstInstlClnupActvAuth "ENM";
BA_ "SignalLongName" SG_ 1280 RmtProgPstInstlClnupActvAuth "Serial Data 90 Protected : Remote Programming Post Install Cleanup Active Authenticated";
BA_ "SignalType" SG_ 1280 RmtProgInstlPndgActvAuth "ENM";
BA_ "SignalLongName" SG_ 1280 RmtProgInstlPndgActvAuth "Serial Data 90 Protected : Remote Programming Install Pending Active Authenticated";
BA_ "SignalLongName" SG_ 640 SrlDat92_PCSM "Serial Data 92 Protected Counter Sync Message";
BA_ "SignalLongName" SG_ 597 SD92P_MAC "Serial Data 92 Protected : MAC";
BA_ "SignalLongName" SG_ 597 SD92P_FCnt "Serial Data 92 Protected : Freshness Counter";
BA_ "SignalLongName" SG_ 597 VirtKeyMblDevDgtlKeyIdxAuth "Serial Data 92 Protected : Virtual Key Mobile Device Digital Key Index Authenticated";
BA_ "SignalType" SG_ 597 SuprRmtPrkVirtKeyPrkCmdAuth "ENM";
BA_ "SignalLongName" SG_ 597 SuprRmtPrkVirtKeyPrkCmdAuth "Serial Data 92 Protected : Supervised Remote Parking Virtual Key Parking Command Authenticated";
BA_ "SignalType" SG_ 597 SuprRmtPrkVirtKeyEntlmtStsAuth "ENM";
BA_ "SignalLongName" SG_ 597 SuprRmtPrkVirtKeyEntlmtStsAuth "Serial Data 92 Protected : Supervised Remote Parking Virtual Key Entitlement Status Authenticated";
BA_ "SignalLongName" SG_ 597 VirtKeyMblDevLocDirAuth "Serial Data 92 Protected : Virtual Key Mobile Device Location Direction Authenticated";
BA_ "SignalLongName" SG_ 597 VirtKeyMblDevLocDistAuth "Serial Data 92 Protected : Virtual Key Mobile Device Location Distance Authenticated";
BA_ "SignalLongName" SG_ 597 SD92P_ARC "Serial Data 92 Protected : Alive Rolling Count";
BA_ "SignalType" SG_ 597 VirtKeyMblDevLocZnAuth "ENM";
BA_ "SignalLongName" SG_ 597 VirtKeyMblDevLocZnAuth "Serial Data 92 Protected : Virtual Key Mobile Device Location Zone Authenticated";
BA_ "SignalLongName" SG_ 1331 Sig6873 "Signal6769";
BA_ "SignalLongName" SG_ 864 Sig5760 "Signal6763";
BA_ "SignalLongName" SG_ 864 Sig5758 "Signal6762";
BA_ "SignalLongName" SG_ 864 Sig4929 "Signal6764";
BA_ "SignalLongName" SG_ 864 Sig4932 "Signal6767";
BA_ "SignalType" SG_ 864 Sig4931 "ENM";
BA_ "SignalLongName" SG_ 864 Sig4931 "Signal6766";
BA_ "SignalType" SG_ 864 Sig4930 "ENM";
BA_ "SignalLongName" SG_ 864 Sig4930 "Signal6765";
BA_ "SignalLongName" SG_ 864 Sig4933 "Signal6768";
BA_ "SignalLongName" SG_ 864 Sig5757 "Signal6760";
BA_ "SignalLongName" SG_ 864 Sig5759 "Signal6761";
BA_ "SignalLongName" SG_ 675 StrgWhlInfo_PCSM "Steering Wheel Information Protected Counter Sync Message";
BA_ "SignalLongName" SG_ 84 SWIP_MAC "Steering Wheel Information Protected : MAC";
BA_ "SignalLongName" SG_ 84 SWIP_FCnt "Steering Wheel Information Protected : Freshness Counter";
BA_ "SignalLongName" SG_ 84 SWIP_StrgWhlAngAuth "Steering Wheel Information Protected : Steering Wheel Angle Authenticated";
BA_ "SignalType" SG_ 84 SWIP_StrgWhlAngAuth_DuD "ENM";
BA_ "SignalLongName" SG_ 84 SWIP_StrgWhlAngAuth_DuD "Steering Wheel Information Protected : Steering Wheel Angle Authenticated Don't Use Data";
BA_ "SignalLongName" SG_ 84 SWIP_StrgWhlAngGradAuth "Steering Wheel Information Protected : Steering Wheel Angle Gradient Authenticated";
BA_ "SignalType" SG_ 84 SWIP_StrgWhlAngCalStsAuth "ENM";
BA_ "SignalLongName" SG_ 84 SWIP_StrgWhlAngCalStsAuth "Steering Wheel Information Protected : Steering Wheel Angle Calibration Status Authenticated";
BA_ "SignalType" SG_ 84 SWIP_StrgWhlAngAuth_Inv "ENM";
BA_ "SignalLongName" SG_ 84 SWIP_StrgWhlAngAuth_Inv "Steering Wheel Information Protected : Steering Wheel Angle Authenticated Invalid";
BA_ "SignalLongName" SG_ 84 SWIP_ARC "Steering Wheel Information Protected : Alive Rolling Count";
BA_ "SignalLongName" SG_ 1403 SysPwrMode_PCSM "System Power Mode Protected Counter Sync Message";
BA_ "SignalLongName" SG_ 878 SPMP_MAC "System Power Mode Protected : MAC";
BA_ "SignalLongName" SG_ 878 SPMP_FCnt "System Power Mode Protected : Freshness Counter";
BA_ "SignalLongName" SG_ 878 RIP_RmtVehStrtBkupTmAuth "System Power Mode Protected : Remote Vehicle Start Backup Time Authenticated";
BA_ "SignalType" SG_ 878 RIP_PreRelAllwdAuth "ENM";
BA_ "SignalLongName" SG_ 878 RIP_PreRelAllwdAuth "System Power Mode Protected : Pre-Release Allowed Authenticated";
BA_ "SignalType" SG_ 878 RIP_ElecStrgColUnlckAllwdAuth "ENM";
BA_ "SignalLongName" SG_ 878 RIP_ElecStrgColUnlckAllwdAuth "System Power Mode Protected : Electric Steering Column Unlock Allowed Authenticated";
BA_ "SignalType" SG_ 878 BGI1P_RmtVehStrtReqAuth "ENM";
BA_ "SignalLongName" SG_ 878 BGI1P_RmtVehStrtReqAuth "System Power Mode Protected : Remote Vehicle Start Request Authenticated";
BA_ "SignalType" SG_ 878 BGI1P_RmtStrtStsAuth "ENM";
BA_ "SignalLongName" SG_ 878 BGI1P_RmtStrtStsAuth "System Power Mode Protected : Remote Vehicle Start Status Authenticated";
BA_ "SignalType" SG_ 878 SPMP_PriRunCrnkCmdActvAuth "ENM";
BA_ "SignalLongName" SG_ 878 SPMP_PriRunCrnkCmdActvAuth "System Power Mode Protected : Primary Run Crank Command Active Authenticated";
BA_ "SignalLongName" SG_ 878 SPMP_PV "System Power Mode Protected : Protection Value";
BA_ "SignalType" SG_ 878 RIP_StrtStopIgnSwPrssdAuth "ENM";
BA_ "SignalLongName" SG_ 878 RIP_StrtStopIgnSwPrssdAuth "System Power Mode Protected : Start/Stop Ignition Switch Pressed Authenticated";
BA_ "SignalType" SG_ 878 RIP_StrtStopIgnSwPrssdAuth_Inv "ENM";
BA_ "SignalLongName" SG_ 878 RIP_StrtStopIgnSwPrssdAuth_Inv "System Power Mode Protected : Start/Stop Ignition Switch Pressed Authenticated Invalid";
BA_ "SignalLongName" SG_ 878 SPMP_ARC "System Power Mode Protected : Alive Rolling Count";
BA_ "SignalType" SG_ 878 SPMP_SysPwrModeAuth_Inv "ENM";
BA_ "SignalLongName" SG_ 878 SPMP_SysPwrModeAuth_Inv "System Power Mode Protected : System Power Mode Authenticated Invalid";
BA_ "SignalType" SG_ 878 SPMP_SysPwrModeAuth "ENM";
BA_ "SignalLongName" SG_ 878 SPMP_SysPwrModeAuth "System Power Mode Protected : System Power Mode Authenticated";
BA_ "SignalType" SG_ 878 SPMP_PriRunCrnkCmdActvAuth_Inv "ENM";
BA_ "SignalLongName" SG_ 878 SPMP_PriRunCrnkCmdActvAuth_Inv "System Power Mode Protected : Primary Run Crank Command Active Authenticated Invalid";
BA_ "SignalLongName" SG_ 878 SPMP_Filler "System Power Mode Protected : Filler";
BA_ "SignalType" SG_ 2147745824 Sig7516 "ENM";
BA_ "SignalLongName" SG_ 2147745824 Sig7516 "Signal7550";
BA_ "SignalType" SG_ 2147745825 Sig7517 "ENM";
BA_ "SignalLongName" SG_ 2147745825 Sig7517 "Signal7551";
BA_ "SignalLongName" SG_ 1358 TlmGPSDateSrc_PCSM "Telematics GPS Date Source Protected Counter Sync Message";
BA_ "SignalLongName" SG_ 1299 TGPSDSP_MAC "Telematics GPS Date Source Protected : MAC";
BA_ "SignalLongName" SG_ 1299 TGPSDSP_FCnt "Telematics GPS Date Source Protected : Freshness Counter";
BA_ "SignalType" SG_ 1299 TGPSDSP_UTCMonthAuth "ENM";
BA_ "SignalLongName" SG_ 1299 TGPSDSP_UTCMonthAuth "Telematics GPS Date Source Protected : UTC Month Authenticated";
BA_ "SignalType" SG_ 1299 TGPSDSP_UTCDyAuth_Inv "ENM";
BA_ "SignalLongName" SG_ 1299 TGPSDSP_UTCDyAuth_Inv "Telematics GPS Date Source Protected : UTC Day Authenticated Invalid";
BA_ "SignalLongName" SG_ 1299 TGPSDSP_UTCDyAuth "Telematics GPS Date Source Protected : UTC Day Authenticated";
BA_ "SignalLongName" SG_ 1299 TGPSDSP_UTCYrAuth "Telematics GPS Date Source Protected : UTC Year Authenticated";
BA_ "SignalType" SG_ 1299 TGPSDSP_UTCMonthAuth_Inv "ENM";
BA_ "SignalLongName" SG_ 1299 TGPSDSP_UTCMonthAuth_Inv "Telematics GPS Date Source Protected : UTC Month Authenticated Invalid";
BA_ "SignalType" SG_ 1299 TGPSDSP_DateSrcAuth "ENM";
BA_ "SignalLongName" SG_ 1299 TGPSDSP_DateSrcAuth "Telematics GPS Date Source Protected : Date Source Authenticated";
BA_ "SignalLongName" SG_ 1299 TGPSDSP_ARC "Telematics GPS Date Source Protected : Alive Rolling Count";
BA_ "SignalType" SG_ 1299 TGPSDSP_UTCYrAuth_Inv "ENM";
BA_ "SignalLongName" SG_ 1299 TGPSDSP_UTCYrAuth_Inv "Telematics GPS Date Source Protected : UTC Year Authenticated Invalid";
BA_ "SignalType" SG_ 1299 TGPSDSP_DateSrcAuth_Inv "ENM";
BA_ "SignalLongName" SG_ 1299 TGPSDSP_DateSrcAuth_Inv "Telematics GPS Date Source Protected : Date Source Authenticated Invalid";
BA_ "SignalLongName" SG_ 1357 TlmGPSTmSrc_PCSM "Telematics GPS Time Source Protected Counter Sync Message";
BA_ "SignalLongName" SG_ 865 TGPSTSP_MAC "Telematics GPS Time Source Protected : MAC";
BA_ "SignalLongName" SG_ 865 TGPSTSP_FCnt "Telematics GPS Time Source Protected : Freshness Counter";
BA_ "SignalLongName" SG_ 865 TGPSTSP_UTCHrsAuth "Telematics GPS Time Source Protected : UTC Hours Authenticated";
BA_ "SignalType" SG_ 865 TGPSTSP_TmSrcAuth_Inv "ENM";
BA_ "SignalLongName" SG_ 865 TGPSTSP_TmSrcAuth_Inv "Telematics GPS Time Source Protected : Time Source Authenticated Invalid";
BA_ "SignalType" SG_ 865 TGPSTSP_TmSrcAuth "ENM";
BA_ "SignalLongName" SG_ 865 TGPSTSP_TmSrcAuth "Telematics GPS Time Source Protected : Time Source Authenticated";
BA_ "SignalLongName" SG_ 865 TGPSTSP_UTCMinsAuth "Telematics GPS Time Source Protected : UTC Minutes Authenticated";
BA_ "SignalType" SG_ 865 TGPSTSP_UTCHrsAuth_Inv "ENM";
BA_ "SignalLongName" SG_ 865 TGPSTSP_UTCHrsAuth_Inv "Telematics GPS Time Source Protected : UTC Hours Authenticated Invalid";
BA_ "SignalType" SG_ 865 TGPSTSP_UTCSecsAuth_Inv "ENM";
BA_ "SignalLongName" SG_ 865 TGPSTSP_UTCSecsAuth_Inv "Telematics GPS Time Source Protected : UTC Seconds Authenticated Invalid";
BA_ "SignalLongName" SG_ 865 TGPSTSP_UTCSecsAuth "Telematics GPS Time Source Protected : UTC Seconds Authenticated";
BA_ "SignalType" SG_ 865 TGPSTSP_UTCMinsAuth_Inv "ENM";
BA_ "SignalLongName" SG_ 865 TGPSTSP_UTCMinsAuth_Inv "Telematics GPS Time Source Protected : UTC Minutes Authenticated Invalid";
BA_ "SignalLongName" SG_ 865 TGPSTSP_ARC "Telematics GPS Time Source Protected : Alive Rolling Count";
BA_ "SignalLongName" SG_ 1903 Sig7904 "Signal7867";
BA_ "SignalLongName" SG_ 1904 Sig7905 "Signal7868";
BA_ "SignalLongName" SG_ 1901 Sig7906 "Signal7869";
BA_ "SignalLongName" SG_ 1902 Sig7907 "Signal7870";
BA_ "SignalLongName" SG_ 1905 Sig7908 "Signal7871";
BA_ "SignalLongName" SG_ 1371 Sig7631 "Signal7743";
BA_ "SignalLongName" SG_ 867 Sig7543 "Signal7741";
BA_ "SignalLongName" SG_ 867 Sig7541 "Signal7740";
BA_ "SignalLongName" SG_ 867 Sig7620 "Signal7742";
BA_ "SignalLongName" SG_ 867 Sig7539 "Signal7737";
BA_ "SignalLongName" SG_ 867 Sig7540 "Signal7738";
BA_ "SignalLongName" SG_ 867 Sig7542 "Signal7739";
BA_ "SignalLongName" SG_ 674 TrnsEstGr_PCSM "Transmission Estimated Gear Protected Counter Sync Message";
BA_ "SignalLongName" SG_ 50 TEGP_MAC "Transmission Estimated Gear Protected : MAC";
BA_ "SignalLongName" SG_ 50 TEGP_FCnt "Transmission Estimated Gear Protected : Freshness Counter";
BA_ "SignalType" SG_ 50 TEGP_TrnsEstGrAuth "ENM";
BA_ "SignalLongName" SG_ 50 TEGP_TrnsEstGrAuth "Transmission Estimated Gear Protected : Transmission Estimated Gear Authenticated";
BA_ "SignalType" SG_ 50 TEGP_TrnsEngdStAuth_Inv "ENM";
BA_ "SignalLongName" SG_ 50 TEGP_TrnsEngdStAuth_Inv "Transmission Estimated Gear Protected : Transmission Engaged State Authenticated Invalid";
BA_ "SignalType" SG_ 50 TEGP_TrnsEngdStAuth "ENM";
BA_ "SignalLongName" SG_ 50 TEGP_TrnsEngdStAuth "Transmission Estimated Gear Protected : Transmission Engaged State Authenticated";
BA_ "SignalType" SG_ 50 TEGP_TransCmndGrAuth "ENM";
BA_ "SignalLongName" SG_ 50 TEGP_TransCmndGrAuth "Transmission Estimated Gear Protected : Transmission Commanded Gear Authenticated";
BA_ "SignalType" SG_ 50 TEGP_TrnsShftLvrPstnAuth "ENM";
BA_ "SignalLongName" SG_ 50 TEGP_TrnsShftLvrPstnAuth "Transmission Estimated Gear Protected : Transmission Shift Lever Position Authenticated";
BA_ "SignalType" SG_ 50 TEGP_TrnsEstGrAuth_Inv "ENM";
BA_ "SignalLongName" SG_ 50 TEGP_TrnsEstGrAuth_Inv "Transmission Estimated Gear Protected : Transmission Estimated Gear Authenticated Invalid";
BA_ "SignalLongName" SG_ 50 TEGP_Filler "Transmission Estimated Gear Protected : Filler";
BA_ "SignalLongName" SG_ 50 TEGP_ARC "Transmission Estimated Gear Protected : Alive Rolling Count";
BA_ "SignalType" SG_ 50 TEGP_TrnsShftLvrPstnAuth_Inv "ENM";
BA_ "SignalLongName" SG_ 50 TEGP_TrnsShftLvrPstnAuth_Inv "Transmission Estimated Gear Protected : Transmission Shift Lever Position Authenticated Invalid";
BA_ "SignalLongName" SG_ 892 Sig7780 "Signal7736";
BA_ "SignalLongName" SG_ 45 Sig7536 "Signal7733";
BA_ "SignalLongName" SG_ 45 Sig7534 "Signal7732";
BA_ "SignalLongName" SG_ 45 Sig7537 "Signal7734";
BA_ "SignalLongName" SG_ 45 Sig7535 "Signal7731";
BA_ "SignalLongName" SG_ 45 Sig7533 "Signal7730";
BA_ "SignalType" SG_ 45 Sig7538 "ENM";
BA_ "SignalLongName" SG_ 45 Sig7538 "Signal7735";
BA_ "SignalLongName" SG_ 891 TwinClchInfo_PCSM "Twin Clutch Information Protected Counter Sync Message";
BA_ "SignalLongName" SG_ 527 TCIP_MAC "Twin Clutch Information Protected : MAC";
BA_ "SignalLongName" SG_ 527 TCIP_FCnt "Twin Clutch Information Protected : Freshness Counter";
BA_ "SignalLongName" SG_ 527 TCIP_AxlEstdTrqLRAuth "Twin Clutch Information Protected : Axle Estimated Torque Left Rear Authenticated";
BA_ "SignalLongName" SG_ 527 TCIP_AxlEstdTrqRRAuth "Twin Clutch Information Protected : Axle Estimated Torque Right Rear Authenticated";
BA_ "SignalType" SG_ 527 TCIP_AxlEstdTrqLRAuth_Inv "ENM";
BA_ "SignalLongName" SG_ 527 TCIP_AxlEstdTrqLRAuth_Inv "Twin Clutch Information Protected : Axle Estimated Torque Left Rear Authenticated Invalid";
BA_ "SignalType" SG_ 527 TCIP_AxlStsRrAuth "ENM";
BA_ "SignalLongName" SG_ 527 TCIP_AxlStsRrAuth "Twin Clutch Information Protected : Axle Status Rear Authenticated";
BA_ "SignalType" SG_ 527 TCIP_AxlEstdTrqRRAuth_Inv "ENM";
BA_ "SignalLongName" SG_ 527 TCIP_AxlEstdTrqRRAuth_Inv "Twin Clutch Information Protected : Axle Estimated Torque Right Rear Authenticated Invalid";
BA_ "SignalLongName" SG_ 527 TCIP_Filler "Twin Clutch Information Protected : Filler";
BA_ "SignalLongName" SG_ 527 TCIP_ARC "Twin Clutch Information Protected : Alive Rolling Count";
BA_ "SignalType" SG_ 2147745826 Sig7850 "ENM";
BA_ "SignalLongName" SG_ 2147745826 Sig7850 "Signal7840";
BA_ "SignalType" SG_ 2147745827 Sig7852 "ENM";
BA_ "SignalLongName" SG_ 2147745827 Sig7852 "Signal7862";
BA_ "SignalType" SG_ 2147745806 VICM_CAN2_ClscCANHrtBtActv "ENM";
BA_ "SignalLongName" SG_ 2147745806 VICM_CAN2_ClscCANHrtBtActv "VICM CAN 2 Classic CAN Heart Beat Active";
BA_ "SignalLongName" SG_ 1257 VehIdNmDig10_17 "Vehicle Identification Number Digits 10-17";
BA_ "SignalLongName" SG_ 1809 VehIdNmDig2_9 "Vehicle Identification Number Digits 2-9";
BA_ "SignalLongName" SG_ 890 VehIntgrtnCtlModInfo1_PCSM "Vehicle Integration Control Module Information 1 Protected Counter Sync Message";
BA_ "SignalLongName" SG_ 621 VICMI1P_MAC "Vehicle Integration Control Module Information 1 Protected : MAC";
BA_ "SignalLongName" SG_ 621 VICMI1P_FCnt "Vehicle Integration Control Module Information 1 Protected : Freshness Counter";
BA_ "SignalType" SG_ 621 VICMI1P_AutoDrvShfSysStsPriAuth "ENM";
BA_ "SignalLongName" SG_ 621 VICMI1P_AutoDrvShfSysStsPriAuth "Vehicle Integration Control Module Information 1 Protected : Autonomous Driving Shift System Status Primary Authenticated";
BA_ "SignalLongName" SG_ 621 VICMI1P_FillerExtnd "Vehicle Integration Control Module Information 1 Protected : Filler Extended";
BA_ "SignalType" SG_ 621 VICMI1P_ADShfSysHlthStsPriAuth "ENM";
BA_ "SignalLongName" SG_ 621 VICMI1P_ADShfSysHlthStsPriAuth "Vehicle Integration Control Module Information 1 Protected : Autonomous Driving Shift System Health Status Primary Authenticated";
BA_ "SignalLongName" SG_ 621 VICMI1P_Filler "Vehicle Integration Control Module Information 1 Protected : Filler";
BA_ "SignalLongName" SG_ 621 VICMI1P_ARC "Vehicle Integration Control Module Information 1 Protected : Alive Rolling Count";
BA_ "SignalType" SG_ 621 VICMI1P_AuxPwrModStsAuth "ENM";
BA_ "SignalLongName" SG_ 621 VICMI1P_AuxPwrModStsAuth "Vehicle Integration Control Module Information 1 Protected : Auxiliary Power Module Status Authenticated";
BA_ "SignalLongName" SG_ 1370 VehOdoDispVal_PCSM "Vehicle Odometer Display Value Protected Counter Sync Message";
BA_ "SignalLongName" SG_ 1298 VODVP_MAC "Vehicle Odometer Display Value Protected : MAC";
BA_ "SignalLongName" SG_ 1298 VODVP_FCnt "Vehicle Odometer Display Value Protected : Freshness Counter";
BA_ "SignalLongName" SG_ 1298 VODVP_VehOdoDispValAuth "Vehicle Odometer Display Value Protected : Vehicle Odometer Display Value Authenticated";
BA_ "SignalLongName" SG_ 1298 VODVP_Filler "Vehicle Odometer Display Value Protected : Filler";
BA_ "SignalType" SG_ 1298 UpftrRmtVehStrtReqd "ENM";
BA_ "SignalLongName" SG_ 1298 UpftrRmtVehStrtReqd "Vehicle Odometer Display Value Protected : Upfitter Remote Vehicle Start Requested";
BA_ "SignalType" SG_ 1298 UpftrSnwPlwLoBmDsblReqd "ENM";
BA_ "SignalLongName" SG_ 1298 UpftrSnwPlwLoBmDsblReqd "Vehicle Odometer Display Value Protected : Upfitter Snow Plow Low Beam Disable Requested";
BA_ "SignalType" SG_ 1298 VODVP_VehOdoDispValAuth_Inv "ENM";
BA_ "SignalLongName" SG_ 1298 VODVP_VehOdoDispValAuth_Inv "Vehicle Odometer Display Value Protected : Vehicle Odometer Display Value Authenticated Invalid";
BA_ "SignalLongName" SG_ 1402 VehSpdAvgDrvn_PCSM "Vehicle Speed Average Driven Protected Counter Sync Message";
BA_ "SignalLongName" SG_ 614 VSADP_MAC "Vehicle Speed Average Driven Protected : MAC";
BA_ "SignalLongName" SG_ 614 VSADP_FCnt "Vehicle Speed Average Driven Protected : Freshness Counter";
BA_ "SignalLongName" SG_ 614 VSADP_VehSpdAvgDrvnAuth "Vehicle Speed Average Driven Protected : Vehicle Speed Average Driven Authenticated";
BA_ "SignalType" SG_ 614 VSADP_RdcdPwrIndOnAuth "ENM";
BA_ "SignalLongName" SG_ 614 VSADP_RdcdPwrIndOnAuth "Vehicle Speed Average Driven Protected : Reduced Power Indication On Authenticated";
BA_ "SignalType" SG_ 614 VSADP_FuelModeStsAuth "ENM";
BA_ "SignalLongName" SG_ 614 VSADP_FuelModeStsAuth "Vehicle Speed Average Driven Protected : Fuel Mode Status Authenticated";
BA_ "SignalType" SG_ 614 EngEmsRltMlfIndRq "ENM";
BA_ "SignalLongName" SG_ 614 EngEmsRltMlfIndRq "Vehicle Speed Average Driven Protected : Engine Emissions Related Malfunction Indication Request";
BA_ "SignalLongName" SG_ 614 VSADP_ARC "Vehicle Speed Average Driven Protected : Alive Rolling Count";
BA_ "SignalType" SG_ 614 VSADP_VehSpdAvgDrvnSrcAuth "ENM";
BA_ "SignalLongName" SG_ 614 VSADP_VehSpdAvgDrvnSrcAuth "Vehicle Speed Average Driven Protected : Vehicle Speed Average Driven Source Authenticated";
BA_ "SignalType" SG_ 614 VSADP_VehSpdAvgDrvnAuth_Inv "ENM";
BA_ "SignalLongName" SG_ 614 VSADP_VehSpdAvgDrvnAuth_Inv "Vehicle Speed Average Driven Protected : Vehicle Speed Average Driven Authenticated Invalid";
BA_ "SignalLongName" SG_ 614 VSADP_Filler "Vehicle Speed Average Driven Protected : Filler";
BA_ "SignalLongName" SG_ 1369 VehSpdAvgNDrvn_PCSM "Vehicle Speed Average Non Driven Protected Counter Sync Message";
BA_ "SignalLongName" SG_ 610 VSANDP_MAC "Vehicle Speed Average Non Driven Protected : MAC";
BA_ "SignalLongName" SG_ 610 VSANDP_Fcnt "Vehicle Speed Average Non Driven Protected : Freshness Counter";
BA_ "SignalLongName" SG_ 610 VSANDP_VehSpdAvgNDrvnAuth "Vehicle Speed Average Non Driven Protected : Vehicle Speed Average NonDriven Authenticated";
BA_ "SignalType" SG_ 610 VSANDP_VehSpdAvgNDrvnAuth_Inv "ENM";
BA_ "SignalLongName" SG_ 610 VSANDP_VehSpdAvgNDrvnAuth_Inv "Vehicle Speed Average Non Driven Protected : Vehicle Speed Average Non Driven Authenticated Invalid";
BA_ "SignalLongName" SG_ 610 VSANDP_Filler "Vehicle Speed Average Non Driven Protected : Filler";
BA_ "SignalLongName" SG_ 610 VSANDP_ARC "Vehicle Speed Average Non Driven Protected : Alive Rolling Count";
BA_ "SignalLongName" SG_ 1395 Sig7939 "Signal7923";
BA_ "SignalLongName" SG_ 1303 Sig7897 "Signal7922";
BA_ "SignalLongName" SG_ 1303 Sig7893 "Signal7919";
BA_ "SignalLongName" SG_ 1303 Sig7894 "Signal7918";
BA_ "SignalLongName" SG_ 1303 Sig7892 "Signal7917";
BA_ "SignalType" SG_ 1303 Sig7896 "ENM";
BA_ "SignalLongName" SG_ 1303 Sig7896 "Signal7921";
BA_ "SignalType" SG_ 1303 Sig7895 "ENM";
BA_ "SignalLongName" SG_ 1303 Sig7895 "Signal7920";
BA_ "SignalLongName" SG_ 1394 WhlDist_PCSM "Wheel Distance Protected Counter Sync Message";
BA_ "SignalLongName" SG_ 1302 WDP_MAC "Wheel Distance Protected : MAC";
BA_ "SignalLongName" SG_ 1302 WDP_FCnt "Wheel Distance Protected : Freshness Counter";
BA_ "SignalLongName" SG_ 1302 WDP_WhlDistPerRevFrtAuth "Wheel Distance Protected : Wheel Distance Per Revolution Front Authenticated";
BA_ "SignalLongName" SG_ 1302 WDP_WhlDistPerRevRrAuth "Wheel Distance Protected : Wheel Distance Per Revolution Rear Authenticated";
BA_ "SignalLongName" SG_ 1302 WDP_Filler "Wheel Distance Protected : Filler";
BA_ "SignalLongName" SG_ 1302 WDP_ARC "Wheel Distance Protected : Alive Rolling Count";
BA_ "SignalLongName" SG_ 889 XferCaseGenInfo_PCSM "Transfer Case General Information Protected Counter Sync Message";
BA_ "SignalLongName" SG_ 620 XCGIP_MAC "Transfer Case General Information Protected : MAC";
BA_ "SignalLongName" SG_ 620 XCGIP_FCnt "Transfer Case General Information Protected : Freshness Counter";
BA_ "SignalLongName" SG_ 620 TCGIP_Filler "Transfer Case General Information Protected : Filler";
BA_ "SignalLongName" SG_ 620 XCGIP_ARC "Transfer Case General Information Protected : Alive Rolling Count";
BA_ "SignalType" SG_ 620 XCGIP_SecAxlPrkBrkAppReqdAuth "ENM";
BA_ "SignalLongName" SG_ 620 XCGIP_SecAxlPrkBrkAppReqdAuth "Transfer Case General Information Protected : Secondary Axle Park Brake Apply Requested Authenticated";
VAL_ 58 DSIDP_DrvrStrgIntfrDtdAuth_Inv 0 "FALSE" 1 "TRUE" ;
VAL_ 58 DSIDP_DrvrStrgIntfrDtdAuth 0 "FALSE" 1 "TRUE" ;
VAL_ 58 DASTP_StrTrqAuth_Inv 0 "FALSE" 1 "TRUE" ;
VAL_ 58 EPSOP_ElecPwStrgTqOvlyStsAuth 0 "Unknown" 1 "Temporarily Inhibited" 2 "Inactive" 3 "Active" 4 "Temporarily Limited" 5 "Failed" ;
VAL_ 58 EPSOP_EPSOvrlyTrqDlvdAuth_Inv 0 "FALSE" 1 "TRUE" ;
VAL_ 58 SSASI2P_LKAStrgRqCommStsAuth 0 "Unknown" 1 "Normal Active" 2 "Normal Inactive" 3 "Failed Communication" ;
VAL_ 58 SSASI2P_ArbdASStrgRqCommStsAuth 0 "Unknown" 1 "Normal Communication Request Active" 2 "Normal Communication Request Active Fault Pending" 3 "Normal Communication Request Inactive" 4 "Normal Communication Request Inactive Fault Pending" 5 "Failed Communication" ;
VAL_ 58 SSASI2P_AE44StrgRqCommStsAuth 0 "Unknown" 1 "Normal Active" 2 "Normal Inactive" 3 "Failed Communication" ;
VAL_ 58 EPSTTDP_TotTorqDlvdAuth_Inv 0 "FALSE" 1 "TRUE" ;
VAL_ 58 SSASIP_StrgPerfActlModeAuth 0 "No Action" 1 "Normal" 2 "Sport" 3 "Comfort" 4 "Track" 5 "Tow_Haul" 6 "Offroad" 7 "Terrain" ;
VAL_ 58 SSASIP_StrgAsstThrmlInhbdAuth 0 "FALSE" 1 "TRUE" ;
VAL_ 58 SSASIP_StrgAsstStsAuth 0 "Normal" 1 "Reduced" 2 "Unavailable" ;
VAL_ 58 SWHOP_ArbdStrgFtrReqActvAuth 0 "None" 1 "ESC" 2 "APA" 3 "LKA" 4 "LCC" 5 "TJA" 6 "HOLF" 7 "LCP" 8 "SAA" 9 "CAS" 10 "LCOD" ;
VAL_ 58 SSASIP_StrgWhlTrqIntegStsAuth 0 "Unknown" 1 "Redundant ASIL D" 2 "Non Redundant ASIL D" 3 "Failed" ;
VAL_ 58 SSASIP_StrgWhlAngIntegStsAuth 0 "Unknown" 1 "Redundant ASIL D" 2 "Non Redundant ASIL D" 3 "Failed" ;
VAL_ 58 SWHOP_StrgWhlHndsOffDtnStatAuth 0 "Hands On" 1 "Hands Off" 2 "Unknown" ;
VAL_ 58 SWHOP_StrgWhlHndsOffDtnModeAuth 0 "Disabled" 1 "Enabled" 2 "Failed" 3 "Unknown" ;
VAL_ 58 SWHOP_StrgWhlHndsOffDtnCnfdLvlAu 0 "Low" 1 "High" 2 "Unknown" ;
VAL_ 90 Sig0319 0 "Unknown" 1 "Temporarily Inhibited" 2 "Inactive" 3 "Active" 4 "Temporarily Limited" 5 "Failed" 6 "Backup Command" 7 "Hold Last Value" ;
VAL_ 90 Sig0313 0 "Unknown" 1 "Normal Communication Request Active" 2 "Normal Communication Request Active Fault Pending" 3 "Normal Communication Request Inactive" 4 "Normal Communication Request Inctive Fault Pending" 5 "Failed Communication" ;
VAL_ 90 Sig0325 0 "Normal" 1 "Reduced" 2 "Failed" 3 "Off" ;
VAL_ 90 Sig0322 0 "Normal" 1 "Reduced" 2 "Failed" 3 "Off" ;
VAL_ 90 Sig6953 0 "Normal Operation" 1 "Degraded 1" 2 "Degraded 2" 3 "Degraded 3" 4 "Degraded 4" 5 "Degraded 5" ;
VAL_ 90 Sig0318 0 "FALSE" 1 "TRUE" ;
VAL_ 90 Sig0316 0 "FALSE" 1 "TRUE" ;
VAL_ 90 Sig0314 0 "FALSE" 1 "TRUE" ;
VAL_ 90 Sig6956 0 "Unknown" 1 "Internal Communication Available" 2 "Internal Communication Unavailable" ;
VAL_ 90 Sig0328 0 "Unknown" 1 "Redundant ASIL D" 2 "Non Redundant ASIL D" 3 "Failed" ;
VAL_ 90 Sig2545 0 "FALSE" 1 "TRUE" ;
VAL_ 90 Sig0326 0 "FALSE" 1 "TRUE" ;
VAL_ 90 Sig0324 0 "FALSE" 1 "TRUE" ;
VAL_ 90 Sig0321 0 "FALSE" 1 "TRUE" ;
VAL_ 876 BVSCP_BdyCtlTopSpdLimReqTypAuth 0 "Inactive" 1 "Faulted" 2 "Safety_woBrake" 3 "Safety_wBrake" 4 "OBD" 5 "nonOBD" 6 "Legislated" ;
VAL_ 876 BGI4P_AutoShtdnRstAuth 0 "FALSE" 1 "TRUE" ;
VAL_ 876 BGI4P_AutoShtdnAllwdAuth 0 "FALSE" 1 "TRUE" ;
VAL_ 876 BGI4P_AirDflctOffCycCrTkStAuth 0 "Inactive" 1 "NotPresent" 2 "PartCreditTmrMode" 3 "FullCreditTmrMode" ;
VAL_ 876 BASHPLP_BrkSnsrHmPstnLrndAuth 0 "FALSE" 1 "TRUE" ;
VAL_ 876 DSIP_E44MSw3StkAuth 0 "FALSE" 1 "TRUE" ;
VAL_ 876 DSIP_E44MSw2StkAuth 0 "FALSE" 1 "TRUE" ;
VAL_ 876 DSIP_E44MSw1StkAuth 0 "FALSE" 1 "TRUE" ;
VAL_ 876 BdyCtlTopSpdLimSrcAuth 0 "None" 1 "Teen" 2 "Valet" 3 "HoodOpen" 4 "Reserved" 5 "Reserved" 6 "Reserved" 7 "Reserved" ;
VAL_ 876 BdyCtlTopSpdLimIndOnAuth 0 "FALSE" 1 "TRUE" ;
VAL_ 876 BdyCtlAccelLimIndOnAuth 0 "FALSE" 1 "TRUE" ;
VAL_ 876 RIP_FrtCmptRelEnblReqAuth 0 "Not Enabled" 1 "Entrapment Release To Ajar" 2 "Normal Release To Open" 3 "Entrapment Release To Open" ;
VAL_ 876 DSIP_E44MSwStsAuth 0 "No Active Switches" 1 "Switch 1 Active" 2 "Switch 2 Active" 3 "Switch 3 Active" 4 "Switch 4 Active" 5 "2WD High Switch Long Press" 6 "AWD Active Switch Long Press" 7 "Critical Analog Fault" ;
VAL_ 876 DSIP_E44MSwDrvrModeSwStkAuth 0 "FALSE" 1 "TRUE" ;
VAL_ 876 DSIP_E44MSw4StkAuth 0 "FALSE" 1 "TRUE" ;
VAL_ 876 LoVltg12VBatMntModeReqd 0 "FALSE" 1 "TRUE" ;
VAL_ 623 LSCMBABP_ReqActvAuth 0 "FALSE" 1 "TRUE" ;
VAL_ 623 RLDWCTOP_TrqOvrlyActAuth_Inv 0 "FALSE" 1 "TRUE" ;
VAL_ 623 RLDWCTOP_TrqOvrlyActAuth_DuD 0 "FALSE" 1 "TRUE" ;
VAL_ 623 RLDWCTOP_TrqOvrlyActAuth 0 "ACTIVE" 1 "INACTIVE" ;
VAL_ 623 LSCMBABP_TypAuth 0 "None" 1 "Brake to Commanded Decel" 2 "Hold" ;
VAL_ 623 RLDWCTOP_TrqOvrlyValAuth_DuD 0 "FALSE" 1 "TRUE" ;
VAL_ 623 RLDWCTOP_TrqOvrlyValAuth_Inv 0 "FALSE" 1 "TRUE" ;
VAL_ 622 HMIGI2P_LnFllwgInterFltDtdAuth 0 "FALSE" 1 "TRUE" ;
VAL_ 622 HMIGI2P_IPCFlrIndOnAuth 0 "FALSE" 1 "TRUE" ;
VAL_ 622 HMIGI1P_TrlrBrkDispActvAuth_DuD 0 "FALSE" 1 "TRUE" ;
VAL_ 622 HMIGI1P_TrlrBrkDispActvAuth 0 "FALSE" 1 "TRUE" ;
VAL_ 622 HMIGI1P_EnvModPrsntRspdr4Auth 0 "FALSE" 1 "TRUE" ;
VAL_ 875 CTGI1P_CnvtTpSpLimRqTypAuth 0 "Inactive" 1 "Faulted" 2 "Safety_woBrake" 3 "Safety_wBrake" 4 "OBD" 5 "nonOBD" 6 "Legislated" ;
VAL_ 875 CnvtTopModSpdLimIndOnAuth 0 "FALSE" 1 "TRUE" ;
VAL_ 53 SSID1P_LatAccelAuth_Inv 0 "FALSE" 1 "TRUE" ;
VAL_ 53 SSID1P_LngAccelAuth_Inv 0 "FALSE" 1 "TRUE" ;
VAL_ 53 SSID2P_PtchRateAuth_Inv 0 "FALSE" 1 "TRUE" ;
VAL_ 53 SSID2P_VertAccelAuth_Inv 0 "FALSE" 1 "TRUE" ;
VAL_ 53 SSID3P_RollRateAuth_Inv 0 "FALSE" 1 "TRUE" ;
VAL_ 53 SSID3P_YawRateAuth_Inv 0 "FALSE" 1 "TRUE" ;
VAL_ 53 SSID4P_LFAuth_Inv 0 "FALSE" 1 "TRUE" ;
VAL_ 53 SSID4P_RFAuth_Inv 0 "FALSE" 1 "TRUE" ;
VAL_ 53 SSID5P_LRAuth_Inv 0 "FALSE" 1 "TRUE" ;
VAL_ 53 SSID5P_RRAuth_Inv 0 "FALSE" 1 "TRUE" ;
VAL_ 57 LatAccelSnsrCorrStsAuth 0 "Unknown" 1 "NA" 2 "Correlated" 3 "Uncorellated" ;
VAL_ 57 LatAccelAuth_Inv 0 "FALSE" 1 "TRUE" ;
VAL_ 57 LongAccelAuth_Inv 0 "FALSE" 1 "TRUE" ;
VAL_ 57 VehAccelCalAuth 0 "FALSE" 1 "TRUE" ;
VAL_ 57 LongAccelSnsrCorrStsAuth 0 "Unknown" 1 "NA" 2 "Correlated" 3 "Uncorellated" ;
VAL_ 57 YRP_RollRateAuth_Inv 0 "FALSE" 1 "TRUE" ;
VAL_ 57 YRP_RollRateAuth_DuD 0 "FALSE" 1 "TRUE" ;
VAL_ 57 YawRateAuth_DuD 0 "FALSE" 1 "TRUE" ;
VAL_ 57 YawRateCorrAuth 0 "Unknown" 1 "NA" 2 "Correlated" 3 "Uncorellated" ;
VAL_ 57 YawRateAuth_Inv 0 "FALSE" 1 "TRUE" ;
VAL_ 57 VehAccelAuth_DuD 0 "FALSE" 1 "TRUE" ;
VAL_ 46 Sig7523 0 "No Request" 1 "Maximum Limit" 2 "Minimum Limit" ;
VAL_ 46 Sig7526 0 "No_Request" 1 "Maximum_Limit" 2 "Minimum_Limit" ;
VAL_ 46 Sig7525 0 "Inactive" 1 "PleasabilityLimited" 2 "MaximumRange" 3 "AutomaticActuatorSelection" ;
VAL_ 46 Sig7531 0 "No Intervention" 1 "Engine Speed Max Limit" 2 "Engine Speed Min Limit" 3 "Engine Speed Max and Min Limit" ;
VAL_ 46 Sig7530 0 "No_Suggestion" 1 "Transient_Optimized" 2 "Stability_Optimized_Condition_1" 3 "Stability_Optimized_Condition_2" ;
VAL_ 46 TGIP_TransGrRatStatAuth 0 "Inactive" 1 "Normal" 2 "Theoretical" 3 "Torque Phase Ratio Active" 4 "Alternate Sensors in Use" 5 "Invalid" ;
VAL_ 46 TGIP_TransGrRatAuth_Inv 0 "FALSE" 1 "TRUE" ;
VAL_ 46 Sig7548 0 "Single Edge Sensor" 1 "Rising Transition" 2 "Falling Transition" 3 "Undefined" ;
VAL_ 46 Sig7551 0 "FALSE" 1 "TRUE" ;
VAL_ 46 Sig7550 0 "FALSE" 1 "TRUE" ;
VAL_ 46 TORSP_TransOutRotnDirAuth 0 "Unknown" 1 "Forward" 2 "Reverse" 3 "Undefined" ;
VAL_ 46 Sig7574 0 "FALSE" 1 "TRUE" ;
VAL_ 46 Sig7573 0 "Crank Not Permitted" 1 "Crank Permitted" ;
VAL_ 46 Sig7572 0 "FALSE" 1 "TRUE" ;
VAL_ 46 Sig7571 0 "Crank Not Permitted" 1 "Crank Permitted" ;
VAL_ 46 Sig7576 0 "FALSE" 1 "TRUE" ;
VAL_ 46 Sig7634 0 "FALSE" 1 "TRUE" ;
VAL_ 46 Sig7633 0 "FALSE" 1 "TRUE" ;
VAL_ 46 Sig7581 0 "No Intervention" 1 "Engine Speed Max Limit" 2 "Engine Speed Min Limit" 3 "Engine Speed Max and Min Limit" ;
VAL_ 46 Sig7580 0 "No Suggestion" 1 "Transient Optimized" 2 "Stability Optimized Condition 1" 3 "Stability Optimized Condition 2" ;
VAL_ 46 Sig7623 0 "No Request" 1 "Maximum Limit" 2 "Minimum Limit" ;
VAL_ 46 Sig7626 0 "No Request" 1 "Maximum Limit" 2 "Minimum Limit" ;
VAL_ 46 Sig7624 0 "Inactive" 1 "Pleasability Limited" 2 "Maximum Range" 3 "Automatic Actuator Selection" ;
VAL_ 102 VICMI3P_AccPPS1OORFltAuth 0 "FALSE" 1 "TRUE" ;
VAL_ 102 VICMI3P_AccPPS1OORErrCmpstAuth 0 "FALSE" 1 "TRUE" ;
VAL_ 102 EDActr4DischrgCmdAuth 0 "No Action" 1 "Normal" 2 "Immediate" 3 "Emergency" ;
VAL_ 102 EDActr3DischrgCmdAuth 0 "No Action" 1 "Normal" 2 "Immediate" 3 "Emergency" ;
VAL_ 102 VICMI3P_AccPPS2OORFltCmpstAuth 0 "FALSE" 1 "TRUE" ;
VAL_ 102 VICMI3P_AccPPS2OORErrCmpstAuth 0 "FALSE" 1 "TRUE" ;
VAL_ 102 VICMI3P_AccPPS1n2DsgrFltAuth 0 "FALSE" 1 "TRUE" ;
VAL_ 102 VICMI3P_AccPPS1n2DsgrErrAuth 0 "FALSE" 1 "TRUE" ;
VAL_ 102 VICMI3P_AccPPS1OORFltCmpstAuth 0 "FALSE" 1 "TRUE" ;
VAL_ 102 VICMI3P_ArbdAccPPRedntFltAuth 0 "FALSE" 1 "TRUE" ;
VAL_ 102 ElecTransRngHVBkupSplyFltPrAuth 0 "FALSE" 1 "TRUE" ;
VAL_ 102 PrplSysInvrtACoolTempAuth_Inv 0 "FALSE" 1 "TRUE" ;
VAL_ 102 PrplSysInvrtBCoolTempAuth_Inv 0 "FALSE" 1 "TRUE" ;
VAL_ 102 PrplSysInvrtCCoolTempAuth_Inv 0 "FALSE" 1 "TRUE" ;
VAL_ 96 PrplSysMtrASpdAuth_Inv 0 "FALSE" 1 "TRUE" ;
VAL_ 91 RrStrgActlModeAuth 0 "Automatic" 1 "Fixed" 2 "Crab" 3 "None" ;
VAL_ 91 RrStrgOprtlStsAuth 0 "Unknown" 1 "Normal" 2 "Temporarily Unavailable" 3 "Reduced Performance" 4 "Failed" 5 "Normal & Active Safety Control" 6 "Reserved" ;
VAL_ 91 RrStrgAlgnCmpltAuth 0 "FALSE" 1 "TRUE" ;
VAL_ 91 RrStrgActlPerfMode 0 "No Action" 1 "Normal" 2 "Sport" 3 "Comfort" 4 "Track" 5 "Tow/Haul" 6 "City/Offroad" 7 "Terrain" ;
VAL_ 91 RrStrgRdWhlAngAuth_Inv 0 "FALSE" 1 "TRUE" ;
VAL_ 91 RrStrgRdWhlAngAuth_DuD 0 "FALSE" 1 "TRUE" ;
VAL_ 715 LIB1DS1_DTCSts 0 "Not Supported" 1 "No Status to Report" 2 "Diagnostic Passed" 3 "Diagnostic Failed" ;
VAL_ 715 LIB1DS2_DTCSts 0 "Not Supported" 1 "No Status to Report" 2 "Diagnostic Passed" 3 "Diagnostic Failed" ;
VAL_ 715 LIB1DS3_DTCSts 0 "Not Supported" 1 "No Status to Report" 2 "Diagnostic Passed" 3 "Diagnostic Failed" ;
VAL_ 83 ArbdStrgFtrReqActvAuth 0 "None" 1 "ESC" 2 "APA" 3 "LKA" 4 "LCC" 5 "TJA" 6 "HOLF" 7 "LCP" 8 "SAA" 9 "CAS" 10 "LCOD" ;
VAL_ 83 DrvrAppStrgTrqAuth_Inv 0 "FALSE" 1 "TRUE" ;
VAL_ 83 StrgWhlHndsOffDtnStatAuth 0 "Hands On" 1 "Hands Off" 2 "Unknown" ;
VAL_ 83 StrgWhlHndsOffDtnModeAuth 0 "Disabled" 1 "Enabled" 2 "Failed" 3 "Unknown" ;
VAL_ 83 StrgWhlHndsOffDtnCnfdLvlAuth 0 "Low" 1 "High" 2 "Unknown" ;
VAL_ 83 DrvrStrgIntfrDtdAuth_Inv 0 "FALSE" 1 "TRUE" ;
VAL_ 83 DrvrStrgIntfrDtdAuth 0 "FALSE" 1 "TRUE" ;
VAL_ 627 ArbdActvSftyStrgReqCommStsAuth 0 "Unknown" 1 "Normal Communication Request Active" 2 "Normal Communication Request Active Fault Pending" 3 "Normal Communication Request Inactive" 4 "Normal Communication Request Inactive Fault Pending" 5 "Failed Communication" ;
VAL_ 627 AE44StrgReqCommStsAuth 0 "Unknown" 1 "Normal Active" 2 "Normal Inactive" 3 "Failed Communication" ;
VAL_ 627 LnKpAsstStrgReqCommStsAuth 0 "Unknown" 1 "Normal Active" 2 "Normal Inactive" 3 "Failed Communication" ;
VAL_ 627 ElecPSTrqOvrlyStsAuth 0 "Unknown" 1 "Temporarily Inhibited" 2 "Inactive" 3 "Active" 4 "Temporarily Limited" 5 "Failed" ;
VAL_ 627 ElecPSOvrlyTrqDlvdAuth_Inv 0 "FALSE" 1 "TRUE" ;
VAL_ 64 ElecPSTotTrqDlvdAuth_Inv 0 "FALSE" 1 "TRUE" ;
VAL_ 626 StrgPerfActlModeAuth 0 "No Action" 1 "Normal" 2 "Sport" 3 "Comfort" 4 "Track" 5 "Tow_Haul" 6 "Offroad" 7 "Terrain" ;
VAL_ 626 StrgAsstThrmlInhbdAuth 0 "FALSE" 1 "TRUE" ;
VAL_ 626 StrgAsstStsAuth 0 "Normal" 1 "Reduced" 2 "Unavailable" ;
VAL_ 626 StrgWhlTrqIntegStsAuth 0 "Unknown" 1 "Redundant ASIL D" 2 "Non Redundant ASIL D" 3 "Failed" ;
VAL_ 626 StrgWhlAngIntegStsAuth 0 "Unknown" 1 "Redundant ASIL D" 2 "Non Redundant ASIL D" 3 "Failed" ;
VAL_ 1316 TDAP_TeenDrvrActvAuth 0 "FALSE" 1 "TRUE" ;
VAL_ 1316 RIP_RmtIgnBlkImbCustClrCmdAuth 0 "FALSE" 1 "TRUE" ;
VAL_ 1316 RIP_NewFobXmtrLrndNtfnAuth 0 "FALSE" 1 "TRUE" ;
VAL_ 1316 FTPP_VirtCtlHdPrkLmpsAvalAuth 0 "Not Available" 1 "Available" ;
VAL_ 1316 FTPP_HdPrkLmpsCurrSeltnValAuth 0 "Unknown" 1 "Off" 2 "Auto" 3 "Parking" 4 "On" ;
VAL_ 1316 VMMP_VehMtnMvmtStatAuth 0 "Parked" 1 "Neutral" 2 "Forward" 3 "Reverse" 4 "Invalid" ;
VAL_ 1316 VKI2P_FobAvlStsAuth 0 "No Action" 1 "Disabled" 2 "Enabled" 3 "Fail" ;
VAL_ 1316 AuthIntrUserIdDevSts 0 "Idle" 1 "Auth In Process" 2 "Auth In Process_Single Authenticated" 3 "Auth Complete_Not Authenticated" 4 "Auth Complete_Authenticated" 5 "Auth Complete_Undetermined" ;
VAL_ 533 E49ModeActv 0 "FALSE" 1 "TRUE" ;
VAL_ 1171 RrStrgModeDispIndReq 0 "None" 1 "Automatic" 2 "Fixed" 3 "Crab" 4 "Crab Pending" 5 "Crab Ready" ;
VAL_ 1171 RrStrgFlrIndOn 0 "FALSE" 1 "TRUE" ;
VAL_ 1283 PnCActnReqCertfctTypAuth 0 "None" 1 "GM Provisioning Certificate" 2 "Contract Certificate" 3 "V2G Root Certificate" 4 "OCSP Certificate" 5 "Private Operator Root Certificate" 6 "Reserved1" 7 "Reserved2" 8 "Reserved3" 9 "Reserved4" 10 "Reserved5" 11 "Reserved6" 12 "Reserved7" 13 "Reserved8" 14 "All Contract And Private Operator Root Certificates" ;
VAL_ 1283 PnCActnReqCertfctOpAuth 0 "No Action" 1 "Disable Certificate" 2 "Enable Certificate" 3 "Erase Certificate" 4 "Install Certificate" ;
VAL_ 1283 PnCEnblReqAuth 0 "Unknown" 1 "No Action" 2 "Enable" 3 "Disable" ;
VAL_ 1478 CCCGI_FrtBlwFanSpdFdbkRtlzd_Inv 0 "FALSE" 1 "TRUE" ;
VAL_ 1478 ClmCtlCbnFrtEvpCoolPwrReq_DuD 0 "FALSE" 1 "TRUE" ;
VAL_ 1478 ClmCtlCbnRecircAirFlapPstn_Inv 0 "FALSE" 1 "TRUE" ;
VAL_ 1280 RmtProgPstInstlClnupActvAuth 0 "FALSE" 1 "TRUE" ;
VAL_ 1280 RmtProgInstlPndgActvAuth 0 "FALSE" 1 "TRUE" ;
VAL_ 597 SuprRmtPrkVirtKeyPrkCmdAuth 0 "No Action" 1 "Initiate Parking" 2 "Pause Parking" 3 "Continue Parking" 4 "Resume Parking" 5 "Continue Unparking" ;
VAL_ 597 SuprRmtPrkVirtKeyEntlmtStsAuth 0 "Not Granted" 1 "Granted" ;
VAL_ 597 VirtKeyMblDevLocZnAuth 0 "No Action" 1 "Inside Vehicle" 2 "Outside and Within Localization Area" 3 "Outside of Localization Area" 4 "Invalid" ;
VAL_ 864 Sig4931 0 "FALSE" 1 "TRUE" ;
VAL_ 864 Sig4930 0 "FALSE" 1 "TRUE" ;
VAL_ 84 SWIP_StrgWhlAngAuth_DuD 0 "FALSE" 1 "TRUE" ;
VAL_ 84 SWIP_StrgWhlAngCalStsAuth 0 "Unknown" 1 "Estimated" 2 "Calibrated" ;
VAL_ 84 SWIP_StrgWhlAngAuth_Inv 0 "FALSE" 1 "TRUE" ;
VAL_ 878 RIP_PreRelAllwdAuth 0 "FALSE" 1 "TRUE" ;
VAL_ 878 RIP_ElecStrgColUnlckAllwdAuth 0 "FALSE" 1 "TRUE" ;
VAL_ 878 BGI1P_RmtVehStrtReqAuth 0 "FALSE" 1 "TRUE" ;
VAL_ 878 BGI1P_RmtStrtStsAuth 0 "Inactive" 1 "Active" ;
VAL_ 878 SPMP_PriRunCrnkCmdActvAuth 0 "FALSE" 1 "TRUE" ;
VAL_ 878 RIP_StrtStopIgnSwPrssdAuth 0 "FALSE" 1 "TRUE" ;
VAL_ 878 RIP_StrtStopIgnSwPrssdAuth_Inv 0 "FALSE" 1 "TRUE" ;
VAL_ 878 SPMP_SysPwrModeAuth_Inv 0 "FALSE" 1 "TRUE" ;
VAL_ 878 SPMP_SysPwrModeAuth 0 "Off" 1 "Accessory" 2 "Run" 3 "Start Request" 4 "Propulsion" ;
VAL_ 878 SPMP_PriRunCrnkCmdActvAuth_Inv 0 "FALSE" 1 "TRUE" ;
VAL_ 2147745824 Sig7516 0 "FALSE" 1 "TRUE" ;
VAL_ 2147745825 Sig7517 0 "FALSE" 1 "TRUE" ;
VAL_ 1299 TGPSDSP_UTCMonthAuth 0 "Unknown" 1 "January" 2 "February" 3 "March" 4 "April" 5 "May" 6 "June" 7 "July" 8 "August" 9 "September" 10 "October" 11 "November" 12 "December" ;
VAL_ 1299 TGPSDSP_UTCDyAuth_Inv 0 "FALSE" 1 "TRUE" ;
VAL_ 1299 TGPSDSP_UTCMonthAuth_Inv 0 "FALSE" 1 "TRUE" ;
VAL_ 1299 TGPSDSP_DateSrcAuth 0 "Signal_Unavailable" 1 "Synchronized_RTC_Used_And_GPS_Unavailable" 2 "GPS" 3 "Cellular" ;
VAL_ 1299 TGPSDSP_UTCYrAuth_Inv 0 "FALSE" 1 "TRUE" ;
VAL_ 1299 TGPSDSP_DateSrcAuth_Inv 0 "FALSE" 1 "TRUE" ;
VAL_ 865 TGPSTSP_TmSrcAuth_Inv 0 "FALSE" 1 "TRUE" ;
VAL_ 865 TGPSTSP_TmSrcAuth 0 "Signal_Unavailable" 1 "Synchronized_RTC_Used_And_GPS_Unavailable" 2 "GPS" 3 "Cellular" ;
VAL_ 865 TGPSTSP_UTCHrsAuth_Inv 0 "FALSE" 1 "TRUE" ;
VAL_ 865 TGPSTSP_UTCSecsAuth_Inv 0 "FALSE" 1 "TRUE" ;
VAL_ 865 TGPSTSP_UTCMinsAuth_Inv 0 "FALSE" 1 "TRUE" ;
VAL_ 50 TEGP_TrnsEstGrAuth 0 "Not Supported" 1 "First Gear" 2 "Second Gear" 3 "Third Gear" 4 "Fourth Gear" 5 "Fifth Gear" 6 "Sixth Gear" 7 "Seventh Gear" 8 "Eighth Gear" 9 "Ninth Gear" 10 "Tenth Gear" 11 "Unused and Reserved" 12 "CVT Forward Gear" 13 "Neutral Gear" 14 "Reverse Gear" 15 "Park Gear" ;
VAL_ 50 TEGP_TrnsEngdStAuth_Inv 0 "FALSE" 1 "TRUE" ;
VAL_ 50 TEGP_TrnsEngdStAuth 0 "Transmission Not Engaged" 1 "Transmission Engaged in Forward" 2 "Transmission Engaged in Reverse" 3 "Operating State Not Reached" ;
VAL_ 50 TEGP_TransCmndGrAuth 0 "Not Supported" 1 "First Gear" 2 "Second Gear" 3 "Third Gear" 4 "Fourth Gear" 5 "Fifth Gear" 6 "Sixth Gear" 7 "Seventh Gear" 8 "Eighth Gear" 9 "Ninth Gear" 10 "Tenth Gear" 11 "Unused and Reserved" 12 "CVT Forward Gear" 13 "Neutral Gear" 14 "Reverse Gear" 15 "Park Gear" ;
VAL_ 50 TEGP_TrnsShftLvrPstnAuth 0 "Between Ranges" 1 "Park Range" 2 "Reverse Range" 3 "Neutral Range" 4 "Forward Range A" 5 "Forward Range B" 6 "Forward Range C" 7 "Forward Range D" 8 "Forward Range E" 9 "Forward Range F" 10 "Forward Range G" 11 "Forward Range H" 12 "Forward Range I" 13 "Forward Range J" 14 "Lever Position Unknown" ;
VAL_ 50 TEGP_TrnsEstGrAuth_Inv 0 "FALSE" 1 "TRUE" ;
VAL_ 50 TEGP_TrnsShftLvrPstnAuth_Inv 0 "FALSE" 1 "TRUE" ;
VAL_ 45 Sig7538 0 "FALSE" 1 "TRUE" ;
VAL_ 527 TCIP_AxlEstdTrqLRAuth_Inv 0 "FALSE" 1 "TRUE" ;
VAL_ 527 TCIP_AxlStsRrAuth 0 "Normal" 1 "Temporary Inhibit" 2 "Temporary Limited" 3 "Permanently Failed" ;
VAL_ 527 TCIP_AxlEstdTrqRRAuth_Inv 0 "FALSE" 1 "TRUE" ;
VAL_ 2147745826 Sig7850 0 "FALSE" 1 "TRUE" ;
VAL_ 2147745827 Sig7852 0 "FALSE" 1 "TRUE" ;
VAL_ 2147745806 VICM_CAN2_ClscCANHrtBtActv 0 "FALSE" 1 "TRUE" ;
VAL_ 621 VICMI1P_AutoDrvShfSysStsPriAuth 0 "Unknown" 1 "Shift In Progress" 2 "Control Override" 3 "Error" 4 "Standby" ;
VAL_ 621 VICMI1P_ADShfSysHlthStsPriAuth 0 "Unknown" 1 "Normal" 2 "Degraded Functional" 3 "Failed in Range Functional" 4 "Failed Defaulted" ;
VAL_ 621 VICMI1P_AuxPwrModStsAuth 0 "NormConvNormTempLo" 1 "NormConvNormTempHi" 2 "Derated" 3 "HighTempNearDerated" 4 "Dsbld" 5 "HiTempDsbldDerated" 6 "Indeterminate" 7 "CommandedOff" 8 "OverTempConvDerated" ;
VAL_ 1298 UpftrRmtVehStrtReqd 0 "FALSE" 1 "TRUE" ;
VAL_ 1298 UpftrSnwPlwLoBmDsblReqd 0 "FALSE" 1 "TRUE" ;
VAL_ 1298 VODVP_VehOdoDispValAuth_Inv 0 "FALSE" 1 "TRUE" ;
VAL_ 614 VSADP_RdcdPwrIndOnAuth 0 "FALSE" 1 "TRUE" ;
VAL_ 614 VSADP_FuelModeStsAuth 0 "Unknown" 1 "Gasoline Mode" 2 "Natural Gas Mode" 3 "Liquified Petroleum Gas Mode" 4 "Alternative Fuel Cut-off Active" ;
VAL_ 614 EngEmsRltMlfIndRq 0 "Continuous Indication" 1 "No Indication" 2 "Flashing 1 Hertz Indication" 3 "Flashing 2 Hertz Indication" 4 "Flashing 0.5 Hertz Indication" ;
VAL_ 614 VSADP_VehSpdAvgDrvnSrcAuth 0 "Transmission Output Speed" 1 "Wheel Speed" ;
VAL_ 614 VSADP_VehSpdAvgDrvnAuth_Inv 0 "FALSE" 1 "TRUE" ;
VAL_ 610 VSANDP_VehSpdAvgNDrvnAuth_Inv 0 "FALSE" 1 "TRUE" ;
VAL_ 1303 Sig7896 0 "Unknown" 1 "Not Connected" 2 "Connected" ;
VAL_ 1303 Sig7895 0 "Unknown" 1 "Not Connected" 2 "Connected" ;
VAL_ 620 XCGIP_SecAxlPrkBrkAppReqdAuth 0 "FALSE" 1 "TRUE" ;
